VERSION ""

NS_ :

BS_:

BU_: WPC2 PSB SHVU_RR vHS_B2 FCS EMCU SLB GW_APSU GW_DLBCU RCM ARS CGW_CCU vDummy_HS_B GW_RLPSU ATS RLHV SGU PFSU GW_RRPSU ALBCU DSAU SWRC SHVU_FR RCS GW_DPSU BLTN_CAM SCM OHCL RWPC RRHV WPC HOD ASAU

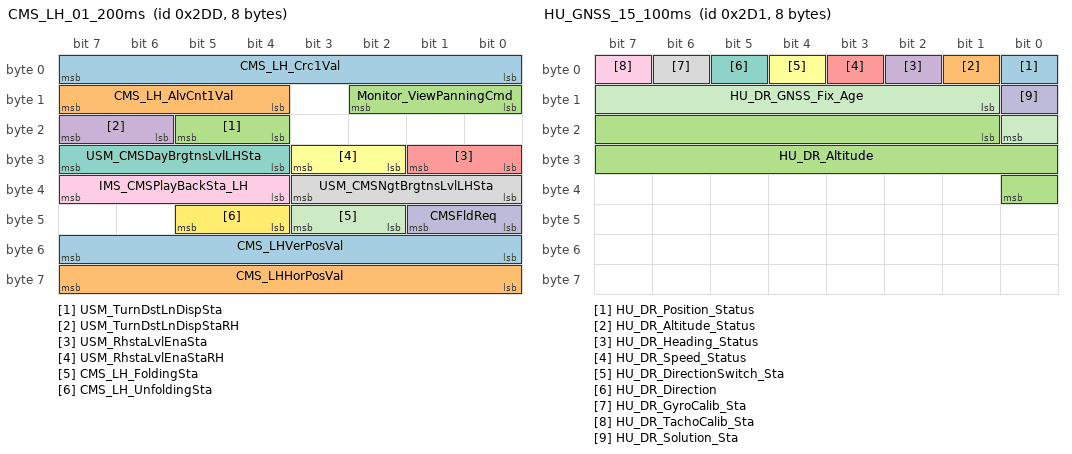
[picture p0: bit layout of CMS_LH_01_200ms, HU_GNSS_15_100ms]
BO_ 733 CMS_LH_01_200ms: 8 CGW_CCU
 SG_ CMS_LH_Crc1Val : 0|8@1+ (1,0) [0|0] ""  Vector__XXX
 SG_ CMS_LH_AlvCnt1Val : 12|4@1+ (1,0) [0|0] ""  Vector__XXX
 SG_ USM_TurnDstLnDispSta : 20|2@1+ (1,0) [0|0] ""  Vector__XXX
 SG_ USM_TurnDstLnDispStaRH : 22|2@1+ (1,0) [0|0] ""  Vector__XXX
 SG_ USM_RhstaLvlEnaSta : 24|2@1+ (1,0) [0|0] ""  Vector__XXX
 SG_ USM_RhstaLvlEnaStaRH : 26|2@1+ (1,0) [0|0] ""  Vector__XXX
 SG_ USM_CMSDayBrgtnsLvlLHSta : 28|4@1+ (1,0) [0|0] ""  Vector__XXX
 SG_ USM_CMSNgtBrgtnsLvlLHSta : 32|4@1+ (1,0) [0|0] ""  Vector__XXX
 SG_ IMS_CMSPlayBackSta_LH : 36|4@1+ (1,0) [0|0] ""  GW_DPSU
 SG_ CMSFldReq : 40|2@1+ (1,0) [0|0] ""  Vector__XXX
 SG_ CMS_LH_FoldingSta : 42|2@1+ (1,0) [0|0] ""  Vector__XXX
 SG_ CMS_LH_UnfoldingSta : 44|2@1+ (1,0) [0|0] ""  Vector__XXX
 SG_ CMS_LHVerPosVal : 48|8@1+ (0.02,0) [0|0] "V"  Vector__XXX
 SG_ CMS_LHHorPosVal : 56|8@1+ (0.02,0) [0|0] "V"  Vector__XXX
 SG_ Monitor_ViewPanningCmd : 8|3@1+ (1,0) [0|0] ""  Vector__XXX

BO_ 721 HU_GNSS_15_100ms: 8 CGW_CCU
 SG_ HU_DR_Position_Status : 0|1@1+ (1,0) [0|0] ""  Vector__XXX
 SG_ HU_DR_Altitude_Status : 1|1@1+ (1,0) [0|0] ""  Vector__XXX
 SG_ HU_DR_Altitude : 17|16@1- (1,0) [0|0] "m"  BLTN_CAM
 SG_ HU_DR_Heading_Status : 2|1@1+ (1,0) [0|0] ""  Vector__XXX
 SG_ HU_DR_Speed_Status : 3|1@1+ (1,0) [0|0] ""  Vector__XXX
 SG_ HU_DR_DirectionSwitch_Sta : 4|1@1+ (1,0) [0|0] ""  Vector__XXX
 SG_ HU_DR_Direction : 5|1@1+ (1,0) [0|0] ""  Vector__XXX
 SG_ HU_DR_GyroCalib_Sta : 6|1@1+ (1,0) [0|0] ""  Vector__XXX
 SG_ HU_DR_TachoCalib_Sta : 7|1@1+ (1,0) [0|0] ""  Vector__XXX
 SG_ HU_DR_Solution_Sta : 8|1@1+ (1,0) [0|0] ""  Vector__XXX
 SG_ HU_DR_GNSS_Fix_Age : 9|8@1+ (1,0) [0|0] "Sec"  Vector__XXX

BO_ 722 HU_GNSS_16_100ms: 8 CGW_CCU
 SG_ HU_DR_Latitude : 0|32@1- (1,0) [0|0] "¢ª"  BLTN_CAM
 SG_ HU_DR_Longitude : 32|32@1- (1,0) [0|0] "¢ª"  BLTN_CAM

BO_ 723 HU_GNSS_17_100ms: 8 CGW_CCU
 SG_ HU_DR_Heading : 0|16@1+ (1,0) [0|0] "¢ª"  BLTN_CAM
 SG_ HU_DR_Speed : 16|16@1- (0.01,0) [0|0] "m/s"  Vector__XXX

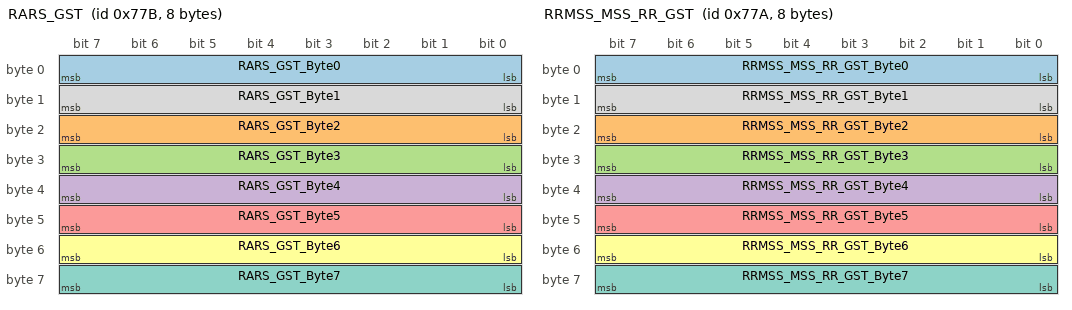
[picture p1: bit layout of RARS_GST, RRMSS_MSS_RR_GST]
BO_ 1915 RARS_GST: 8 ARS
 SG_ RARS_GST_Byte0 : 0|8@1+ (1,0) [0|0] ""  CGW_CCU
 SG_ RARS_GST_Byte2 : 16|8@1+ (1,0) [0|0] ""  CGW_CCU
 SG_ RARS_GST_Byte3 : 24|8@1+ (1,0) [0|0] ""  CGW_CCU
 SG_ RARS_GST_Byte4 : 32|8@1+ (1,0) [0|0] ""  CGW_CCU
 SG_ RARS_GST_Byte5 : 40|8@1+ (1,0) [0|0] ""  CGW_CCU
 SG_ RARS_GST_Byte6 : 48|8@1+ (1,0) [0|0] ""  CGW_CCU
 SG_ RARS_GST_Byte7 : 56|8@1+ (1,0) [0|0] ""  CGW_CCU
 SG_ RARS_GST_Byte1 : 8|8@1+ (1,0) [0|0] ""  CGW_CCU

BO_ 1914 RRMSS_MSS_RR_GST: 8 GW_RRPSU
 SG_ RRMSS_MSS_RR_GST_Byte0 : 0|8@1+ (1,0) [0|0] ""  CGW_CCU
 SG_ RRMSS_MSS_RR_GST_Byte2 : 16|8@1+ (1,0) [0|0] ""  CGW_CCU
 SG_ RRMSS_MSS_RR_GST_Byte3 : 24|8@1+ (1,0) [0|0] ""  CGW_CCU
 SG_ RRMSS_MSS_RR_GST_Byte4 : 32|8@1+ (1,0) [0|0] ""  CGW_CCU
 SG_ RRMSS_MSS_RR_GST_Byte5 : 40|8@1+ (1,0) [0|0] ""  CGW_CCU
 SG_ RRMSS_MSS_RR_GST_Byte6 : 48|8@1+ (1,0) [0|0] ""  CGW_CCU
 SG_ RRMSS_MSS_RR_GST_Byte7 : 56|8@1+ (1,0) [0|0] ""  CGW_CCU
 SG_ RRMSS_MSS_RR_GST_Byte1 : 8|8@1+ (1,0) [0|0] ""  CGW_CCU

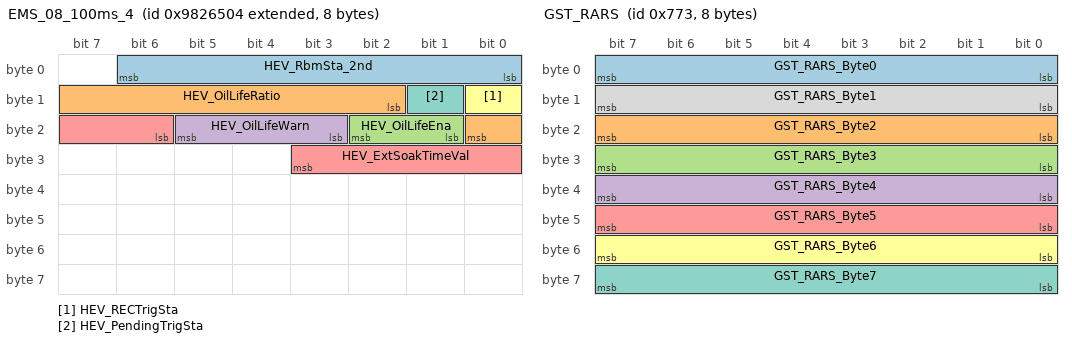
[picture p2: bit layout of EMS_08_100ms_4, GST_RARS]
BO_ 2307024132 EMS_08_100ms_4: 8 CGW_CCU
 SG_ HEV_RbmSta_2nd : 0|7@1+ (1,0) [0|0] ""  Vector__XXX
 SG_ HEV_OilLifeRatio : 10|7@1+ (1,0) [0|0] "%"  Vector__XXX
 SG_ HEV_OilLifeEna : 17|2@1+ (1,0) [0|0] ""  Vector__XXX
 SG_ HEV_OilLifeWarn : 19|3@1+ (1,0) [0|0] ""  Vector__XXX
 SG_ HEV_ExtSoakTimeVal : 22|6@1+ (5,0) [0|0] ""  Vector__XXX
 SG_ HEV_RECTrigSta : 8|1@1+ (1,0) [0|0] ""  Vector__XXX
 SG_ HEV_PendingTrigSta : 9|1@1+ (1,0) [0|0] ""  Vector__XXX

BO_ 1907 GST_RARS: 8 CGW_CCU
 SG_ GST_RARS_Byte0 : 0|8@1+ (1,0) [0|0] ""  ARS
 SG_ GST_RARS_Byte2 : 16|8@1+ (1,0) [0|0] ""  ARS
 SG_ GST_RARS_Byte3 : 24|8@1+ (1,0) [0|0] ""  ARS
 SG_ GST_RARS_Byte4 : 32|8@1+ (1,0) [0|0] ""  ARS
 SG_ GST_RARS_Byte5 : 40|8@1+ (1,0) [0|0] ""  ARS
 SG_ GST_RARS_Byte6 : 48|8@1+ (1,0) [0|0] ""  ARS
 SG_ GST_RARS_Byte7 : 56|8@1+ (1,0) [0|0] ""  ARS
 SG_ GST_RARS_Byte1 : 8|8@1+ (1,0) [0|0] ""  ARS

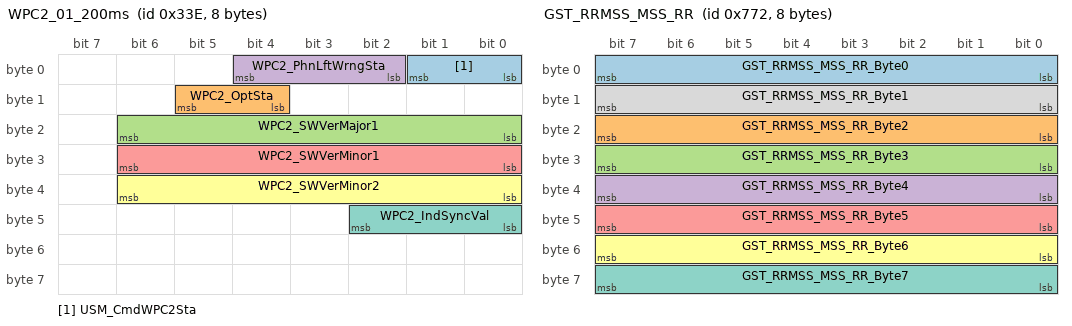
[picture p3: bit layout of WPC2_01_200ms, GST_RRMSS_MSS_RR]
BO_ 830 WPC2_01_200ms: 8 WPC2
 SG_ USM_CmdWPC2Sta : 0|2@1+ (1,0) [0|0] ""  CGW_CCU
 SG_ WPC2_OptSta : 12|2@1+ (1,0) [0|0] ""  CGW_CCU
 SG_ WPC2_SWVerMajor1 : 16|7@1+ (1,0) [0|0] ""  CGW_CCU
 SG_ WPC2_PhnLftWrngSta : 2|3@1+ (1,0) [0|0] ""  CGW_CCU
 SG_ WPC2_SWVerMinor1 : 24|7@1+ (1,0) [0|0] ""  CGW_CCU
 SG_ WPC2_SWVerMinor2 : 32|7@1+ (1,0) [0|0] ""  CGW_CCU
 SG_ WPC2_IndSyncVal : 40|3@1+ (1,0) [0|0] ""  RWPC,WPC

BO_ 1906 GST_RRMSS_MSS_RR: 8 CGW_CCU
 SG_ GST_RRMSS_MSS_RR_Byte0 : 0|8@1+ (1,0) [0|0] ""  GW_RRPSU
 SG_ GST_RRMSS_MSS_RR_Byte2 : 16|8@1+ (1,0) [0|0] ""  GW_RRPSU
 SG_ GST_RRMSS_MSS_RR_Byte3 : 24|8@1+ (1,0) [0|0] ""  GW_RRPSU
 SG_ GST_RRMSS_MSS_RR_Byte4 : 32|8@1+ (1,0) [0|0] ""  GW_RRPSU
 SG_ GST_RRMSS_MSS_RR_Byte5 : 40|8@1+ (1,0) [0|0] ""  GW_RRPSU
 SG_ GST_RRMSS_MSS_RR_Byte6 : 48|8@1+ (1,0) [0|0] ""  GW_RRPSU
 SG_ GST_RRMSS_MSS_RR_Byte7 : 56|8@1+ (1,0) [0|0] ""  GW_RRPSU
 SG_ GST_RRMSS_MSS_RR_Byte1 : 8|8@1+ (1,0) [0|0] ""  GW_RRPSU

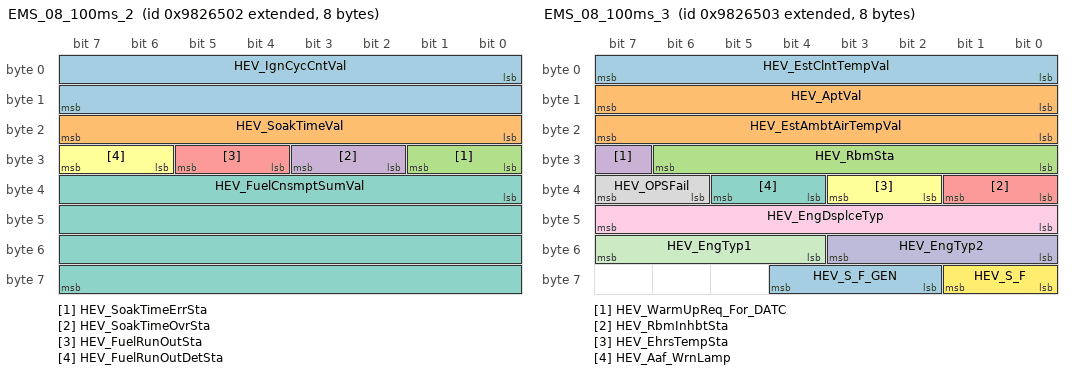
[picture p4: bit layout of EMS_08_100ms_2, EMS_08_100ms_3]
BO_ 2307024130 EMS_08_100ms_2: 8 CGW_CCU
 SG_ HEV_IgnCycCntVal : 0|16@1+ (1,0) [0|0] ""  Vector__XXX
 SG_ HEV_SoakTimeVal : 16|8@1+ (1,0) [0|0] "Min"  Vector__XXX
 SG_ HEV_SoakTimeErrSta : 24|2@1+ (1,0) [0|0] ""  Vector__XXX
 SG_ HEV_SoakTimeOvrSta : 26|2@1+ (1,0) [0|0] ""  Vector__XXX
 SG_ HEV_FuelRunOutSta : 28|2@1+ (1,0) [0|0] ""  Vector__XXX
 SG_ HEV_FuelRunOutDetSta : 30|2@1+ (1,0) [0|0] ""  Vector__XXX
 SG_ HEV_FuelCnsmptSumVal : 32|32@1+ (1.280018E-4,0) [0|0] "ml"  Vector__XXX

BO_ 2307024131 EMS_08_100ms_3: 8 CGW_CCU
 SG_ HEV_EstClntTempVal : 0|8@1+ (0.75,-48) [0|0] "¡É"  Vector__XXX
 SG_ HEV_EstAmbtAirTempVal : 16|8@1+ (0.75,-48) [0|0] "¡É"  Vector__XXX
 SG_ HEV_RbmSta : 24|7@1+ (1,0) [0|0] ""  Vector__XXX
 SG_ HEV_WarmUpReq_For_DATC : 31|1@1+ (1,0) [0|0] ""  Vector__XXX
 SG_ HEV_RbmInhbtSta : 32|2@1+ (1,0) [0|0] ""  Vector__XXX
 SG_ HEV_EhrsTempSta : 34|2@1+ (1,0) [0|0] ""  Vector__XXX
 SG_ HEV_Aaf_WrnLamp : 36|2@1+ (1,0) [0|0] ""  Vector__XXX
 SG_ HEV_OPSFail : 38|2@1+ (1,0) [0|0] ""  Vector__XXX
 SG_ HEV_EngDsplceTyp : 40|8@1+ (0.1,0) [0|0] "liter"  Vector__XXX
 SG_ HEV_EngTyp2 : 48|4@1+ (1,0) [0|0] ""  Vector__XXX
 SG_ HEV_EngTyp1 : 52|4@1+ (1,0) [0|0] ""  Vector__XXX
 SG_ HEV_S_F : 56|2@1+ (1,0) [0|0] ""  Vector__XXX
 SG_ HEV_S_F_GEN : 58|3@1+ (1,0) [0|0] ""  Vector__XXX
 SG_ HEV_AptVal : 8|8@1+ (2,0) [0|0] "PSI"  Vector__XXX

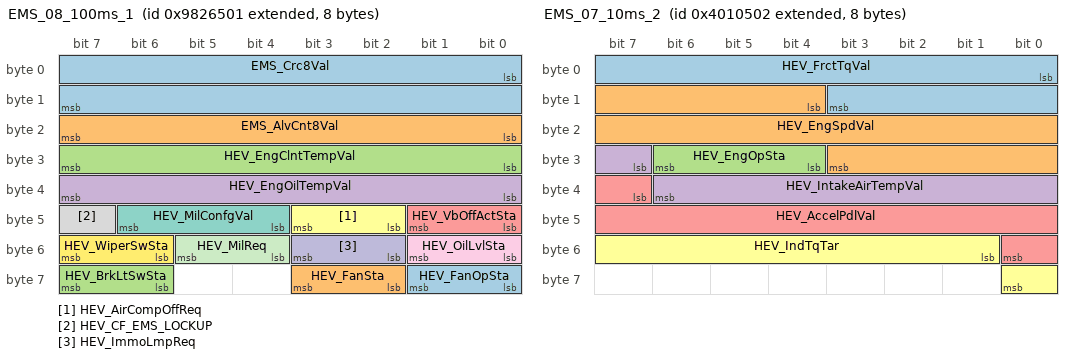
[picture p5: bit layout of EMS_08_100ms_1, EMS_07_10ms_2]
BO_ 2307024129 EMS_08_100ms_1: 8 CGW_CCU
 SG_ EMS_Crc8Val : 0|16@1+ (1,0) [0|0] ""  Vector__XXX
 SG_ EMS_AlvCnt8Val : 16|8@1+ (1,0) [0|0] ""  Vector__XXX
 SG_ HEV_EngClntTempVal : 24|8@1+ (0.75,-48) [0|0] "¡É"  Vector__XXX
 SG_ HEV_EngOilTempVal : 32|8@1+ (1,-40) [0|0] "¡É"  Vector__XXX
 SG_ HEV_VbOffActSta : 40|2@1+ (1,0) [0|0] ""  Vector__XXX
 SG_ HEV_AirCompOffReq : 42|2@1+ (1,0) [0|0] ""  Vector__XXX
 SG_ HEV_MilConfgVal : 44|3@1+ (1,0) [0|0] ""  Vector__XXX
 SG_ HEV_CF_EMS_LOCKUP : 47|1@1+ (1,0) [0|0] ""  Vector__XXX
 SG_ HEV_OilLvlSta : 48|2@1+ (1,0) [0|0] ""  Vector__XXX
 SG_ HEV_ImmoLmpReq : 50|2@1+ (1,0) [0|0] ""  Vector__XXX
 SG_ HEV_MilReq : 52|2@1+ (1,0) [0|0] ""  Vector__XXX
 SG_ HEV_WiperSwSta : 54|2@1+ (1,0) [0|0] ""  Vector__XXX
 SG_ HEV_FanOpSta : 56|2@1+ (1,0) [0|0] ""  Vector__XXX
 SG_ HEV_FanSta : 58|2@1+ (1,0) [0|0] ""  Vector__XXX
 SG_ HEV_BrkLtSwSta : 62|2@1+ (1,0) [0|0] ""  BLTN_CAM

BO_ 2214659332 EMS_07_10ms_4: 8 CGW_CCU

BO_ 2214659331 EMS_07_10ms_3: 8 CGW_CCU

BO_ 2214659330 EMS_07_10ms_2: 8 CGW_CCU
 SG_ HEV_FrctTqVal : 0|12@1+ (0.1,0) [0|0] "Nm"  Vector__XXX
 SG_ HEV_EngSpdVal : 12|16@1+ (0.25,0) [0|0] "rpm"  Vector__XXX
 SG_ HEV_EngOpSta : 28|3@1+ (1,0) [0|0] ""  PFSU,RWPC,WPC,WPC2
 SG_ HEV_IntakeAirTempVal : 31|8@1+ (0.75,-48) [0|0] "¡É"  Vector__XXX
 SG_ HEV_AccelPdlVal : 39|10@1+ (0.09784,0) [0|0] "%"  BLTN_CAM
 SG_ HEV_IndTqTar : 49|8@1+ (0.3906,0) [0|0] "%"  Vector__XXX

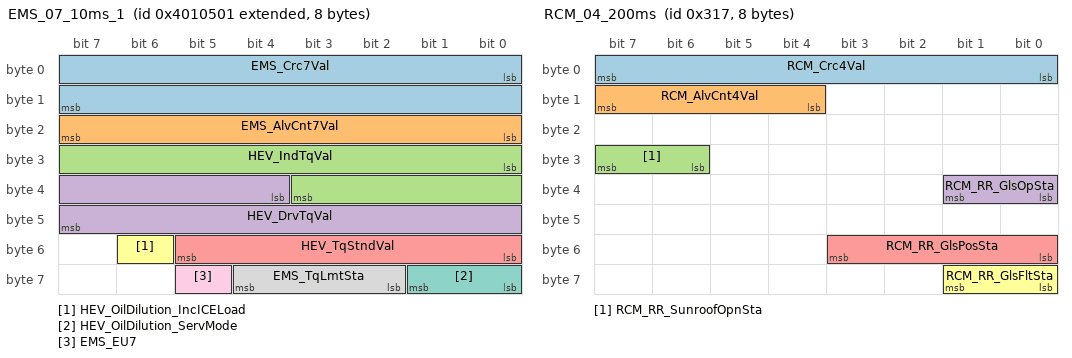
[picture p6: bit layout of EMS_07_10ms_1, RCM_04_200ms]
BO_ 2214659329 EMS_07_10ms_1: 8 CGW_CCU
 SG_ EMS_Crc7Val : 0|16@1+ (1,0) [0|0] ""  Vector__XXX
 SG_ EMS_AlvCnt7Val : 16|8@1+ (1,0) [0|0] ""  Vector__XXX
 SG_ HEV_IndTqVal : 24|12@1+ (0.1,0) [0|0] "Nm"  Vector__XXX
 SG_ HEV_DrvTqVal : 36|12@1+ (0.390625,0) [0|0] "%"  Vector__XXX
 SG_ HEV_TqStndVal : 48|6@1+ (10,0) [0|0] "Nm"  Vector__XXX
 SG_ HEV_OilDilution_IncICELoad : 54|1@1+ (1,0) [0|0] ""  Vector__XXX
 SG_ HEV_OilDilution_ServMode : 56|2@1+ (1,0) [0|0] ""  Vector__XXX
 SG_ EMS_TqLmtSta : 58|3@1+ (1,0) [0|0] ""  Vector__XXX
 SG_ EMS_EU7 : 61|1@1+ (1,0) [0|0] ""  Vector__XXX

BO_ 791 RCM_04_200ms: 8 RCM
 SG_ RCM_Crc4Val : 0|8@1+ (1,0) [0|0] ""  Vector__XXX
 SG_ RCM_AlvCnt4Val : 12|4@1+ (1,0) [0|0] ""  Vector__XXX
 SG_ RCM_RR_SunroofOpnSta : 30|2@1+ (1,0) [0|0] ""  CGW_CCU
 SG_ RCM_RR_GlsOpSta : 32|2@1+ (1,0) [0|0] ""  CGW_CCU
 SG_ RCM_RR_GlsPosSta : 48|4@1+ (1,0) [0|0] ""  CGW_CCU
 SG_ RCM_RR_GlsFltSta : 56|2@1+ (1,0) [0|0] ""  CGW_CCU

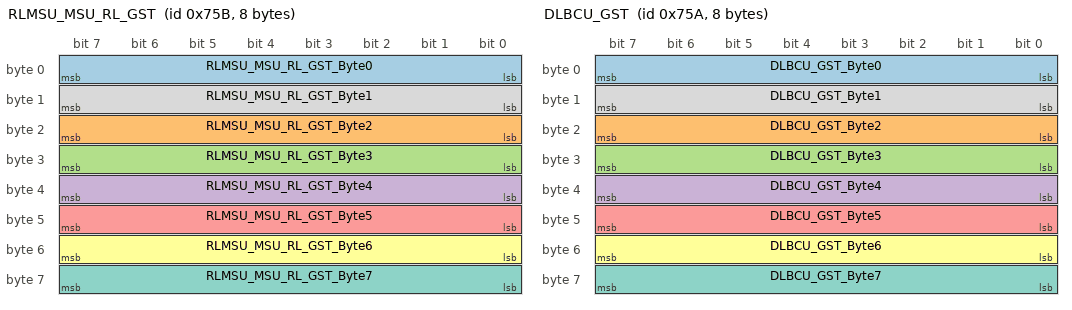
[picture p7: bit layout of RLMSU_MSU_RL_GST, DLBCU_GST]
BO_ 1883 RLMSU_MSU_RL_GST: 8 GW_RLPSU
 SG_ RLMSU_MSU_RL_GST_Byte0 : 0|8@1+ (1,0) [0|0] ""  CGW_CCU
 SG_ RLMSU_MSU_RL_GST_Byte2 : 16|8@1+ (1,0) [0|0] ""  CGW_CCU
 SG_ RLMSU_MSU_RL_GST_Byte3 : 24|8@1+ (1,0) [0|0] ""  CGW_CCU
 SG_ RLMSU_MSU_RL_GST_Byte4 : 32|8@1+ (1,0) [0|0] ""  CGW_CCU
 SG_ RLMSU_MSU_RL_GST_Byte5 : 40|8@1+ (1,0) [0|0] ""  CGW_CCU
 SG_ RLMSU_MSU_RL_GST_Byte6 : 48|8@1+ (1,0) [0|0] ""  CGW_CCU
 SG_ RLMSU_MSU_RL_GST_Byte7 : 56|8@1+ (1,0) [0|0] ""  CGW_CCU
 SG_ RLMSU_MSU_RL_GST_Byte1 : 8|8@1+ (1,0) [0|0] ""  CGW_CCU

BO_ 1882 DLBCU_GST: 8 GW_DLBCU
 SG_ DLBCU_GST_Byte0 : 0|8@1+ (1,0) [0|0] ""  CGW_CCU
 SG_ DLBCU_GST_Byte2 : 16|8@1+ (1,0) [0|0] ""  CGW_CCU
 SG_ DLBCU_GST_Byte3 : 24|8@1+ (1,0) [0|0] ""  CGW_CCU
 SG_ DLBCU_GST_Byte4 : 32|8@1+ (1,0) [0|0] ""  CGW_CCU
 SG_ DLBCU_GST_Byte5 : 40|8@1+ (1,0) [0|0] ""  CGW_CCU
 SG_ DLBCU_GST_Byte6 : 48|8@1+ (1,0) [0|0] ""  CGW_CCU
 SG_ DLBCU_GST_Byte7 : 56|8@1+ (1,0) [0|0] ""  CGW_CCU
 SG_ DLBCU_GST_Byte1 : 8|8@1+ (1,0) [0|0] ""  CGW_CCU

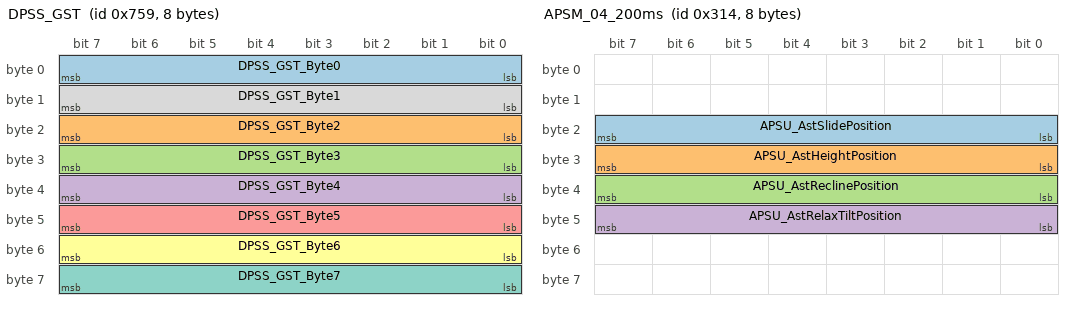
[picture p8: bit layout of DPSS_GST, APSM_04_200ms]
BO_ 1881 DPSS_GST: 8 GW_DPSU
 SG_ DPSS_GST_Byte0 : 0|8@1+ (1,0) [0|0] ""  CGW_CCU
 SG_ DPSS_GST_Byte2 : 16|8@1+ (1,0) [0|0] ""  CGW_CCU
 SG_ DPSS_GST_Byte3 : 24|8@1+ (1,0) [0|0] ""  CGW_CCU
 SG_ DPSS_GST_Byte4 : 32|8@1+ (1,0) [0|0] ""  CGW_CCU
 SG_ DPSS_GST_Byte5 : 40|8@1+ (1,0) [0|0] ""  CGW_CCU
 SG_ DPSS_GST_Byte6 : 48|8@1+ (1,0) [0|0] ""  CGW_CCU
 SG_ DPSS_GST_Byte7 : 56|8@1+ (1,0) [0|0] ""  CGW_CCU
 SG_ DPSS_GST_Byte1 : 8|8@1+ (1,0) [0|0] ""  CGW_CCU

BO_ 788 APSM_04_200ms: 8 GW_APSU
 SG_ APSU_AstSlidePosition : 16|8@1+ (2,0) [0|0] ""  CGW_CCU,GW_RLPSU,GW_RRPSU
 SG_ APSU_AstHeightPosition : 24|8@1+ (1,0) [0|0] ""  CGW_CCU,GW_RLPSU,GW_RRPSU
 SG_ APSU_AstReclinePosition : 32|8@1+ (1,0) [0|0] ""  CGW_CCU,GW_RLPSU,GW_RRPSU
 SG_ APSU_AstRelaxTiltPosition : 40|8@1+ (1,0) [0|0] ""  CGW_CCU,GW_RLPSU,GW_RRPSU

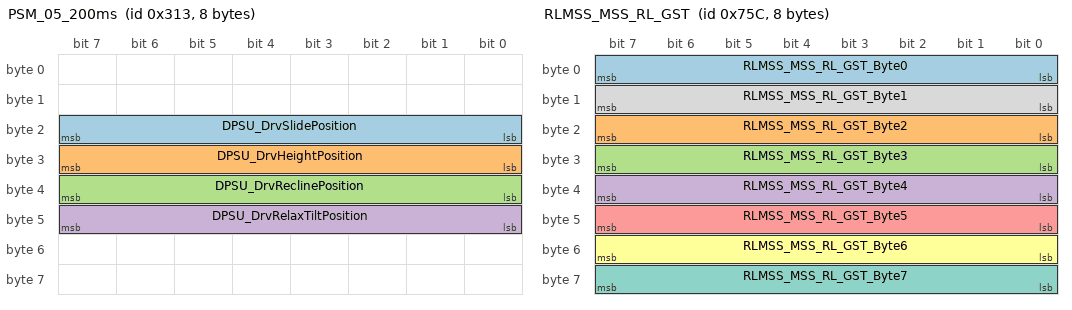
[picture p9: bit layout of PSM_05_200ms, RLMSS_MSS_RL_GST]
BO_ 787 PSM_05_200ms: 8 GW_DPSU
 SG_ DPSU_DrvSlidePosition : 16|8@1+ (2,0) [0|0] ""  CGW_CCU,GW_RLPSU,GW_RRPSU
 SG_ DPSU_DrvHeightPosition : 24|8@1+ (1,0) [0|0] ""  CGW_CCU,GW_RLPSU,GW_RRPSU
 SG_ DPSU_DrvReclinePosition : 32|8@1+ (1,0) [0|0] ""  CGW_CCU,GW_RLPSU,GW_RRPSU
 SG_ DPSU_DrvRelaxTiltPosition : 40|8@1+ (1,0) [0|0] ""  CGW_CCU,GW_RLPSU,GW_RRPSU

BO_ 1884 RLMSS_MSS_RL_GST: 8 GW_RLPSU
 SG_ RLMSS_MSS_RL_GST_Byte0 : 0|8@1+ (1,0) [0|0] ""  CGW_CCU
 SG_ RLMSS_MSS_RL_GST_Byte2 : 16|8@1+ (1,0) [0|0] ""  CGW_CCU
 SG_ RLMSS_MSS_RL_GST_Byte3 : 24|8@1+ (1,0) [0|0] ""  CGW_CCU
 SG_ RLMSS_MSS_RL_GST_Byte4 : 32|8@1+ (1,0) [0|0] ""  CGW_CCU
 SG_ RLMSS_MSS_RL_GST_Byte5 : 40|8@1+ (1,0) [0|0] ""  CGW_CCU
 SG_ RLMSS_MSS_RL_GST_Byte6 : 48|8@1+ (1,0) [0|0] ""  CGW_CCU
 SG_ RLMSS_MSS_RL_GST_Byte7 : 56|8@1+ (1,0) [0|0] ""  CGW_CCU
 SG_ RLMSS_MSS_RL_GST_Byte1 : 8|8@1+ (1,0) [0|0] ""  CGW_CCU

BO_ 799 SBCM_DRV_01_200ms: 8 CGW_CCU
 SG_ SBCM_DRV_Crc1Val : 0|8@1+ (1,0) [0|0] ""  Vector__XXX
 SG_ DRV_CrashUnlockCmd : 10|1@1+ (1,0) [0|0] ""  BLTN_CAM
 SG_ C_ApprOpenStatus : 11|1@1+ (1,0) [0|0] ""  Vector__XXX
 SG_ SBCM_DRV_AlvCnt1Val : 12|4@1+ (1,0) [0|0] ""  Vector__XXX
 SG_ DoorLock_DrvKeyLkSwSta_SBCM : 16|2@1+ (1,0) [0|0] ""  Vector__XXX
 SG_ DoorLock_DrvKeyUnLkSwSta_SBCM : 18|2@1+ (1,0) [0|0] ""  Vector__XXX
 SG_ Warn_DrvDrSwSta_SBCM : 20|2@1+ (1,0) [0|0] ""  ATS,BLTN_CAM,GW_DPSU,PSB,RWPC,WPC,WPC2
 SG_ DoorLock_DrvDrUnLkSta_SBCM : 22|2@1+ (1,0) [0|0] ""  ATS,GW_DPSU
 SG_ DRV_SEAWarn_LH : 24|2@1+ (1,0) [0|0] ""  Vector__XXX
 SG_ DRV_SEAWarn_RH : 26|2@1+ (1,0) [0|0] ""  Vector__XXX
 SG_ DRV_SEWWarn_LH : 28|2@1+ (1,0) [0|0] ""  Vector__XXX
 SG_ DRV_SEWWarn_RH : 30|2@1+ (1,0) [0|0] ""  Vector__XXX
 SG_ DRV_MRActivationAlarm : 32|2@1+ (1,0) [0|0] ""  Vector__XXX
 SG_ DRV_ReleaseWarn : 34|2@1+ (1,0) [0|0] ""  Vector__XXX
 SG_ Latch_TypeOption_DRV : 36|2@1+ (1,0) [0|0] ""  GW_APSU,GW_DPSU,GW_RLPSU,GW_RRPSU,RWPC,WPC,WPC2
 SG_ DRV_SWFailAlarm : 38|2@1+ (1,0) [0|0] ""  Vector__XXX
 SG_ USM_PwrDRApprOpnSetSta : 40|2@1+ (1,0) [0|0] ""  Vector__XXX
 SG_ USM_PwrDRApprOpnSetOpt : 42|2@1+ (1,0) [0|0] ""  Vector__XXX
 SG_ USM_PwrDRCloseByRKELockSta : 44|2@1+ (1,0) [0|0] ""  Vector__XXX
 SG_ USM_PwrDRCloseByRKELockOpt : 46|2@1+ (1,0) [0|0] ""  Vector__XXX
 SG_ USM_PwrDRCloseByBrakeSta : 48|2@1+ (1,0) [0|0] ""  Vector__XXX
 SG_ USM_PwrDRCloseByBrakeOpt : 50|2@1+ (1,0) [0|0] ""  Vector__XXX
 SG_ USM_PwrDRBuzzerSta : 52|2@1+ (1,0) [0|0] ""  Vector__XXX
 SG_ USM_PwrDRBuzzerOpt : 54|2@1+ (1,0) [0|0] ""  Vector__XXX
 SG_ PDS_TypeOption_DRV : 56|2@1+ (1,0) [0|0] ""  Vector__XXX
 SG_ C_DrvDoorApproachOpen : 58|2@1+ (1,0) [0|0] ""  Vector__XXX
 SG_ C_DrvDoorApproachClose : 60|2@1+ (1,0) [0|0] ""  Vector__XXX
 SG_ DoorLock_PDSLkSwSta_DRV : 62|2@1+ (1,0) [0|0] ""  Vector__XXX
 SG_ DRVDoorPushAlarm : 8|2@1+ (1,0) [0|0] ""  Vector__XXX

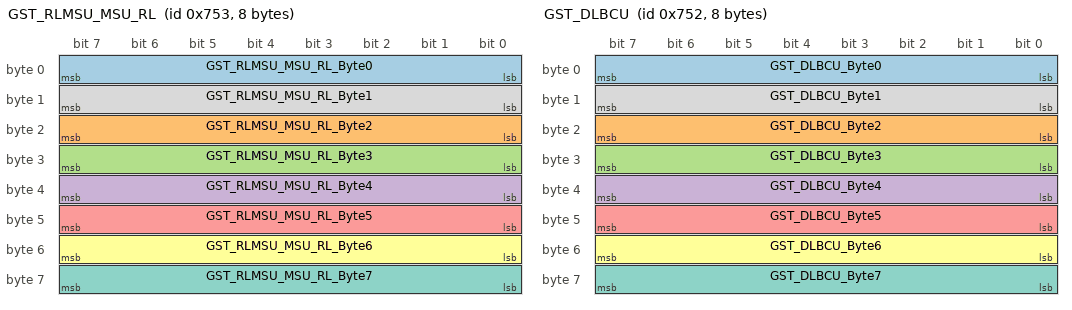
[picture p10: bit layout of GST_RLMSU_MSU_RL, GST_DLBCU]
BO_ 1875 GST_RLMSU_MSU_RL: 8 CGW_CCU
 SG_ GST_RLMSU_MSU_RL_Byte0 : 0|8@1+ (1,0) [0|0] ""  GW_RLPSU
 SG_ GST_RLMSU_MSU_RL_Byte2 : 16|8@1+ (1,0) [0|0] ""  GW_RLPSU
 SG_ GST_RLMSU_MSU_RL_Byte3 : 24|8@1+ (1,0) [0|0] ""  GW_RLPSU
 SG_ GST_RLMSU_MSU_RL_Byte4 : 32|8@1+ (1,0) [0|0] ""  GW_RLPSU
 SG_ GST_RLMSU_MSU_RL_Byte5 : 40|8@1+ (1,0) [0|0] ""  GW_RLPSU
 SG_ GST_RLMSU_MSU_RL_Byte6 : 48|8@1+ (1,0) [0|0] ""  GW_RLPSU
 SG_ GST_RLMSU_MSU_RL_Byte7 : 56|8@1+ (1,0) [0|0] ""  GW_RLPSU
 SG_ GST_RLMSU_MSU_RL_Byte1 : 8|8@1+ (1,0) [0|0] ""  GW_RLPSU

BO_ 1874 GST_DLBCU: 8 CGW_CCU
 SG_ GST_DLBCU_Byte0 : 0|8@1+ (1,0) [0|0] ""  GW_DLBCU
 SG_ GST_DLBCU_Byte2 : 16|8@1+ (1,0) [0|0] ""  GW_DLBCU
 SG_ GST_DLBCU_Byte3 : 24|8@1+ (1,0) [0|0] ""  GW_DLBCU
 SG_ GST_DLBCU_Byte4 : 32|8@1+ (1,0) [0|0] ""  GW_DLBCU
 SG_ GST_DLBCU_Byte5 : 40|8@1+ (1,0) [0|0] ""  GW_DLBCU
 SG_ GST_DLBCU_Byte6 : 48|8@1+ (1,0) [0|0] ""  GW_DLBCU
 SG_ GST_DLBCU_Byte7 : 56|8@1+ (1,0) [0|0] ""  GW_DLBCU
 SG_ GST_DLBCU_Byte1 : 8|8@1+ (1,0) [0|0] ""  GW_DLBCU

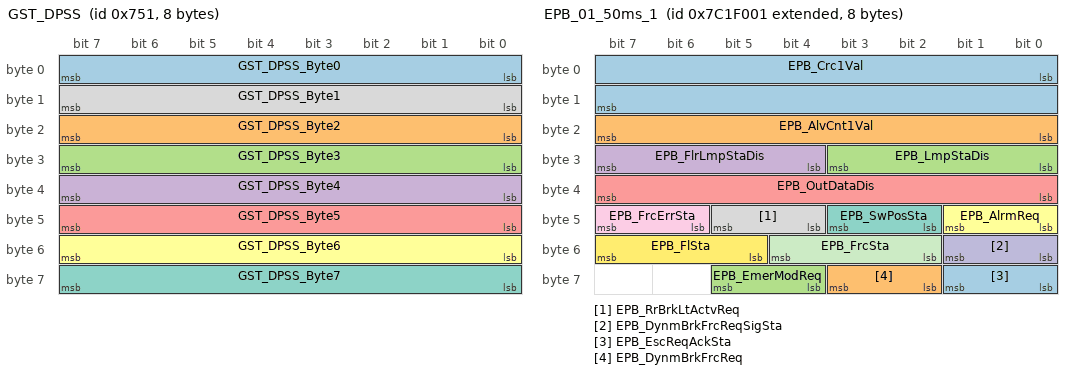
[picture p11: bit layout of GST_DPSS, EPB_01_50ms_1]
BO_ 1873 GST_DPSS: 8 CGW_CCU
 SG_ GST_DPSS_Byte0 : 0|8@1+ (1,0) [0|0] ""  GW_DPSU
 SG_ GST_DPSS_Byte2 : 16|8@1+ (1,0) [0|0] ""  GW_DPSU
 SG_ GST_DPSS_Byte3 : 24|8@1+ (1,0) [0|0] ""  GW_DPSU
 SG_ GST_DPSS_Byte4 : 32|8@1+ (1,0) [0|0] ""  GW_DPSU
 SG_ GST_DPSS_Byte5 : 40|8@1+ (1,0) [0|0] ""  GW_DPSU
 SG_ GST_DPSS_Byte6 : 48|8@1+ (1,0) [0|0] ""  GW_DPSU
 SG_ GST_DPSS_Byte7 : 56|8@1+ (1,0) [0|0] ""  GW_DPSU
 SG_ GST_DPSS_Byte1 : 8|8@1+ (1,0) [0|0] ""  GW_DPSU

BO_ 2277634049 EPB_01_50ms_1: 8 CGW_CCU
 SG_ EPB_Crc1Val : 0|16@1+ (1,0) [0|0] ""  Vector__XXX
 SG_ EPB_AlvCnt1Val : 16|8@1+ (1,0) [0|0] ""  Vector__XXX
 SG_ EPB_LmpStaDis : 24|4@1+ (1,0) [0|0] ""  GW_APSU,GW_DPSU,GW_RLPSU,GW_RRPSU,PFSU,RLHV,RRHV
 SG_ EPB_FlrLmpStaDis : 28|4@1+ (1,0) [0|0] ""  Vector__XXX
 SG_ EPB_OutDataDis : 32|8@1+ (1,0) [0|0] ""  Vector__XXX
 SG_ EPB_AlrmReq : 40|2@1+ (1,0) [0|0] ""  Vector__XXX
 SG_ EPB_SwPosSta : 42|2@1+ (1,0) [0|0] ""  Vector__XXX
 SG_ EPB_RrBrkLtActvReq : 44|2@1+ (1,0) [0|0] ""  Vector__XXX
 SG_ EPB_FrcErrSta : 46|2@1+ (1,0) [0|0] ""  Vector__XXX
 SG_ EPB_DynmBrkFrcReqSigSta : 48|2@1+ (1,0) [0|0] ""  Vector__XXX
 SG_ EPB_FrcSta : 50|3@1+ (1,0) [0|0] ""  Vector__XXX
 SG_ EPB_FlSta : 53|3@1+ (1,0) [0|0] ""  Vector__XXX
 SG_ EPB_EscReqAckSta : 56|2@1+ (1,0) [0|0] ""  Vector__XXX
 SG_ EPB_DynmBrkFrcReq : 58|2@1+ (1,0) [0|0] ""  Vector__XXX
 SG_ EPB_EmerModReq : 60|2@1+ (1,0) [0|0] ""  Vector__XXX

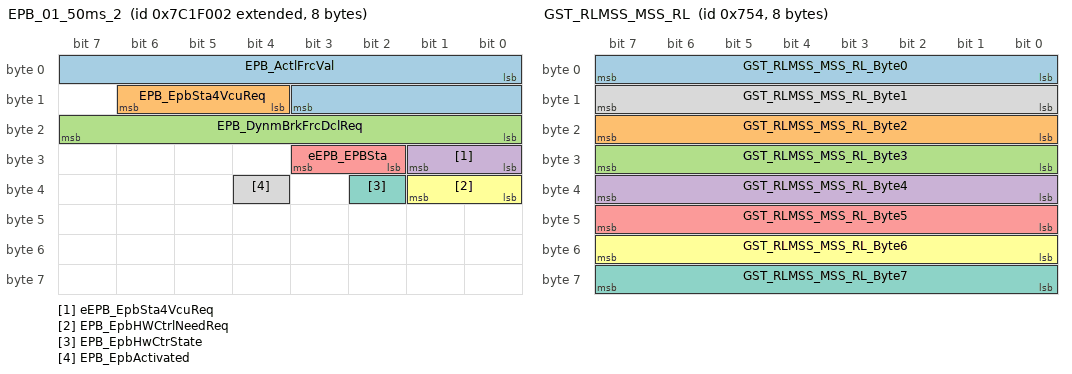
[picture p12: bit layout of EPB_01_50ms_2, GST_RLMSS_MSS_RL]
BO_ 2277634050 EPB_01_50ms_2: 8 CGW_CCU
 SG_ EPB_ActlFrcVal : 0|12@1+ (1,-1000) [0|0] ""  Vector__XXX
 SG_ EPB_EpbSta4VcuReq : 12|3@1+ (1,0) [0|0] ""  Vector__XXX
 SG_ EPB_DynmBrkFrcDclReq : 16|8@1+ (0.01,0) [0|0] "g"  Vector__XXX
 SG_ eEPB_EpbSta4VcuReq : 24|2@1+ (1,0) [0|0] ""  Vector__XXX
 SG_ eEPB_EPBSta : 26|2@1+ (1,0) [0|0] ""  Vector__XXX
 SG_ EPB_EpbHWCtrlNeedReq : 32|2@1+ (1,0) [0|0] ""  Vector__XXX
 SG_ EPB_EpbHwCtrState : 34|1@1+ (1,0) [0|0] ""  Vector__XXX
 SG_ EPB_EpbActivated : 36|1@1+ (1,0) [0|0] ""  Vector__XXX

BO_ 1876 GST_RLMSS_MSS_RL: 8 CGW_CCU
 SG_ GST_RLMSS_MSS_RL_Byte0 : 0|8@1+ (1,0) [0|0] ""  GW_RLPSU
 SG_ GST_RLMSS_MSS_RL_Byte2 : 16|8@1+ (1,0) [0|0] ""  GW_RLPSU
 SG_ GST_RLMSS_MSS_RL_Byte3 : 24|8@1+ (1,0) [0|0] ""  GW_RLPSU
 SG_ GST_RLMSS_MSS_RL_Byte4 : 32|8@1+ (1,0) [0|0] ""  GW_RLPSU
 SG_ GST_RLMSS_MSS_RL_Byte5 : 40|8@1+ (1,0) [0|0] ""  GW_RLPSU
 SG_ GST_RLMSS_MSS_RL_Byte6 : 48|8@1+ (1,0) [0|0] ""  GW_RLPSU
 SG_ GST_RLMSS_MSS_RL_Byte7 : 56|8@1+ (1,0) [0|0] ""  GW_RLPSU
 SG_ GST_RLMSS_MSS_RL_Byte1 : 8|8@1+ (1,0) [0|0] ""  GW_RLPSU

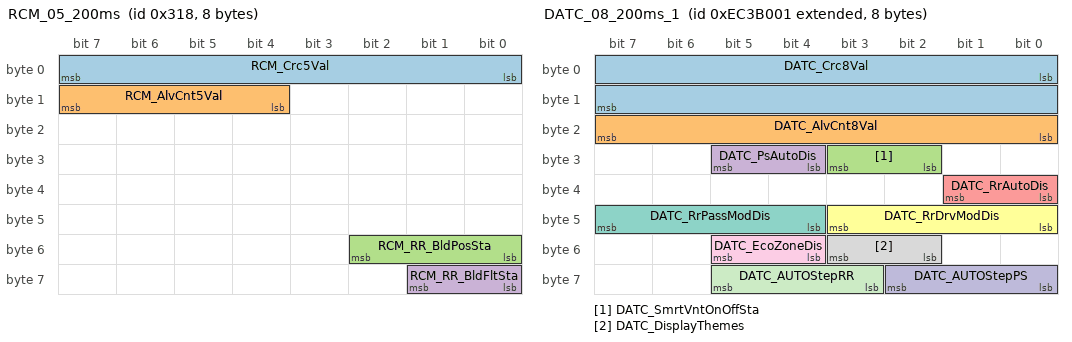
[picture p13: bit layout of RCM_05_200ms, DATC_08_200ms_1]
BO_ 792 RCM_05_200ms: 8 RCM
 SG_ RCM_Crc5Val : 0|8@1+ (1,0) [0|0] ""  Vector__XXX
 SG_ RCM_AlvCnt5Val : 12|4@1+ (1,0) [0|0] ""  Vector__XXX
 SG_ RCM_RR_BldPosSta : 48|3@1+ (1,0) [0|0] ""  CGW_CCU,SGU
 SG_ RCM_RR_BldFltSta : 56|2@1+ (1,0) [0|0] ""  CGW_CCU

BO_ 2395189249 DATC_08_200ms_1: 8 CGW_CCU
 SG_ DATC_Crc8Val : 0|16@1+ (1,0) [0|0] ""  Vector__XXX
 SG_ DATC_AlvCnt8Val : 16|8@1+ (1,0) [0|0] ""  Vector__XXX
 SG_ DATC_SmrtVntOnOffSta : 26|2@1+ (1,0) [0|0] ""  Vector__XXX
 SG_ DATC_PsAutoDis : 28|2@1+ (1,0) [0|0] ""  ATS
 SG_ DATC_RrAutoDis : 32|2@1+ (1,0) [0|0] ""  ATS
 SG_ DATC_RrDrvModDis : 40|4@1+ (1,0) [0|0] ""  ATS
 SG_ DATC_RrPassModDis : 44|4@1+ (1,0) [0|0] ""  ATS
 SG_ DATC_DisplayThemes : 50|2@1+ (1,0) [0|0] ""  Vector__XXX
 SG_ DATC_EcoZoneDis : 52|2@1+ (1,0) [0|0] ""  Vector__XXX
 SG_ DATC_AUTOStepPS : 56|3@1+ (1,0) [0|0] ""  ATS
 SG_ DATC_AUTOStepRR : 59|3@1+ (1,0) [0|0] ""  ATS

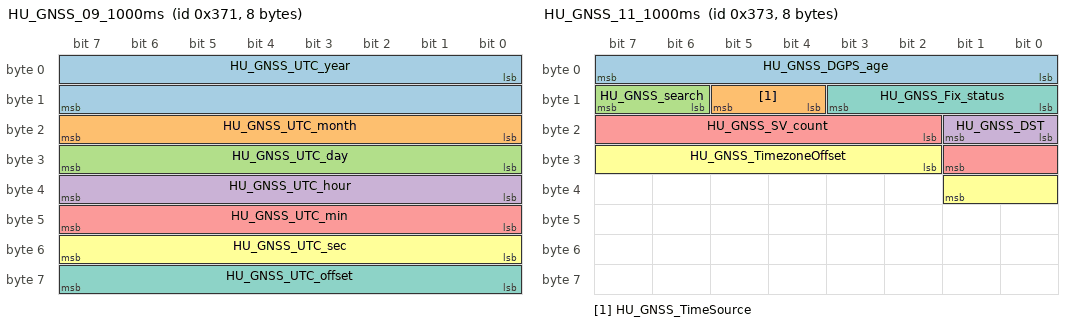
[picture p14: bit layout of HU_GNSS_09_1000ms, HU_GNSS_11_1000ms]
BO_ 881 HU_GNSS_09_1000ms: 8 CGW_CCU
 SG_ HU_GNSS_UTC_year : 0|16@1+ (1,0) [0|0] ""  BLTN_CAM
 SG_ HU_GNSS_UTC_month : 16|8@1+ (1,0) [0|0] ""  BLTN_CAM
 SG_ HU_GNSS_UTC_day : 24|8@1+ (1,0) [0|0] ""  BLTN_CAM
 SG_ HU_GNSS_UTC_hour : 32|8@1+ (1,0) [0|0] ""  BLTN_CAM
 SG_ HU_GNSS_UTC_min : 40|8@1+ (1,0) [0|0] ""  BLTN_CAM
 SG_ HU_GNSS_UTC_sec : 48|8@1+ (1,0) [0|0] ""  BLTN_CAM
 SG_ HU_GNSS_UTC_offset : 56|8@1+ (1,0) [0|0] "Sec"  BLTN_CAM

BO_ 883 HU_GNSS_11_1000ms: 8 CGW_CCU
 SG_ HU_GNSS_DGPS_age : 0|8@1+ (1,0) [0|0] "Sec"  Vector__XXX
 SG_ HU_GNSS_TimeSource : 12|2@1+ (1,0) [0|0] ""  Vector__XXX
 SG_ HU_GNSS_search : 14|2@1+ (1,0) [0|0] ""  Vector__XXX
 SG_ HU_GNSS_DST : 16|2@1+ (1,0) [0|0] ""  BLTN_CAM
 SG_ HU_GNSS_SV_count : 18|8@1+ (1,0) [0|0] ""  Vector__XXX
 SG_ HU_GNSS_TimezoneOffset : 26|8@1- (15,0) [0|0] "minute"  BLTN_CAM
 SG_ HU_GNSS_Fix_status : 8|4@1+ (1,0) [0|0] ""  Vector__XXX

BO_ 2470761217 CLU_07_00ms_1: 8 CGW_CCU
 SG_ CLU_Crc7Val : 0|16@1+ (1,0) [0|0] ""  Vector__XXX
 SG_ CLU_AlvCnt7Val : 16|8@1+ (1,0) [0|0] ""  Vector__XXX
 SG_ USM_AutoDrLkSetReq : 24|3@1+ (1,0) [0|0] ""  Vector__XXX
 SG_ USM_AutoDrUnlckSetReq : 27|3@1+ (1,0) [0|0] ""  Vector__XXX
 SG_ USM_HLmpEscrtSetReq : 30|2@1+ (1,0) [0|0] ""  Vector__XXX
 SG_ USM_SmrtTrnkSetReq : 32|3@1+ (1,0) [0|0] ""  Vector__XXX
 SG_ USM_MdLmpSetReq : 35|3@1+ (1,0) [0|0] ""  Vector__XXX
 SG_ USM_HrnAnswerBckSetReq : 38|2@1+ (1,0) [0|0] ""  Vector__XXX
 SG_ USM_OneTouchTrplTrnSetReq : 40|3@1+ (1,0) [0|0] ""  Vector__XXX
 SG_ USM_PsmSetReq : 43|3@1+ (1,0) [0|0] ""  GW_DPSU
 SG_ USM_PtgmSetReq : 46|2@1+ (1,0) [0|0] ""  Vector__XXX
 SG_ USM_ScmSetReq : 48|2@1+ (1,0) [0|0] ""  Vector__XXX
 SG_ USM_OSTempUnitSetReq : 50|2@1+ (1,0) [0|0] ""  Vector__XXX
 SG_ USM_TfrChgSetReq : 52|2@1+ (1,0) [0|0] ""  Vector__XXX
 SG_ USM_WALModSetreq : 54|2@1+ (1,0) [0|0] ""  Vector__XXX
 SG_ USM_EscOffSetReq : 56|3@1+ (1,0) [0|0] ""  Vector__XXX
 SG_ USM_PsmHgtSetReq : 59|3@1+ (1,0) [0|0] ""  Vector__XXX
 SG_ USM_Clu_BtnIllumiAlwaysOnReq : 62|2@1+ (1,0) [0|0] ""  Vector__XXX

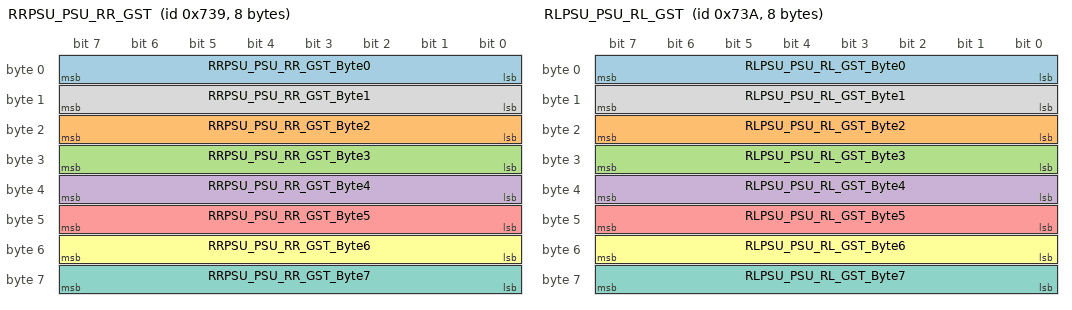
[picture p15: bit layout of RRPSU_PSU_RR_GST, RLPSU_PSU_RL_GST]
BO_ 1849 RRPSU_PSU_RR_GST: 8 GW_RRPSU
 SG_ RRPSU_PSU_RR_GST_Byte0 : 0|8@1+ (1,0) [0|0] ""  CGW_CCU
 SG_ RRPSU_PSU_RR_GST_Byte2 : 16|8@1+ (1,0) [0|0] ""  CGW_CCU
 SG_ RRPSU_PSU_RR_GST_Byte3 : 24|8@1+ (1,0) [0|0] ""  CGW_CCU
 SG_ RRPSU_PSU_RR_GST_Byte4 : 32|8@1+ (1,0) [0|0] ""  CGW_CCU
 SG_ RRPSU_PSU_RR_GST_Byte5 : 40|8@1+ (1,0) [0|0] ""  CGW_CCU
 SG_ RRPSU_PSU_RR_GST_Byte6 : 48|8@1+ (1,0) [0|0] ""  CGW_CCU
 SG_ RRPSU_PSU_RR_GST_Byte7 : 56|8@1+ (1,0) [0|0] ""  CGW_CCU
 SG_ RRPSU_PSU_RR_GST_Byte1 : 8|8@1+ (1,0) [0|0] ""  CGW_CCU

BO_ 884 HU_GNSS_12_1000ms: 8 CGW_CCU
 SG_ HU_MM_Latitude : 0|32@1- (1.0E-6,0) [0|0] "¢ª"  BLTN_CAM
 SG_ HU_MM_Longitude : 32|32@1- (1.0E-6,0) [0|0] "¢ª"  BLTN_CAM

BO_ 1850 RLPSU_PSU_RL_GST: 8 GW_RLPSU
 SG_ RLPSU_PSU_RL_GST_Byte0 : 0|8@1+ (1,0) [0|0] ""  CGW_CCU
 SG_ RLPSU_PSU_RL_GST_Byte2 : 16|8@1+ (1,0) [0|0] ""  CGW_CCU
 SG_ RLPSU_PSU_RL_GST_Byte3 : 24|8@1+ (1,0) [0|0] ""  CGW_CCU
 SG_ RLPSU_PSU_RL_GST_Byte4 : 32|8@1+ (1,0) [0|0] ""  CGW_CCU
 SG_ RLPSU_PSU_RL_GST_Byte5 : 40|8@1+ (1,0) [0|0] ""  CGW_CCU
 SG_ RLPSU_PSU_RL_GST_Byte6 : 48|8@1+ (1,0) [0|0] ""  CGW_CCU
 SG_ RLPSU_PSU_RL_GST_Byte7 : 56|8@1+ (1,0) [0|0] ""  CGW_CCU
 SG_ RLPSU_PSU_RL_GST_Byte1 : 8|8@1+ (1,0) [0|0] ""  CGW_CCU

BO_ 2210462212 HCU_03_10ms_4: 8 CGW_CCU
 SG_ HCU_11sMaxSpdLimOperSta : 44|2@1+ (1,0) [0|0] ""  Vector__XXX

CM_ BO_ 788 "[PE] Periodic and On Event";
CM_ BO_ 2470761217 "[EC] On Event and On Change";
CM_ SG_ 2470761217 CLU_Crc7Val "CLU_CyclicRedundancyCheck7Value";
CM_ SG_ 2470761217 CLU_AlvCnt7Val "CLU_AliveCounter7Value";
CM_ SG_ 2470761217 USM_AutoDrLkSetReq "USM_AutoDoorLockSetRequest";
CM_ SG_ 2470761217 USM_AutoDrUnlckSetReq "USM_AutoDoorUnlockSetRequest";
CM_ SG_ 2470761217 USM_HLmpEscrtSetReq "USM_HeadLampEscortSetRequest";
CM_ SG_ 2470761217 USM_SmrtTrnkSetReq "USM_SmartTrunkSetRequest";
CM_ SG_ 2470761217 USM_MdLmpSetReq "USM_MoodLampSetRequest";
CM_ SG_ 2470761217 USM_HrnAnswerBckSetReq "USM_HornAnswerBackSetRequest";
CM_ SG_ 2470761217 USM_OneTouchTrplTrnSetReq "USM_OneTouchTripleTurnSetRequest";
CM_ SG_ 2470761217 USM_PsmSetReq "USM_PsmSetRequest";
CM_ SG_ 2470761217 USM_PtgmSetReq "USM_PtgmSetRequest";
CM_ SG_ 2470761217 USM_ScmSetReq "USM_ScmSetRequest";
CM_ SG_ 2470761217 USM_OSTempUnitSetReq "USM_OutsideTemperatureUnitSetValue";
CM_ SG_ 2470761217 USM_TfrChgSetReq "USM_TrafficChangeSetRequest";
CM_ SG_ 2470761217 USM_WALModSetreq "USM_WalkAwayLockModeSetRequest(2nd General : CF_Clu_WALNValueset))";
CM_ SG_ 2470761217 USM_EscOffSetReq "USM_EscOffSetRequest (2nd general : CLU14/CF_Clu_EscOffNValueSet";
CM_ SG_ 2470761217 USM_PsmHgtSetReq "USM_PsmHeightSetRequest(2nd general : CLU20/CF_Clu_PSMHeightNValueSet )";
CM_ BO_ 733 "[PE] Periodic and On Event";
CM_ SG_ 733 CMS_LH_Crc1Val "CMS_LH_CyclicRedundancyCheck1Value";
CM_ SG_ 733 CMS_LH_AlvCnt1Val "CMS_LH_AliveCounter1Value";
CM_ SG_ 733 CMS_LHVerPosVal "LH Outside Mirror Vertical Position sensor value";
CM_ SG_ 733 CMS_LHHorPosVal "LH Outside Mirror Horizontal Position Sensor Voltage";
CM_ SG_ 733 Monitor_ViewPanningCmd "Monitor_ViewPanningCommand";
CM_ BO_ 2395189249 "[PE] Periodic and On Event";
CM_ SG_ 2395189249 DATC_Crc8Val "DATC_CyclicRedundancyCheck8Value";
CM_ SG_ 2395189249 DATC_AlvCnt8Val "DATC_AliveCounter8Value";
CM_ SG_ 2395189249 DATC_SmrtVntOnOffSta "DATC_SmartVentilationOnOffStatus";
CM_ SG_ 2395189249 DATC_PsAutoDis "DATC_PassengerAutoDisplay";
CM_ SG_ 2395189249 DATC_RrAutoDis "DATC_RearAutoDisplay";
CM_ SG_ 2395189249 DATC_RrDrvModDis "DATC_RearDriverModeDisplay";
CM_ SG_ 2395189249 DATC_RrPassModDis "DATC_RearPassengerModeDisplay";
CM_ SG_ 2395189249 DATC_DisplayThemes "DATC_DisplayThemesInformation";
CM_ SG_ 2395189249 DATC_EcoZoneDis "DATC_EcoZoneDisplay";
CM_ SG_ 2395189249 DATC_AUTOStepPS "This signal indicates Passenger AUTO step status in case Multi Auto Blower type.";
CM_ SG_ 2395189249 DATC_AUTOStepRR "This signal indicates Rear AUTO step status in case Multi Auto Blower type.";
CM_ BO_ 1882 "[TP] Transport Protocol";
CM_ BO_ 1881 "[TP] Transport Protocol";
CM_ BO_ 2214659329 "[P] Periodic";
CM_ SG_ 2214659329 EMS_Crc7Val "EMS_CyclicRedundancyCheck7Value";
CM_ SG_ 2214659329 EMS_AlvCnt7Val "EMS_AliveCounter7Value";
CM_ SG_ 2214659329 HEV_IndTqVal "HEV_IndicatedTorqueValue";
CM_ SG_ 2214659329 HEV_DrvTqVal "HEV_DriverTorqueValue";
CM_ SG_ 2214659329 HEV_TqStndVal "HEV_TorqueStandardValue";
CM_ SG_ 2214659329 HEV_OilDilution_IncICELoad "HEV Oil Dilution Increase ICE Load";
CM_ SG_ 2214659329 HEV_OilDilution_ServMode "HEV Oil Dilution Service Mode";
CM_ SG_ 2214659329 EMS_TqLmtSta "Status of Torque Limit. Reference for TMS Cooperative control and Cluster notification";
CM_ SG_ 2214659329 EMS_EU7 "Whether the vehicle is EU7 or not";
CM_ BO_ 2214659330 "[P] Periodic";
CM_ SG_ 2214659330 HEV_FrctTqVal "HEV_FrictionTorqueValue";
CM_ SG_ 2214659330 HEV_EngSpdVal "HEV_EngineSpeedValue";
CM_ SG_ 2214659330 HEV_EngOpSta "HEV_EngineOperatingStatus";
CM_ SG_ 2214659330 HEV_IntakeAirTempVal "HEV_IntakeAirTemperatureValue";
CM_ SG_ 2214659330 HEV_AccelPdlVal "HEV_AcceleratorPedalValue";
CM_ SG_ 2214659330 HEV_IndTqTar "HEV_IndicatedTorqueTarget";
CM_ BO_ 2214659331 "[P] Periodic";
CM_ BO_ 2214659332 "[P] Periodic";
CM_ BO_ 2307024129 "[P] Periodic";
CM_ SG_ 2307024129 EMS_Crc8Val "EMS_CyclicRedundancyCheck8Value";
CM_ SG_ 2307024129 EMS_AlvCnt8Val "EMS_AliveCounter8Value";
CM_ SG_ 2307024129 HEV_EngClntTempVal "HEV_EngineCoolantTemperatureValue";
CM_ SG_ 2307024129 HEV_EngOilTempVal "HEV_EngineOilTemperatureValue";
CM_ SG_ 2307024129 HEV_VbOffActSta "HEV_VbOffActStatus";
CM_ SG_ 2307024129 HEV_AirCompOffReq "HEV_AirCompressorOffRequest";
CM_ SG_ 2307024129 HEV_MilConfgVal "HEV_MilConfigurationValue";
CM_ SG_ 2307024129 HEV_CF_EMS_LOCKUP "Engine lock up mainentance request state";
CM_ SG_ 2307024129 HEV_OilLvlSta "HEV_OilLevelStatus";
CM_ SG_ 2307024129 HEV_ImmoLmpReq "HEV_ImmobilizerLampRequest";
CM_ SG_ 2307024129 HEV_MilReq "HEV_MalfunctionIndicationLampRequest";
CM_ SG_ 2307024129 HEV_WiperSwSta "HEV_WiperSwitchStatus";
CM_ SG_ 2307024129 HEV_FanOpSta "HEV_CoolingFanOperatingStatus";
CM_ SG_ 2307024129 HEV_FanSta "HEV_CoolingFanStatus";
CM_ SG_ 2307024129 HEV_BrkLtSwSta "HEV_BrakeLightSwitchStatus";
CM_ BO_ 2307024130 "[P] Periodic";
CM_ SG_ 2307024130 HEV_IgnCycCntVal "HEV_IgnitionCycleCounterValue";
CM_ SG_ 2307024130 HEV_SoakTimeVal "HEV_SoakTimeValue";
CM_ SG_ 2307024130 HEV_SoakTimeErrSta "HEV_SoakTimeErrorStatus";
CM_ SG_ 2307024130 HEV_SoakTimeOvrSta "HEV_SoakTimeOverStatus";
CM_ SG_ 2307024130 HEV_FuelRunOutSta "HEV_FuelRunOutStatus";
CM_ SG_ 2307024130 HEV_FuelRunOutDetSta "HEV_FuelRunOutDetectStatus";
CM_ SG_ 2307024130 HEV_FuelCnsmptSumVal "HEV_FuelConsumptionSumValue";
CM_ BO_ 2307024131 "[P] Periodic";
CM_ SG_ 2307024131 HEV_EstClntTempVal "HEV_EstimatedCoolantTemperatureValue";
CM_ SG_ 2307024131 HEV_EstAmbtAirTempVal "HEV_EstimatedAmbientAirTemperatureValue";
CM_ SG_ 2307024131 HEV_RbmSta "HEV_RateBasedMonitoringStatus";
CM_ SG_ 2307024131 HEV_WarmUpReq_For_DATC "HEV_WarmUpRequest";
CM_ SG_ 2307024131 HEV_RbmInhbtSta "HEV_RbmInhibitionStatus";
CM_ SG_ 2307024131 HEV_EhrsTempSta "HEV_EhrsTemperatureStatus";
CM_ SG_ 2307024131 HEV_Aaf_WrnLamp "Air Flap Warning Lamp/Message Request Signal indicates whether Warning Lamp/Message should be displayed in the display screen in order to warn AAF System failure to customer.";
CM_ SG_ 2307024131 HEV_OPSFail "Oil Pressure Warning Lamp Status";
CM_ SG_ 2307024131 HEV_EngDsplceTyp "HEV_EngineDisplacementType ##2G##EMS - EMS12 - ENG_VOL";
CM_ SG_ 2307024131 HEV_EngTyp2 "HEV_EngineType2 ##2G##EMS - EMS23 - ENG_TYPE";
CM_ SG_ 2307024131 HEV_EngTyp1 "HEV_EngineType1 ##2G##EMS - EMS12 - ENG_CHR";
CM_ SG_ 2307024131 HEV_S_F "AMS/ISG system type indicator";
CM_ SG_ 2307024131 HEV_S_F_GEN "system generation type indicator";
CM_ SG_ 2307024131 HEV_AptVal "HEV_AptValue";
CM_ BO_ 2307024132 "[P] Periodic";
CM_ SG_ 2307024132 HEV_RbmSta_2nd "HEV_RateBasedMonitoringStatus";
CM_ SG_ 2307024132 HEV_OilLifeRatio "Remaining engine oil life with % unit";
CM_ SG_ 2307024132 HEV_OilLifeEna "Enabling information if engine oil life monitoring from EMS is applied or not";
CM_ SG_ 2307024132 HEV_OilLifeWarn "Request to activate engine oil life warning";
CM_ SG_ 2307024132 HEV_ExtSoakTimeVal "The additional Soak Time information extended from HEV_SoakTimeVal of EMS_08_100ms";
CM_ SG_ 2307024132 HEV_RECTrigSta "VCRM trigger bit by REC";
CM_ SG_ 2307024132 HEV_PendingTrigSta "VCRM trigger bit by pending DTC";
CM_ BO_ 2277634049 "[P] Periodic";
CM_ SG_ 2277634049 EPB_Crc1Val "EPB_CyclicRedundancyCheck1Value";
CM_ SG_ 2277634049 EPB_AlvCnt1Val "EPB_AliveCounter1Value";
CM_ SG_ 2277634049 EPB_LmpStaDis "EPB_LampStateDisplay ##2G##EPB - EPB11 - EPB_I_LAMP";
CM_ SG_ 2277634049 EPB_FlrLmpStaDis "EPB_FailureLampStateDisplay ##2G##EPB - EPB11 - EPB_F_LAMP";
CM_ SG_ 2277634049 EPB_OutDataDis "EPB_OutputDataDisplay ##2G##EPB - EPB11 - EPB_CLU";
CM_ SG_ 2277634049 EPB_AlrmReq "EPB_AlarmRequest ##2G##EPB - EPB11 - EPB_ALARM";
CM_ SG_ 2277634049 EPB_SwPosSta "EPB_SwitchPositionStatus ##2G##EPB - EPB11 - EPB_SWITCH";
CM_ SG_ 2277634049 EPB_RrBrkLtActvReq "EPB_RearBrakeLightActivationRequest ##2G##EPB - EPB11 - EPB_RBL";
CM_ SG_ 2277634049 EPB_FrcErrSta "EPB_ForceErrorStatus ##2G##EPB - EPB11 - EPB_FRC_ERR";
CM_ SG_ 2277634049 EPB_DynmBrkFrcReqSigSta "EPB_DynamicBrakingForceRequestSignalStatus ##2G##EPB - EPB11 - EPB_DBF_STAT";
CM_ SG_ 2277634049 EPB_FrcSta "EPB_ForceStatus ##2G##EPB - EPB11 - EPB_STATUS";
CM_ SG_ 2277634049 EPB_FlSta "EPB_FailStatus ##2G##EPB - EPB11 - EPB_FAIL";
CM_ SG_ 2277634049 EPB_EscReqAckSta "EPB_EscRequestAcknowledgeStatus ##2G##EPB - EPB11 - ESP_ACK";
CM_ SG_ 2277634049 EPB_DynmBrkFrcReq "EPB_DynamicBrakingForceRequest ##2G##EPB - EPB11 - EPB_DBF_REQ";
CM_ SG_ 2277634049 EPB_EmerModReq "EPB Emergency Mode Request";
CM_ BO_ 2277634050 "[P] Periodic";
CM_ SG_ 2277634050 EPB_ActlFrcVal "EPB_ActualForceValue ##2G##EPB - EPB11 - EPB_FORCE";
CM_ SG_ 2277634050 EPB_EpbSta4VcuReq "EPB Status when VCU request of parking command or not parking command";
CM_ SG_ 2277634050 EPB_DynmBrkFrcDclReq "EPB_DynamicBrakingForceDecelerationRequest ##2G##EPB - EPB11 - EPB_DBF_DECEL";
CM_ BO_ 1874 "[TP] Transport Protocol";
CM_ BO_ 1873 "[TP] Transport Protocol";
CM_ BO_ 1907 "[TP] Transport Protocol";
CM_ BO_ 1876 "[TP] Transport Protocol";
CM_ BO_ 1875 "[TP] Transport Protocol";
CM_ BO_ 1906 "[TP] Transport Protocol";
CM_ BO_ 2210462212 "[P] Periodic";
CM_ SG_ 2210462212 HCU_11sMaxSpdLimOperSta "HCU_11sMaxSpdLimOperSta";
CM_ BO_ 881 "[P] Periodic";
CM_ SG_ 881 HU_GNSS_UTC_year "UTC year";
CM_ SG_ 881 HU_GNSS_UTC_hour "UTC_HOUR";
CM_ BO_ 883 "[P] Periodic";
CM_ SG_ 883 HU_GNSS_TimeSource "Time Source¶õ ÀÏÁ¾ÀÇ ModuleÀÌ Ãâ·ÂÇÒ ¼ö ÀÖ´Â ½Ã°£Á¤º¸ÀÇ À¯È¿¼º·¹º§À» Å¸³ª³»¸ç, User´Â RTC  or GPS(<1ms)  ÀÏ¶§¸¸ ½Ã°£ Á¤º¸ »ç¿ë °¡´É";
CM_ SG_ 883 HU_GNSS_DST "DST setting";
CM_ SG_ 883 HU_GNSS_TimezoneOffset "Timezone Offset";
CM_ SG_ 883 HU_GNSS_Fix_status "GNSS fix status";
CM_ BO_ 884 "[P] Periodic";
CM_ SG_ 884 HU_MM_Latitude "Map matching Latitude";
CM_ SG_ 884 HU_MM_Longitude "Mapmatching Longitude";
CM_ BO_ 721 "[P] Periodic";
CM_ SG_ 721 HU_DR_Position_Status "DR Position status";
CM_ SG_ 721 HU_DR_Altitude_Status "DR Altitude Status";
CM_ SG_ 721 HU_DR_Altitude "range [-400,10000]";
CM_ SG_ 721 HU_DR_Heading_Status "DR Heading Status";
CM_ SG_ 721 HU_DR_Speed_Status "DR Speed status";
CM_ SG_ 721 HU_DR_DirectionSwitch_Sta "DR DirectionSwitch Status";
CM_ SG_ 721 HU_DR_Direction "DR Direction, Backward";
CM_ SG_ 721 HU_DR_GyroCalib_Sta "DR Gyro Calibration Status";
CM_ SG_ 721 HU_DR_TachoCalib_Sta "DR Tacho Calibration Status";
CM_ SG_ 721 HU_DR_GNSS_Fix_Age "Time since last GNSS fix";
CM_ BO_ 722 "[P] Periodic";
CM_ SG_ 722 HU_DR_Latitude "1sc(semi-cicle)= pi rad=180  /   unit : 2^-31sc  /  range [-1/2~1/2] sc";
CM_ SG_ 722 HU_DR_Longitude "1sc(semi-circle)=pi rad=180 / unit:2^-31sc / range:[-1, 1]sc";
CM_ BO_ 723 "[P] Periodic";
CM_ SG_ 723 HU_DR_Heading "1sc(semi-circle)=pi rad=180 / unit=2^-15sc / range:[0,2]SC";
CM_ SG_ 723 HU_DR_Speed "unit : 1cm/s";
CM_ BO_ 787 "[PE] Periodic and On Event";
CM_ BO_ 1915 "[TP] Transport Protocol";
CM_ BO_ 791 "[PE] Periodic and On Event";
CM_ SG_ 791 RCM_Crc4Val "RCM_CyclicRedundancyCheck4Value";
CM_ SG_ 791 RCM_AlvCnt4Val "RCM_AliveCounter4Value";
CM_ SG_ 791 RCM_RR_SunroofOpnSta "Rear Sunroof Glass Open Status";
CM_ SG_ 791 RCM_RR_GlsOpSta "Rear Sunroof Glass Operation Status";
CM_ SG_ 791 RCM_RR_GlsPosSta "Rear Sunroof Glass Position Status";
CM_ SG_ 791 RCM_RR_GlsFltSta "Rear Sunroof Glass Fault Status";
CM_ BO_ 792 "[PE] Periodic and On Event";
CM_ SG_ 792 RCM_Crc5Val "RCM_CyclicRedundancyCheck5Value";
CM_ SG_ 792 RCM_AlvCnt5Val "RCM_AliveCounter5Value";
CM_ SG_ 792 RCM_RR_BldPosSta "Rear Sunroof Blind Position Status";
CM_ SG_ 792 RCM_RR_BldFltSta "Rear Sunroof Blind Fault Status";
CM_ BO_ 1884 "[TP] Transport Protocol";
CM_ BO_ 1883 "[TP] Transport Protocol";
CM_ BO_ 1850 "[TP] Transport Protocol";
CM_ BO_ 1914 "[TP] Transport Protocol";
CM_ BO_ 1849 "[TP] Transport Protocol";
CM_ BO_ 799 "[PE] Periodic and On Event";
CM_ SG_ 799 SBCM_DRV_Crc1Val "SBCM_DRV_CyclicRedundancyCheck1Value";
CM_ SG_ 799 C_ApprOpenStatus "Stop fob searching signal";
CM_ SG_ 799 SBCM_DRV_AlvCnt1Val "SBCM_DRV_AliveCounter1Value";
CM_ SG_ 799 DoorLock_DrvKeyLkSwSta_SBCM "DoorLock_DriverKeyLockSwitchStatus ##2G## -  - C_DrvKeyLockSw";
CM_ SG_ 799 DoorLock_DrvKeyUnLkSwSta_SBCM "DoorLock_DriverKeyUnLockSwitchStatus ##2G## -  - C_DrvKeyUnlockSw";
CM_ SG_ 799 Warn_DrvDrSwSta_SBCM "DoorLock_DriverDoorSwitchStatus ##2G## -  - C_DrvDrSw,CF_Gway_DrvDrSw,Warn_DrvDrSwSta";
CM_ SG_ 799 DoorLock_DrvDrUnLkSta_SBCM "DoorLock_DriverDoorUnLockStatus ##2G## -  - C_DrvUnlockState,CF_Gway_DrvUnlockState";
CM_ SG_ 799 C_DrvDoorApproachOpen "Approach open";
CM_ BO_ 830 "[PE] Periodic and On Event";
CM_ SG_ 830 USM_CmdWPC2Sta "USM_CommandWPC2Status";
CM_ SG_ 830 WPC2_SWVerMajor1 "First Word(ASCII) in WPC2 S/W Ver";
CM_ SG_ 830 WPC2_PhnLftWrngSta "WPC2_PhoneLeftWarningStatus";
CM_ SG_ 830 WPC2_SWVerMinor1 "Second Word(ASCII) in WPC2 S/W Ver";
CM_ SG_ 830 WPC2_SWVerMinor2 "Third Word(ASCII) in WPC2 S/W Ver";
BA_DEF_ BO_ "DiagState" ENUM "No","Yes" ;
BA_DEF_ BO_ "DiagResponse" ENUM "No","Yes" ;
BA_DEF_ BO_ "DiagRequest" ENUM "No","Yes" ;
BA_DEF_ BO_ "TpMessage" ENUM "No","Yes" ;
BA_DEF_ BO_ "UsrMsgIDSforwardDeviation" INT 0 100 ;
BA_DEF_ BO_ "UsrMsgIDSbackwardDeviation" INT 50 1000 ;
BA_DEF_ BO_ "GenMsgCycleTime" INT 0 2000 ;
BA_DEF_ BO_ "GenMsgStartDelayTime" INT 0 2000 ;
BA_DEF_ BO_ "GenMsgSendType" ENUM "Cyclic","NoMsgSendType" ;
BA_DEF_ BO_ "GenMsgCycleTimeFast" INT 0 500 ;
BA_DEF_ BO_ "GenMsgDelayTime" INT 0 20 ;
BA_DEF_ BO_ "GenMsgILSupport" ENUM "No","Yes" ;
BA_DEF_ BO_ "GenMsgNrOfRepetition" INT 0 3 ;
BA_DEF_ BO_ "NmMessage" ENUM "No","Yes" ;
BA_DEF_ BO_ "NWM-Botschaft" ENUM "No","Yes" ;
BA_DEF_ BO_ "TpTxIndex" INT 0 65535 ;
BA_DEF_ BO_ "VFrameFormat" ENUM "StandardCAN","ExtendedCAN","reserved","reserved","reserved","reserved","reserved","reserved","reserved","reserved","reserved","reserved","reserved","reserved","StandardCAN_FD","ExtendedCAN_FD" ;
BA_DEF_ SG_ "UserSigValidity" ENUM "B+","ACC","IG","IG1","IG2","IG3","IG1 or IG2","IG1 or IG3","Undef" ;
BA_DEF_ SG_ "TimeoutValue" STRING ;
BA_DEF_ SG_ "UsrSigPurpose" ENUM "Undef","FN","DIAG","DIAG(Req)","DIAG(Res)","DIAG(Phy)","DEV","CCP(Req)","CCP(Res)","NM","TP" ;
BA_DEF_ SG_ "GenSigStartValue" INT 0 1215752192 ;
BA_DEF_ SG_ "NetworkRequest" ENUM "Yes","No" ;
BA_DEF_ SG_ "NetworkRequestHoldingTime" INT 0 65535 ;
BA_DEF_ SG_ "Description" STRING ;
BA_DEF_ SG_ "Version" STRING ;
BA_DEF_ SG_ "GenSigEnvVarType" ENUM "Int","Float","Undef" ;
BA_DEF_ SG_ "GenSigSendType" ENUM "Cyclic","OnWrite","OnWriteWithRepetition","OnChange","OnChangeWithRepetition","IfActive","IfActiveWithRepetition","NoSigSendType","OnChangeAndIfActive","OnChangeAndIfActiveWithRepetition" ;
BA_DEF_ SG_ "GwSigLatencyTime" INT 0 65536 ;
BA_DEF_ SG_ "GwSigMissingSourceType" ENUM "Undef","OldValue","DefaultValue","InitialValue" ;
BA_DEF_ SG_ "NWM-WakeupAllowed" ENUM "<n.a.>" ;
BA_DEF_ SG_ "RoutingFactor" INT 1 1215752192 ;
BA_DEF_REL_ BU_SG_REL_ "GenSigTimeoutTime" INT 0 7000 ;
BA_DEF_DEF_ "DiagState" "No" ;
BA_DEF_DEF_ "DiagResponse" "No" ;
BA_DEF_DEF_ "DiagRequest" "No" ;
BA_DEF_DEF_ "TpMessage" "No" ;
BA_DEF_DEF_ "UsrMsgIDSforwardDeviation" 10 ;
BA_DEF_DEF_ "UsrMsgIDSbackwardDeviation" 100 ;
BA_DEF_DEF_ "GenMsgCycleTime" 200 ;
BA_DEF_DEF_ "GenMsgStartDelayTime" 0 ;
BA_DEF_DEF_ "GenMsgSendType" "NoMsgSendType" ;
BA_DEF_DEF_ "GenMsgCycleTimeFast" 40 ;
BA_DEF_DEF_ "GenMsgDelayTime" 20 ;
BA_DEF_DEF_ "GenMsgILSupport" "Yes" ;
BA_DEF_DEF_ "GenMsgNrOfRepetition" 3 ;
BA_DEF_DEF_ "NmMessage" "No" ;
BA_DEF_DEF_ "NWM-Botschaft" "No" ;
BA_DEF_DEF_ "TpTxIndex" 0 ;
BA_DEF_DEF_ "VFrameFormat" "StandardCAN" ;
BA_DEF_DEF_ "UserSigValidity" "IG" ;
BA_DEF_DEF_ "TimeoutValue" "" ;
BA_DEF_DEF_ "UsrSigPurpose" "FN" ;
BA_DEF_DEF_ "GenSigStartValue" 0 ;
BA_DEF_DEF_ "NetworkRequest" "No" ;
BA_DEF_DEF_ "NetworkRequestHoldingTime" 0 ;
BA_DEF_DEF_ "Description" "" ;
BA_DEF_DEF_ "Version" "" ;
BA_DEF_DEF_ "GenSigEnvVarType" "Undef" ;
BA_DEF_DEF_ "GenSigSendType" "NoSigSendType" ;
BA_DEF_DEF_ "GwSigLatencyTime" 40 ;
BA_DEF_DEF_ "GwSigMissingSourceType" "Undef" ;
BA_DEF_DEF_ "NWM-WakeupAllowed" "<n.a.>" ;
BA_DEF_DEF_ "RoutingFactor" 1 ;
BA_DEF_DEF_REL_ "GenSigTimeoutTime" 500 ;
BA_ "GenMsgSendType" BO_ 788 0;
BA_ "Description" SG_ 788 APSU_AstSlidePosition "ASSIST SEAT SLIDE POSITION (UNIT: mm, 1 Value ´ç 2mm)";
BA_ "GenSigSendType" SG_ 788 APSU_AstSlidePosition 4;
BA_ "UserSigValidity" SG_ 788 APSU_AstSlidePosition 0;
BA_REL_ "GenSigTimeoutTime" BU_SG_REL_ CGW_CCU SG_ 788 APSU_AstSlidePosition 1500;
BA_REL_ "GenSigTimeoutTime" BU_SG_REL_ GW_RLPSU SG_ 788 APSU_AstSlidePosition 1500;
BA_REL_ "GenSigTimeoutTime" BU_SG_REL_ GW_RRPSU SG_ 788 APSU_AstSlidePosition 1500;
BA_ "NetworkRequest" SG_ 788 APSU_AstSlidePosition 0;
BA_ "NetworkRequestHoldingTime" SG_ 788 APSU_AstSlidePosition 5000;
BA_ "Version" SG_ 788 APSU_AstSlidePosition "22.06.05";
BA_ "Description" SG_ 788 APSU_AstHeightPosition "ASSIST SEAT HEIGHT POSITION (UNIT: mm)";
BA_ "GenSigSendType" SG_ 788 APSU_AstHeightPosition 4;
BA_ "UserSigValidity" SG_ 788 APSU_AstHeightPosition 0;
BA_REL_ "GenSigTimeoutTime" BU_SG_REL_ CGW_CCU SG_ 788 APSU_AstHeightPosition 1500;
BA_REL_ "GenSigTimeoutTime" BU_SG_REL_ GW_RLPSU SG_ 788 APSU_AstHeightPosition 1500;
BA_REL_ "GenSigTimeoutTime" BU_SG_REL_ GW_RRPSU SG_ 788 APSU_AstHeightPosition 1500;
BA_ "NetworkRequest" SG_ 788 APSU_AstHeightPosition 0;
BA_ "NetworkRequestHoldingTime" SG_ 788 APSU_AstHeightPosition 5000;
BA_ "Version" SG_ 788 APSU_AstHeightPosition "22.02.05";
BA_ "Description" SG_ 788 APSU_AstReclinePosition "ASSIST SEAT RECLINE POSITION (UNIT: ¢ª)";
BA_ "GenSigSendType" SG_ 788 APSU_AstReclinePosition 4;
BA_ "UserSigValidity" SG_ 788 APSU_AstReclinePosition 0;
BA_REL_ "GenSigTimeoutTime" BU_SG_REL_ CGW_CCU SG_ 788 APSU_AstReclinePosition 1500;
BA_REL_ "GenSigTimeoutTime" BU_SG_REL_ GW_RLPSU SG_ 788 APSU_AstReclinePosition 1500;
BA_REL_ "GenSigTimeoutTime" BU_SG_REL_ GW_RRPSU SG_ 788 APSU_AstReclinePosition 1500;
BA_ "NetworkRequest" SG_ 788 APSU_AstReclinePosition 0;
BA_ "NetworkRequestHoldingTime" SG_ 788 APSU_AstReclinePosition 5000;
BA_ "Version" SG_ 788 APSU_AstReclinePosition "22.02.05";
BA_ "Description" SG_ 788 APSU_AstRelaxTiltPosition "DRIVER SEAT RELAX TILT POSITION (UNIT: ¢ª)";
BA_ "GenSigSendType" SG_ 788 APSU_AstRelaxTiltPosition 4;
BA_ "UserSigValidity" SG_ 788 APSU_AstRelaxTiltPosition 0;
BA_REL_ "GenSigTimeoutTime" BU_SG_REL_ CGW_CCU SG_ 788 APSU_AstRelaxTiltPosition 1500;
BA_REL_ "GenSigTimeoutTime" BU_SG_REL_ GW_RLPSU SG_ 788 APSU_AstRelaxTiltPosition 1500;
BA_REL_ "GenSigTimeoutTime" BU_SG_REL_ GW_RRPSU SG_ 788 APSU_AstRelaxTiltPosition 1500;
BA_ "NetworkRequest" SG_ 788 APSU_AstRelaxTiltPosition 0;
BA_ "NetworkRequestHoldingTime" SG_ 788 APSU_AstRelaxTiltPosition 5000;
BA_ "Version" SG_ 788 APSU_AstRelaxTiltPosition "22.02.05";
BA_ "GenMsgCycleTime" BO_ 2470761217 0;
BA_ "VFrameFormat" BO_ 2470761217 1;
BA_ "Description" SG_ 2470761217 CLU_Crc7Val "The data area for CRC calculation is based on the data length (DLC) of the message DB.

The CRC shall be calculated over the entire data block (excluding the CRC bytes) including the user data, alive counter and Data ID



- CRC Polynomial (0x1021) , Initial Value : 0xFFFF, XOR value : 0x0000, Data ID : Message ID + 0xF800 

- The initial value is for CRC calculation and the message should be sent with the calculated result value. 

- The mathematical expression to 16 bit CRC polynomial is given here. G(x) = x16 + x12 + x5 + 1



<For CRC calculation of CAN-FD Msg for HS CAN domain ECUs>



- HS-CAN Messages that routed from CAN-FD domain are using 29 bit Extended CAN ID and splitted into 8 Byte Messages.

(from 1 to 4 Msgs, depending on source CAN-FD Msg¡¯s DLC)

- For splitted CAN-FD Msgs¡¯ CRC calculation, HS CAN ECUs should use source CAN-FD Msg¡¯s original STD ID. 

- The original STD ID can be read from Ext ID¡¯s 4~6th Byte.

Eg. STD 0x6AA : EXT SPLT 0x1A8[6AA]01 / 0x1A8[6AA]02 / 0x1A8[6AA]03 / 0x1A8[6AA]04 

(2~4th splitited Msgs can be omitted depending on source CAN-FD Msg¡¯s DLC)

- Aslo, HS-CAN ECUs should use merged data block (from whole splitted Msg) for CRC calculation.";
BA_ "GenSigSendType" SG_ 2470761217 CLU_Crc7Val 4;
BA_ "GenSigStartValue" SG_ 2470761217 CLU_Crc7Val 65535;
BA_ "UserSigValidity" SG_ 2470761217 CLU_Crc7Val 3;
BA_ "Version" SG_ 2470761217 CLU_Crc7Val "21.09.03";
BA_ "Description" SG_ 2470761217 CLU_AlvCnt7Val "For the first transmission request for a data element the counter shall be initialized with 0 and shall be incremented by 1 for every subsequent send request. 

When the counter reaches the maximum value(0xFF), then it shall restart with 0 for the next send request";
BA_ "GenSigSendType" SG_ 2470761217 CLU_AlvCnt7Val 4;
BA_ "UserSigValidity" SG_ 2470761217 CLU_AlvCnt7Val 3;
BA_ "Version" SG_ 2470761217 CLU_AlvCnt7Val "21.09.03";
BA_ "Description" SG_ 2470761217 USM_AutoDrLkSetReq "Request set the new Auto Door Lock Mode";
BA_ "GenSigSendType" SG_ 2470761217 USM_AutoDrLkSetReq 4;
BA_ "UserSigValidity" SG_ 2470761217 USM_AutoDrLkSetReq 3;
BA_ "Version" SG_ 2470761217 USM_AutoDrLkSetReq "17.11.00";
BA_ "Description" SG_ 2470761217 USM_AutoDrUnlckSetReq "Request to set Auto Door Unlock Mode";
BA_ "GenSigSendType" SG_ 2470761217 USM_AutoDrUnlckSetReq 4;
BA_ "UserSigValidity" SG_ 2470761217 USM_AutoDrUnlckSetReq 3;
BA_ "Version" SG_ 2470761217 USM_AutoDrUnlckSetReq "17.11.00";
BA_ "Description" SG_ 2470761217 USM_HLmpEscrtSetReq "Request to set Head Lamp Escort Option";
BA_ "GenSigSendType" SG_ 2470761217 USM_HLmpEscrtSetReq 4;
BA_ "UserSigValidity" SG_ 2470761217 USM_HLmpEscrtSetReq 3;
BA_ "Version" SG_ 2470761217 USM_HLmpEscrtSetReq "17.11.00";
BA_ "Description" SG_ 2470761217 USM_SmrtTrnkSetReq "Request to set Smart Trunk/Tailgate Mode";
BA_ "GenSigSendType" SG_ 2470761217 USM_SmrtTrnkSetReq 4;
BA_ "UserSigValidity" SG_ 2470761217 USM_SmrtTrnkSetReq 3;
BA_ "Version" SG_ 2470761217 USM_SmrtTrnkSetReq "17.11.00";
BA_ "Description" SG_ 2470761217 USM_MdLmpSetReq "Request to set interior mood lamp setting";
BA_ "GenSigSendType" SG_ 2470761217 USM_MdLmpSetReq 4;
BA_ "UserSigValidity" SG_ 2470761217 USM_MdLmpSetReq 3;
BA_ "Version" SG_ 2470761217 USM_MdLmpSetReq "17.11.00";
BA_ "Description" SG_ 2470761217 USM_HrnAnswerBckSetReq "Request to set Horn Answer Back Mode";
BA_ "GenSigSendType" SG_ 2470761217 USM_HrnAnswerBckSetReq 4;
BA_ "UserSigValidity" SG_ 2470761217 USM_HrnAnswerBckSetReq 3;
BA_ "Version" SG_ 2470761217 USM_HrnAnswerBckSetReq "17.11.00";
BA_ "Description" SG_ 2470761217 USM_OneTouchTrplTrnSetReq "This signal is used for a request current setting value of USM Menus. When this signal change, the message (CLU14) is sent 3 times.";
BA_ "GenSigSendType" SG_ 2470761217 USM_OneTouchTrplTrnSetReq 4;
BA_ "UserSigValidity" SG_ 2470761217 USM_OneTouchTrplTrnSetReq 3;
BA_ "Version" SG_ 2470761217 USM_OneTouchTrplTrnSetReq "17.11.00";
BA_ "Description" SG_ 2470761217 USM_PsmSetReq "This signal is used for a request to set the value of UMS Menus.

This signal requests to set Seat Easy Access Mode.

When this signal change, the message (CLU14) is sent 3 times.";
BA_ "GenSigSendType" SG_ 2470761217 USM_PsmSetReq 4;
BA_ "UserSigValidity" SG_ 2470761217 USM_PsmSetReq 3;
BA_REL_ "GenSigTimeoutTime" BU_SG_REL_ GW_DPSU SG_ 2470761217 USM_PsmSetReq 0;
BA_ "Version" SG_ 2470761217 USM_PsmSetReq "17.11.00";
BA_ "Description" SG_ 2470761217 USM_PtgmSetReq "Request to set PTGM Mode";
BA_ "GenSigSendType" SG_ 2470761217 USM_PtgmSetReq 4;
BA_ "UserSigValidity" SG_ 2470761217 USM_PtgmSetReq 3;
BA_ "Version" SG_ 2470761217 USM_PtgmSetReq "17.11.00";
BA_ "Description" SG_ 2470761217 USM_ScmSetReq "Request to set Steering Easy Access mode";
BA_ "GenSigSendType" SG_ 2470761217 USM_ScmSetReq 4;
BA_ "UserSigValidity" SG_ 2470761217 USM_ScmSetReq 3;
BA_ "Version" SG_ 2470761217 USM_ScmSetReq "17.11.00";
BA_ "Description" SG_ 2470761217 USM_OSTempUnitSetReq "This signal is used for a request to set the value of USM Menus. This signal requests to set Outside Temperature Unit.

When this signal change, the message (CLU14) is sent 3 times.";
BA_ "GenSigSendType" SG_ 2470761217 USM_OSTempUnitSetReq 4;
BA_ "UserSigValidity" SG_ 2470761217 USM_OSTempUnitSetReq 3;
BA_ "Version" SG_ 2470761217 USM_OSTempUnitSetReq "17.11.00";
BA_ "Description" SG_ 2470761217 USM_TfrChgSetReq "This signal is used for a request to set the value of UMS Menus.

This signal requests to set Traffic Change Mode.

When this signal change, the message (CLU4) is sent 3 times.";
BA_ "GenSigSendType" SG_ 2470761217 USM_TfrChgSetReq 4;
BA_ "UserSigValidity" SG_ 2470761217 USM_TfrChgSetReq 3;
BA_ "Version" SG_ 2470761217 USM_TfrChgSetReq "17.11.00";
BA_ "Description" SG_ 2470761217 USM_WALModSetreq "This signal is used for a request to set the value USM Menus.

This signal requests to set WAL(WalkAwayLock) function";
BA_ "GenSigSendType" SG_ 2470761217 USM_WALModSetreq 4;
BA_ "UserSigValidity" SG_ 2470761217 USM_WALModSetreq 3;
BA_ "Version" SG_ 2470761217 USM_WALModSetreq "18.10.02";
BA_ "Description" SG_ 2470761217 USM_EscOffSetReq "Request to set ESC OFF mode

If ESC off switch is not applied in vehicle, this signal is needed for USM menu";
BA_ "GenSigSendType" SG_ 2470761217 USM_EscOffSetReq 4;
BA_ "UserSigValidity" SG_ 2470761217 USM_EscOffSetReq 3;
BA_ "Version" SG_ 2470761217 USM_EscOffSetReq "18.07.03";
BA_ "Description" SG_ 2470761217 USM_PsmHgtSetReq "This signal is used for a request to set the value of UMS Menus.

This signal requests to set Seat Easy Access Mode.

When this signal change, the message (CLU_07_00ms) is sent 3 times.";
BA_ "GenSigSendType" SG_ 2470761217 USM_PsmHgtSetReq 4;
BA_ "UserSigValidity" SG_ 2470761217 USM_PsmHgtSetReq 3;
BA_ "Version" SG_ 2470761217 USM_PsmHgtSetReq "18.07.03";
BA_ "Description" SG_ 2470761217 USM_Clu_BtnIllumiAlwaysOnReq "USM Request for always turning on button illumination.";
BA_ "GenSigSendType" SG_ 2470761217 USM_Clu_BtnIllumiAlwaysOnReq 4;
BA_ "UserSigValidity" SG_ 2470761217 USM_Clu_BtnIllumiAlwaysOnReq 3;
BA_ "Version" SG_ 2470761217 USM_Clu_BtnIllumiAlwaysOnReq "22.06.05";
BA_ "GenMsgSendType" BO_ 733 0;
BA_ "Description" SG_ 733 CMS_LH_Crc1Val "The data area for CRC calculation is based on the data length (DLC) of the message DB.

The CRC shall be calculated over the entire data block (excluding the CRC bytes) including the user data, alive counter and Data ID 

 

- CRC Polynomial (0x1D) , Initial Value : 0x00, XOR value : 0xFF, Data ID Mode : Both, Data ID : Message ID + 0xF800 

- The initial value is for CRC calculation and the message should be sent with the calculated result value. 

The mathematical expression to 8 bit CRC polynomial is given here. G(x) = x8 + x4 + x3 + x2 + 1";
BA_ "GenSigSendType" SG_ 733 CMS_LH_Crc1Val 4;
BA_ "UserSigValidity" SG_ 733 CMS_LH_Crc1Val 0;
BA_ "RoutingFactor" SG_ 733 CMS_LH_Crc1Val 0;
BA_ "Version" SG_ 733 CMS_LH_Crc1Val "21.09.03";
BA_ "Description" SG_ 733 CMS_LH_AlvCnt1Val "For the first transmission request for a data element the counter shall be initialized with 0 and shall be incremented by 1

for every subsequent send request. When the counter reaches the maximum value(0xE), then it shall restart with 0 for the next send request";
BA_ "GenSigSendType" SG_ 733 CMS_LH_AlvCnt1Val 4;
BA_ "UserSigValidity" SG_ 733 CMS_LH_AlvCnt1Val 0;
BA_ "RoutingFactor" SG_ 733 CMS_LH_AlvCnt1Val 0;
BA_ "Version" SG_ 733 CMS_LH_AlvCnt1Val "21.09.03";
BA_ "GenSigSendType" SG_ 733 USM_TurnDstLnDispSta 4;
BA_ "UserSigValidity" SG_ 733 USM_TurnDstLnDispSta 0;
BA_ "NetworkRequest" SG_ 733 USM_TurnDstLnDispSta 0;
BA_ "NetworkRequestHoldingTime" SG_ 733 USM_TurnDstLnDispSta 5;
BA_ "RoutingFactor" SG_ 733 USM_TurnDstLnDispSta 0;
BA_ "Version" SG_ 733 USM_TurnDstLnDispSta "21.08.01";
BA_ "GenSigSendType" SG_ 733 USM_TurnDstLnDispStaRH 4;
BA_ "UserSigValidity" SG_ 733 USM_TurnDstLnDispStaRH 0;
BA_ "NetworkRequest" SG_ 733 USM_TurnDstLnDispStaRH 0;
BA_ "NetworkRequestHoldingTime" SG_ 733 USM_TurnDstLnDispStaRH 5;
BA_ "RoutingFactor" SG_ 733 USM_TurnDstLnDispStaRH 0;
BA_ "Version" SG_ 733 USM_TurnDstLnDispStaRH "21.08.01";
BA_ "GenSigSendType" SG_ 733 USM_RhstaLvlEnaSta 4;
BA_ "UserSigValidity" SG_ 733 USM_RhstaLvlEnaSta 0;
BA_ "NetworkRequest" SG_ 733 USM_RhstaLvlEnaSta 0;
BA_ "NetworkRequestHoldingTime" SG_ 733 USM_RhstaLvlEnaSta 5;
BA_ "RoutingFactor" SG_ 733 USM_RhstaLvlEnaSta 0;
BA_ "Version" SG_ 733 USM_RhstaLvlEnaSta "21.08.01";
BA_ "GenSigSendType" SG_ 733 USM_RhstaLvlEnaStaRH 4;
BA_ "UserSigValidity" SG_ 733 USM_RhstaLvlEnaStaRH 0;
BA_ "NetworkRequest" SG_ 733 USM_RhstaLvlEnaStaRH 0;
BA_ "NetworkRequestHoldingTime" SG_ 733 USM_RhstaLvlEnaStaRH 5;
BA_ "RoutingFactor" SG_ 733 USM_RhstaLvlEnaStaRH 0;
BA_ "Version" SG_ 733 USM_RhstaLvlEnaStaRH "21.08.01";
BA_ "GenSigSendType" SG_ 733 USM_CMSDayBrgtnsLvlLHSta 4;
BA_ "GenSigStartValue" SG_ 733 USM_CMSDayBrgtnsLvlLHSta 5;
BA_ "UserSigValidity" SG_ 733 USM_CMSDayBrgtnsLvlLHSta 0;
BA_ "NetworkRequest" SG_ 733 USM_CMSDayBrgtnsLvlLHSta 0;
BA_ "NetworkRequestHoldingTime" SG_ 733 USM_CMSDayBrgtnsLvlLHSta 5;
BA_ "RoutingFactor" SG_ 733 USM_CMSDayBrgtnsLvlLHSta 0;
BA_ "Version" SG_ 733 USM_CMSDayBrgtnsLvlLHSta "21.08.01";
BA_ "GenSigSendType" SG_ 733 USM_CMSNgtBrgtnsLvlLHSta 4;
BA_ "GenSigStartValue" SG_ 733 USM_CMSNgtBrgtnsLvlLHSta 5;
BA_ "UserSigValidity" SG_ 733 USM_CMSNgtBrgtnsLvlLHSta 0;
BA_ "NetworkRequest" SG_ 733 USM_CMSNgtBrgtnsLvlLHSta 0;
BA_ "NetworkRequestHoldingTime" SG_ 733 USM_CMSNgtBrgtnsLvlLHSta 5;
BA_ "RoutingFactor" SG_ 733 USM_CMSNgtBrgtnsLvlLHSta 0;
BA_ "Version" SG_ 733 USM_CMSNgtBrgtnsLvlLHSta "21.08.01";
BA_ "GenSigSendType" SG_ 733 IMS_CMSPlayBackSta_LH 4;
BA_ "UserSigValidity" SG_ 733 IMS_CMSPlayBackSta_LH 0;
BA_REL_ "GenSigTimeoutTime" BU_SG_REL_ GW_DPSU SG_ 733 IMS_CMSPlayBackSta_LH 1500;
BA_ "NetworkRequest" SG_ 733 IMS_CMSPlayBackSta_LH 0;
BA_ "NetworkRequestHoldingTime" SG_ 733 IMS_CMSPlayBackSta_LH 5;
BA_ "RoutingFactor" SG_ 733 IMS_CMSPlayBackSta_LH 0;
BA_ "Version" SG_ 733 IMS_CMSPlayBackSta_LH "21.08.01";
BA_ "GenSigSendType" SG_ 733 CMSFldReq 4;
BA_ "UserSigValidity" SG_ 733 CMSFldReq 0;
BA_ "NetworkRequest" SG_ 733 CMSFldReq 0;
BA_ "NetworkRequestHoldingTime" SG_ 733 CMSFldReq 5;
BA_ "RoutingFactor" SG_ 733 CMSFldReq 0;
BA_ "Version" SG_ 733 CMSFldReq "21.08.01";
BA_ "GenSigSendType" SG_ 733 CMS_LH_FoldingSta 4;
BA_ "UserSigValidity" SG_ 733 CMS_LH_FoldingSta 0;
BA_ "NetworkRequest" SG_ 733 CMS_LH_FoldingSta 0;
BA_ "NetworkRequestHoldingTime" SG_ 733 CMS_LH_FoldingSta 5000;
BA_ "RoutingFactor" SG_ 733 CMS_LH_FoldingSta 0;
BA_ "Version" SG_ 733 CMS_LH_FoldingSta "21.08.01";
BA_ "GenSigSendType" SG_ 733 CMS_LH_UnfoldingSta 4;
BA_ "UserSigValidity" SG_ 733 CMS_LH_UnfoldingSta 0;
BA_ "NetworkRequest" SG_ 733 CMS_LH_UnfoldingSta 0;
BA_ "NetworkRequestHoldingTime" SG_ 733 CMS_LH_UnfoldingSta 5000;
BA_ "RoutingFactor" SG_ 733 CMS_LH_UnfoldingSta 0;
BA_ "Version" SG_ 733 CMS_LH_UnfoldingSta "21.08.01";
BA_ "Description" SG_ 733 CMS_LHVerPosVal "This signal indicates LH Outside Mirror Vertical Position Sensor Voltage";
BA_ "GenSigSendType" SG_ 733 CMS_LHVerPosVal 4;
BA_ "UserSigValidity" SG_ 733 CMS_LHVerPosVal 0;
BA_ "NetworkRequest" SG_ 733 CMS_LHVerPosVal 0;
BA_ "NetworkRequestHoldingTime" SG_ 733 CMS_LHVerPosVal 5000;
BA_ "RoutingFactor" SG_ 733 CMS_LHVerPosVal 0;
BA_ "Version" SG_ 733 CMS_LHVerPosVal "21.08.01";
BA_ "Description" SG_ 733 CMS_LHHorPosVal "This signal indicates LH Outside Mirror Horizontal Position Sensor Voltage";
BA_ "GenSigSendType" SG_ 733 CMS_LHHorPosVal 4;
BA_ "UserSigValidity" SG_ 733 CMS_LHHorPosVal 0;
BA_ "NetworkRequest" SG_ 733 CMS_LHHorPosVal 0;
BA_ "NetworkRequestHoldingTime" SG_ 733 CMS_LHHorPosVal 5000;
BA_ "RoutingFactor" SG_ 733 CMS_LHHorPosVal 0;
BA_ "Version" SG_ 733 CMS_LHHorPosVal "21.08.01";
BA_ "GenSigSendType" SG_ 733 Monitor_ViewPanningCmd 4;
BA_ "UserSigValidity" SG_ 733 Monitor_ViewPanningCmd 0;
BA_ "NetworkRequest" SG_ 733 Monitor_ViewPanningCmd 0;
BA_ "NetworkRequestHoldingTime" SG_ 733 Monitor_ViewPanningCmd 5000;
BA_ "RoutingFactor" SG_ 733 Monitor_ViewPanningCmd 0;
BA_ "Version" SG_ 733 Monitor_ViewPanningCmd "21.08.01";
BA_ "GenMsgSendType" BO_ 2395189249 0;
BA_ "VFrameFormat" BO_ 2395189249 1;
BA_ "Description" SG_ 2395189249 DATC_Crc8Val "The data area for CRC calculation is based on the data length (DLC) of the message DB.

The CRC shall be calculated over the entire data block (excluding the CRC bytes) including the user data, alive counter and Data ID



- CRC Polynomial (0x1021) , Initial Value : 0xFFFF, XOR value : 0x0000, Data ID : Message ID + 0xF800 

- The initial value is for CRC calculation and the message should be sent with the calculated result value. 

- The mathematical expression to 16 bit CRC polynomial is given here. G(x) = x16 + x12 + x5 + 1



<For CRC calculation of CAN-FD Msg for HS CAN domain ECUs>



- HS-CAN Messages that routed from CAN-FD domain are using 29 bit Extended CAN ID and splitted into 8 Byte Messages.

(from 1 to 4 Msgs, depending on source CAN-FD Msg¡¯s DLC)

- For splitted CAN-FD Msgs¡¯ CRC calculation, HS CAN ECUs should use source CAN-FD Msg¡¯s original STD ID. 

- The original STD ID can be read from Ext ID¡¯s 4~6th Byte.

Eg. STD 0x6AA : EXT SPLT 0x1A8[6AA]01 / 0x1A8[6AA]02 / 0x1A8[6AA]03 / 0x1A8[6AA]04 

(2~4th splitited Msgs can be omitted depending on source CAN-FD Msg¡¯s DLC)

- Aslo, HS-CAN ECUs should use merged data block (from whole splitted Msg) for CRC calculation.";
BA_ "GenSigSendType" SG_ 2395189249 DATC_Crc8Val 4;
BA_ "GenSigStartValue" SG_ 2395189249 DATC_Crc8Val 65535;
BA_ "UserSigValidity" SG_ 2395189249 DATC_Crc8Val 3;
BA_ "Version" SG_ 2395189249 DATC_Crc8Val "21.09.03";
BA_ "Description" SG_ 2395189249 DATC_AlvCnt8Val "For the first transmission request for a data element the counter shall be initialized with 0 and shall be incremented by 1 for every subsequent send request. 

When the counter reaches the maximum value(0xFF), then it shall restart with 0 for the next send request";
BA_ "GenSigSendType" SG_ 2395189249 DATC_AlvCnt8Val 4;
BA_ "UserSigValidity" SG_ 2395189249 DATC_AlvCnt8Val 3;
BA_ "Version" SG_ 2395189249 DATC_AlvCnt8Val "21.09.03";
BA_ "GenSigSendType" SG_ 2395189249 DATC_SmrtVntOnOffSta 4;
BA_ "GenSigStartValue" SG_ 2395189249 DATC_SmrtVntOnOffSta 3;
BA_ "UserSigValidity" SG_ 2395189249 DATC_SmrtVntOnOffSta 3;
BA_ "Version" SG_ 2395189249 DATC_SmrtVntOnOffSta "17.11.00";
BA_ "GenSigSendType" SG_ 2395189249 DATC_PsAutoDis 4;
BA_ "UserSigValidity" SG_ 2395189249 DATC_PsAutoDis 3;
BA_REL_ "GenSigTimeoutTime" BU_SG_REL_ ATS SG_ 2395189249 DATC_PsAutoDis 1500;
BA_ "Version" SG_ 2395189249 DATC_PsAutoDis "17.11.00";
BA_ "GenSigSendType" SG_ 2395189249 DATC_RrAutoDis 4;
BA_ "UserSigValidity" SG_ 2395189249 DATC_RrAutoDis 3;
BA_REL_ "GenSigTimeoutTime" BU_SG_REL_ ATS SG_ 2395189249 DATC_RrAutoDis 1500;
BA_ "Version" SG_ 2395189249 DATC_RrAutoDis "21.07.06";
BA_ "GenSigSendType" SG_ 2395189249 DATC_RrDrvModDis 4;
BA_ "UserSigValidity" SG_ 2395189249 DATC_RrDrvModDis 7;
BA_REL_ "GenSigTimeoutTime" BU_SG_REL_ ATS SG_ 2395189249 DATC_RrDrvModDis 1500;
BA_ "Version" SG_ 2395189249 DATC_RrDrvModDis "21.07.06";
BA_ "GenSigSendType" SG_ 2395189249 DATC_RrPassModDis 4;
BA_ "UserSigValidity" SG_ 2395189249 DATC_RrPassModDis 7;
BA_REL_ "GenSigTimeoutTime" BU_SG_REL_ ATS SG_ 2395189249 DATC_RrPassModDis 1500;
BA_ "Version" SG_ 2395189249 DATC_RrPassModDis "18.11.05";
BA_ "Description" SG_ 2395189249 DATC_DisplayThemes "This signal indicates DATC lcd white or black themes. (only TFT LCD type)";
BA_ "GenSigSendType" SG_ 2395189249 DATC_DisplayThemes 4;
BA_ "UserSigValidity" SG_ 2395189249 DATC_DisplayThemes 7;
BA_ "Version" SG_ 2395189249 DATC_DisplayThemes "20.01.01";
BA_ "Description" SG_ 2395189249 DATC_EcoZoneDis "This signal indicates Eco Zone symbol Display or Indicator";
BA_ "GenSigSendType" SG_ 2395189249 DATC_EcoZoneDis 4;
BA_ "UserSigValidity" SG_ 2395189249 DATC_EcoZoneDis 7;
BA_ "Version" SG_ 2395189249 DATC_EcoZoneDis "24.01.04";
BA_ "Description" SG_ 2395189249 DATC_AUTOStepPS "This signal indicates Passenger AUTO step status in case Multi Auto Blower type.";
BA_ "GenSigSendType" SG_ 2395189249 DATC_AUTOStepPS 4;
BA_ "UserSigValidity" SG_ 2395189249 DATC_AUTOStepPS 7;
BA_REL_ "GenSigTimeoutTime" BU_SG_REL_ ATS SG_ 2395189249 DATC_AUTOStepPS 1500;
BA_ "Version" SG_ 2395189249 DATC_AUTOStepPS "19.12.00";
BA_ "Description" SG_ 2395189249 DATC_AUTOStepRR "This signal indicates Rear AUTO step status in case Multi Auto Blower type.";
BA_ "GenSigSendType" SG_ 2395189249 DATC_AUTOStepRR 4;
BA_ "UserSigValidity" SG_ 2395189249 DATC_AUTOStepRR 7;
BA_REL_ "GenSigTimeoutTime" BU_SG_REL_ ATS SG_ 2395189249 DATC_AUTOStepRR 1500;
BA_ "Version" SG_ 2395189249 DATC_AUTOStepRR "19.12.00";
BA_ "GenMsgCycleTime" BO_ 1882 0;
BA_ "GenMsgCycleTimeFast" BO_ 1882 0;
BA_ "GenMsgNrOfRepetition" BO_ 1882 0;
BA_ "DiagResponse" BO_ 1882 1;
BA_ "GenMsgILSupport" BO_ 1882 0;
BA_ "TpMessage" BO_ 1882 1;
BA_ "TpTxIndex" BO_ 1882 121;
BA_ "Description" SG_ 1882 DLBCU_GST_Byte0 "TP Index : 121";
BA_ "UsrSigPurpose" SG_ 1882 DLBCU_GST_Byte0 4;
BA_ "UserSigValidity" SG_ 1882 DLBCU_GST_Byte0 0;
BA_REL_ "GenSigTimeoutTime" BU_SG_REL_ CGW_CCU SG_ 1882 DLBCU_GST_Byte0 0;
BA_ "NetworkRequest" SG_ 1882 DLBCU_GST_Byte0 0;
BA_ "NetworkRequestHoldingTime" SG_ 1882 DLBCU_GST_Byte0 5000;
BA_ "Version" SG_ 1882 DLBCU_GST_Byte0 "22.07.01";
BA_ "Description" SG_ 1882 DLBCU_GST_Byte2 "TP Index : 121";
BA_ "UsrSigPurpose" SG_ 1882 DLBCU_GST_Byte2 4;
BA_ "UserSigValidity" SG_ 1882 DLBCU_GST_Byte2 0;
BA_REL_ "GenSigTimeoutTime" BU_SG_REL_ CGW_CCU SG_ 1882 DLBCU_GST_Byte2 0;
BA_ "NetworkRequest" SG_ 1882 DLBCU_GST_Byte2 0;
BA_ "NetworkRequestHoldingTime" SG_ 1882 DLBCU_GST_Byte2 5000;
BA_ "Version" SG_ 1882 DLBCU_GST_Byte2 "22.07.01";
BA_ "Description" SG_ 1882 DLBCU_GST_Byte3 "TP Index : 121";
BA_ "UsrSigPurpose" SG_ 1882 DLBCU_GST_Byte3 4;
BA_ "UserSigValidity" SG_ 1882 DLBCU_GST_Byte3 0;
BA_REL_ "GenSigTimeoutTime" BU_SG_REL_ CGW_CCU SG_ 1882 DLBCU_GST_Byte3 0;
BA_ "NetworkRequest" SG_ 1882 DLBCU_GST_Byte3 0;
BA_ "NetworkRequestHoldingTime" SG_ 1882 DLBCU_GST_Byte3 5000;
BA_ "Version" SG_ 1882 DLBCU_GST_Byte3 "22.07.01";
BA_ "Description" SG_ 1882 DLBCU_GST_Byte4 "TP Index : 121";
BA_ "UsrSigPurpose" SG_ 1882 DLBCU_GST_Byte4 4;
BA_ "UserSigValidity" SG_ 1882 DLBCU_GST_Byte4 0;
BA_REL_ "GenSigTimeoutTime" BU_SG_REL_ CGW_CCU SG_ 1882 DLBCU_GST_Byte4 0;
BA_ "NetworkRequest" SG_ 1882 DLBCU_GST_Byte4 0;
BA_ "NetworkRequestHoldingTime" SG_ 1882 DLBCU_GST_Byte4 5000;
BA_ "Version" SG_ 1882 DLBCU_GST_Byte4 "22.07.01";
BA_ "Description" SG_ 1882 DLBCU_GST_Byte5 "TP Index : 121";
BA_ "UsrSigPurpose" SG_ 1882 DLBCU_GST_Byte5 4;
BA_ "UserSigValidity" SG_ 1882 DLBCU_GST_Byte5 0;
BA_REL_ "GenSigTimeoutTime" BU_SG_REL_ CGW_CCU SG_ 1882 DLBCU_GST_Byte5 0;
BA_ "NetworkRequest" SG_ 1882 DLBCU_GST_Byte5 0;
BA_ "NetworkRequestHoldingTime" SG_ 1882 DLBCU_GST_Byte5 5000;
BA_ "Version" SG_ 1882 DLBCU_GST_Byte5 "22.07.01";
BA_ "Description" SG_ 1882 DLBCU_GST_Byte6 "TP Index : 121";
BA_ "UsrSigPurpose" SG_ 1882 DLBCU_GST_Byte6 4;
BA_ "UserSigValidity" SG_ 1882 DLBCU_GST_Byte6 0;
BA_REL_ "GenSigTimeoutTime" BU_SG_REL_ CGW_CCU SG_ 1882 DLBCU_GST_Byte6 0;
BA_ "NetworkRequest" SG_ 1882 DLBCU_GST_Byte6 0;
BA_ "NetworkRequestHoldingTime" SG_ 1882 DLBCU_GST_Byte6 5000;
BA_ "Version" SG_ 1882 DLBCU_GST_Byte6 "22.07.01";
BA_ "Description" SG_ 1882 DLBCU_GST_Byte7 "TP Index : 121";
BA_ "UsrSigPurpose" SG_ 1882 DLBCU_GST_Byte7 4;
BA_ "UserSigValidity" SG_ 1882 DLBCU_GST_Byte7 0;
BA_REL_ "GenSigTimeoutTime" BU_SG_REL_ CGW_CCU SG_ 1882 DLBCU_GST_Byte7 0;
BA_ "NetworkRequest" SG_ 1882 DLBCU_GST_Byte7 0;
BA_ "NetworkRequestHoldingTime" SG_ 1882 DLBCU_GST_Byte7 5000;
BA_ "Version" SG_ 1882 DLBCU_GST_Byte7 "22.07.01";
BA_ "Description" SG_ 1882 DLBCU_GST_Byte1 "TP Index : 121";
BA_ "UsrSigPurpose" SG_ 1882 DLBCU_GST_Byte1 4;
BA_ "UserSigValidity" SG_ 1882 DLBCU_GST_Byte1 0;
BA_REL_ "GenSigTimeoutTime" BU_SG_REL_ CGW_CCU SG_ 1882 DLBCU_GST_Byte1 0;
BA_ "NetworkRequest" SG_ 1882 DLBCU_GST_Byte1 0;
BA_ "NetworkRequestHoldingTime" SG_ 1882 DLBCU_GST_Byte1 5000;
BA_ "Version" SG_ 1882 DLBCU_GST_Byte1 "22.07.01";
BA_ "GenMsgCycleTime" BO_ 1881 0;
BA_ "GenMsgCycleTimeFast" BO_ 1881 0;
BA_ "GenMsgNrOfRepetition" BO_ 1881 0;
BA_ "DiagResponse" BO_ 1881 1;
BA_ "GenMsgILSupport" BO_ 1881 0;
BA_ "TpMessage" BO_ 1881 1;
BA_ "TpTxIndex" BO_ 1881 122;
BA_ "Description" SG_ 1881 DPSS_GST_Byte0 "TP Index : 122";
BA_ "UsrSigPurpose" SG_ 1881 DPSS_GST_Byte0 4;
BA_ "UserSigValidity" SG_ 1881 DPSS_GST_Byte0 0;
BA_REL_ "GenSigTimeoutTime" BU_SG_REL_ CGW_CCU SG_ 1881 DPSS_GST_Byte0 0;
BA_ "NetworkRequest" SG_ 1881 DPSS_GST_Byte0 0;
BA_ "NetworkRequestHoldingTime" SG_ 1881 DPSS_GST_Byte0 5000;
BA_ "Version" SG_ 1881 DPSS_GST_Byte0 "22.07.01";
BA_ "Description" SG_ 1881 DPSS_GST_Byte2 "TP Index : 122";
BA_ "UsrSigPurpose" SG_ 1881 DPSS_GST_Byte2 4;
BA_ "UserSigValidity" SG_ 1881 DPSS_GST_Byte2 0;
BA_REL_ "GenSigTimeoutTime" BU_SG_REL_ CGW_CCU SG_ 1881 DPSS_GST_Byte2 0;
BA_ "NetworkRequest" SG_ 1881 DPSS_GST_Byte2 0;
BA_ "NetworkRequestHoldingTime" SG_ 1881 DPSS_GST_Byte2 5000;
BA_ "Version" SG_ 1881 DPSS_GST_Byte2 "22.07.01";
BA_ "Description" SG_ 1881 DPSS_GST_Byte3 "TP Index : 122";
BA_ "UsrSigPurpose" SG_ 1881 DPSS_GST_Byte3 4;
BA_ "UserSigValidity" SG_ 1881 DPSS_GST_Byte3 0;
BA_REL_ "GenSigTimeoutTime" BU_SG_REL_ CGW_CCU SG_ 1881 DPSS_GST_Byte3 0;
BA_ "NetworkRequest" SG_ 1881 DPSS_GST_Byte3 0;
BA_ "NetworkRequestHoldingTime" SG_ 1881 DPSS_GST_Byte3 5000;
BA_ "Version" SG_ 1881 DPSS_GST_Byte3 "22.07.01";
BA_ "Description" SG_ 1881 DPSS_GST_Byte4 "TP Index : 122";
BA_ "UsrSigPurpose" SG_ 1881 DPSS_GST_Byte4 4;
BA_ "UserSigValidity" SG_ 1881 DPSS_GST_Byte4 0;
BA_REL_ "GenSigTimeoutTime" BU_SG_REL_ CGW_CCU SG_ 1881 DPSS_GST_Byte4 0;
BA_ "NetworkRequest" SG_ 1881 DPSS_GST_Byte4 0;
BA_ "NetworkRequestHoldingTime" SG_ 1881 DPSS_GST_Byte4 5000;
BA_ "Version" SG_ 1881 DPSS_GST_Byte4 "22.07.01";
BA_ "Description" SG_ 1881 DPSS_GST_Byte5 "TP Index : 122";
BA_ "UsrSigPurpose" SG_ 1881 DPSS_GST_Byte5 4;
BA_ "UserSigValidity" SG_ 1881 DPSS_GST_Byte5 0;
BA_REL_ "GenSigTimeoutTime" BU_SG_REL_ CGW_CCU SG_ 1881 DPSS_GST_Byte5 0;
BA_ "NetworkRequest" SG_ 1881 DPSS_GST_Byte5 0;
BA_ "NetworkRequestHoldingTime" SG_ 1881 DPSS_GST_Byte5 5000;
BA_ "Version" SG_ 1881 DPSS_GST_Byte5 "22.07.01";
BA_ "Description" SG_ 1881 DPSS_GST_Byte6 "TP Index : 122";
BA_ "UsrSigPurpose" SG_ 1881 DPSS_GST_Byte6 4;
BA_ "UserSigValidity" SG_ 1881 DPSS_GST_Byte6 0;
BA_REL_ "GenSigTimeoutTime" BU_SG_REL_ CGW_CCU SG_ 1881 DPSS_GST_Byte6 0;
BA_ "NetworkRequest" SG_ 1881 DPSS_GST_Byte6 0;
BA_ "NetworkRequestHoldingTime" SG_ 1881 DPSS_GST_Byte6 5000;
BA_ "Version" SG_ 1881 DPSS_GST_Byte6 "22.07.01";
BA_ "Description" SG_ 1881 DPSS_GST_Byte7 "TP Index : 122";
BA_ "UsrSigPurpose" SG_ 1881 DPSS_GST_Byte7 4;
BA_ "UserSigValidity" SG_ 1881 DPSS_GST_Byte7 0;
BA_REL_ "GenSigTimeoutTime" BU_SG_REL_ CGW_CCU SG_ 1881 DPSS_GST_Byte7 0;
BA_ "NetworkRequest" SG_ 1881 DPSS_GST_Byte7 0;
BA_ "NetworkRequestHoldingTime" SG_ 1881 DPSS_GST_Byte7 5000;
BA_ "Version" SG_ 1881 DPSS_GST_Byte7 "22.07.01";
BA_ "Description" SG_ 1881 DPSS_GST_Byte1 "TP Index : 122";
BA_ "UsrSigPurpose" SG_ 1881 DPSS_GST_Byte1 4;
BA_ "UserSigValidity" SG_ 1881 DPSS_GST_Byte1 0;
BA_REL_ "GenSigTimeoutTime" BU_SG_REL_ CGW_CCU SG_ 1881 DPSS_GST_Byte1 0;
BA_ "NetworkRequest" SG_ 1881 DPSS_GST_Byte1 0;
BA_ "NetworkRequestHoldingTime" SG_ 1881 DPSS_GST_Byte1 5000;
BA_ "Version" SG_ 1881 DPSS_GST_Byte1 "22.07.01";
BA_ "GenMsgSendType" BO_ 2214659329 0;
BA_ "GenMsgCycleTime" BO_ 2214659329 50;
BA_ "GenMsgCycleTimeFast" BO_ 2214659329 0;
BA_ "GenMsgNrOfRepetition" BO_ 2214659329 0;
BA_ "VFrameFormat" BO_ 2214659329 1;
BA_ "Description" SG_ 2214659329 EMS_Crc7Val "The data area for CRC calculation is based on the data length (DLC) of the message DB.

The CRC shall be calculated over the entire data block (excluding the CRC bytes) including the user data, alive counter and Data ID



- CRC Polynomial (0x1021) , Initial Value : 0xFFFF, XOR value : 0x0000, Data ID : Message ID + 0xF800 

- The initial value is for CRC calculation and the message should be sent with the calculated result value. 

- The mathematical expression to 16 bit CRC polynomial is given here. G(x) = x16 + x12 + x5 + 1



<For CRC calculation of CAN-FD Msg for HS CAN domain ECUs>



- HS-CAN Messages that routed from CAN-FD domain are using 29 bit Extended CAN ID and splitted into 8 Byte Messages.

(from 1 to 4 Msgs, depending on source CAN-FD Msg¡¯s DLC)

- For splitted CAN-FD Msgs¡¯ CRC calculation, HS CAN ECUs should use source CAN-FD Msg¡¯s original STD ID. 

- The original STD ID can be read from Ext ID¡¯s 4~6th Byte.

Eg. STD 0x6AA : EXT SPLT 0x1A8[6AA]01 / 0x1A8[6AA]02 / 0x1A8[6AA]03 / 0x1A8[6AA]04 

(2~4th splitited Msgs can be omitted depending on source CAN-FD Msg¡¯s DLC)

- Aslo, HS-CAN ECUs should use merged data block (from whole splitted Msg) for CRC calculation.";
BA_ "GenSigStartValue" SG_ 2214659329 EMS_Crc7Val 65535;
BA_ "UserSigValidity" SG_ 2214659329 EMS_Crc7Val 3;
BA_ "RoutingFactor" SG_ 2214659329 EMS_Crc7Val 5;
BA_ "Version" SG_ 2214659329 EMS_Crc7Val "21.09.03";
BA_ "Description" SG_ 2214659329 EMS_AlvCnt7Val "For the first transmission request for a data element the counter shall be initialized with 0 and shall be incremented by 1 for every subsequent send request. 

When the counter reaches the maximum value(0xFF), then it shall restart with 0 for the next send request";
BA_ "UserSigValidity" SG_ 2214659329 EMS_AlvCnt7Val 3;
BA_ "RoutingFactor" SG_ 2214659329 EMS_AlvCnt7Val 5;
BA_ "Version" SG_ 2214659329 EMS_AlvCnt7Val "21.09.03";
BA_ "Description" SG_ 2214659329 HEV_IndTqVal "Indicated engine torque after torque coordination(intervention)";
BA_ "UserSigValidity" SG_ 2214659329 HEV_IndTqVal 3;
BA_ "RoutingFactor" SG_ 2214659329 HEV_IndTqVal 5;
BA_ "Version" SG_ 2214659329 HEV_IndTqVal "18.10.07";
BA_ "Description" SG_ 2214659329 HEV_DrvTqVal "Driver's demand torque";
BA_ "UserSigValidity" SG_ 2214659329 HEV_DrvTqVal 3;
BA_ "RoutingFactor" SG_ 2214659329 HEV_DrvTqVal 5;
BA_ "Version" SG_ 2214659329 HEV_DrvTqVal "18.05.04";
BA_ "Description" SG_ 2214659329 HEV_TqStndVal "Standard value for torque scaling in torque interface";
BA_ "UserSigValidity" SG_ 2214659329 HEV_TqStndVal 3;
BA_ "RoutingFactor" SG_ 2214659329 HEV_TqStndVal 5;
BA_ "Version" SG_ 2214659329 HEV_TqStndVal "18.05.04";
BA_ "Description" SG_ 2214659329 HEV_OilDilution_IncICELoad "This signal indicates oil dilution ICE load increase mode.";
BA_ "UserSigValidity" SG_ 2214659329 HEV_OilDilution_IncICELoad 3;
BA_ "RoutingFactor" SG_ 2214659329 HEV_OilDilution_IncICELoad 5;
BA_ "Version" SG_ 2214659329 HEV_OilDilution_IncICELoad "22.05.04";
BA_ "Description" SG_ 2214659329 HEV_OilDilution_ServMode "This signal indicates oil dilution service mode.";
BA_ "UserSigValidity" SG_ 2214659329 HEV_OilDilution_ServMode 3;
BA_ "RoutingFactor" SG_ 2214659329 HEV_OilDilution_ServMode 5;
BA_ "Version" SG_ 2214659329 HEV_OilDilution_ServMode "22.05.04";
BA_ "Description" SG_ 2214659329 EMS_TqLmtSta "Status of Torque Limit.";
BA_ "UserSigValidity" SG_ 2214659329 EMS_TqLmtSta 3;
BA_ "RoutingFactor" SG_ 2214659329 EMS_TqLmtSta 5;
BA_ "Version" SG_ 2214659329 EMS_TqLmtSta "23.04.02";
BA_ "Description" SG_ 2214659329 EMS_EU7 "This signal defines if the vehicle is EU7 vehicle.";
BA_ "UserSigValidity" SG_ 2214659329 EMS_EU7 3;
BA_ "RoutingFactor" SG_ 2214659329 EMS_EU7 5;
BA_ "Version" SG_ 2214659329 EMS_EU7 "23.04.02";
BA_ "GenMsgSendType" BO_ 2214659330 0;
BA_ "GenMsgCycleTime" BO_ 2214659330 50;
BA_ "GenMsgCycleTimeFast" BO_ 2214659330 0;
BA_ "GenMsgNrOfRepetition" BO_ 2214659330 0;
BA_ "VFrameFormat" BO_ 2214659330 1;
BA_ "Description" SG_ 2214659330 HEV_FrctTqVal "Friction Loss Torque";
BA_ "UserSigValidity" SG_ 2214659330 HEV_FrctTqVal 3;
BA_ "RoutingFactor" SG_ 2214659330 HEV_FrctTqVal 5;
BA_ "Version" SG_ 2214659330 HEV_FrctTqVal "18.10.07";
BA_ "Description" SG_ 2214659330 HEV_EngSpdVal "Engine Speed";
BA_ "UserSigValidity" SG_ 2214659330 HEV_EngSpdVal 3;
BA_ "RoutingFactor" SG_ 2214659330 HEV_EngSpdVal 5;
BA_ "Version" SG_ 2214659330 HEV_EngSpdVal "18.05.04";
BA_ "Description" SG_ 2214659330 HEV_EngOpSta "Engine Operating State";
BA_ "UserSigValidity" SG_ 2214659330 HEV_EngOpSta 3;
BA_ "RoutingFactor" SG_ 2214659330 HEV_EngOpSta 5;
BA_ "Version" SG_ 2214659330 HEV_EngOpSta "18.05.04";
BA_ "Description" SG_ 2214659330 HEV_IntakeAirTempVal "Intake air temperature";
BA_ "UserSigValidity" SG_ 2214659330 HEV_IntakeAirTempVal 3;
BA_ "RoutingFactor" SG_ 2214659330 HEV_IntakeAirTempVal 5;
BA_ "Version" SG_ 2214659330 HEV_IntakeAirTempVal "18.05.04";
BA_ "Description" SG_ 2214659330 HEV_AccelPdlVal "The signal is a measure of the Accelerator Pedal value.

The accelerator pedal value is determined via 2 pedal sensors, which are connected mechanically to the accelerator pedal. If the EMS-ECU recognizes that the accelerator pedal is not activated, then the value 00 H is carried over on the CAN. If the EMS-ECU detects that the accelerator pedal is fully activated, then 3FE H is carried over on the CAN bus.

If an error is detected on both pedal sensor channels, this is identified by the value 3FFH";
BA_ "UserSigValidity" SG_ 2214659330 HEV_AccelPdlVal 3;
BA_ "RoutingFactor" SG_ 2214659330 HEV_AccelPdlVal 5;
BA_ "Version" SG_ 2214659330 HEV_AccelPdlVal "19.11.11";
BA_ "Description" SG_ 2214659330 HEV_IndTqTar "Indicated Engine (Desired) Torque";
BA_ "UserSigValidity" SG_ 2214659330 HEV_IndTqTar 3;
BA_ "RoutingFactor" SG_ 2214659330 HEV_IndTqTar 5;
BA_ "Version" SG_ 2214659330 HEV_IndTqTar "18.05.04";
BA_ "GenMsgSendType" BO_ 2214659331 0;
BA_ "GenMsgCycleTime" BO_ 2214659331 50;
BA_ "GenMsgCycleTimeFast" BO_ 2214659331 0;
BA_ "GenMsgNrOfRepetition" BO_ 2214659331 0;
BA_ "VFrameFormat" BO_ 2214659331 1;
BA_ "GenMsgSendType" BO_ 2214659332 0;
BA_ "GenMsgCycleTime" BO_ 2214659332 50;
BA_ "GenMsgCycleTimeFast" BO_ 2214659332 0;
BA_ "GenMsgNrOfRepetition" BO_ 2214659332 0;
BA_ "VFrameFormat" BO_ 2214659332 1;
BA_ "GenMsgSendType" BO_ 2307024129 0;
BA_ "GenMsgCycleTimeFast" BO_ 2307024129 0;
BA_ "GenMsgNrOfRepetition" BO_ 2307024129 0;
BA_ "VFrameFormat" BO_ 2307024129 1;
BA_ "Description" SG_ 2307024129 EMS_Crc8Val "The data area for CRC calculation is based on the data length (DLC) of the message DB.

The CRC shall be calculated over the entire data block (excluding the CRC bytes) including the user data, alive counter and Data ID



- CRC Polynomial (0x1021) , Initial Value : 0xFFFF, XOR value : 0x0000, Data ID : Message ID + 0xF800 

- The initial value is for CRC calculation and the message should be sent with the calculated result value. 

- The mathematical expression to 16 bit CRC polynomial is given here. G(x) = x16 + x12 + x5 + 1



<For CRC calculation of CAN-FD Msg for HS CAN domain ECUs>



- HS-CAN Messages that routed from CAN-FD domain are using 29 bit Extended CAN ID and splitted into 8 Byte Messages.

(from 1 to 4 Msgs, depending on source CAN-FD Msg¡¯s DLC)

- For splitted CAN-FD Msgs¡¯ CRC calculation, HS CAN ECUs should use source CAN-FD Msg¡¯s original STD ID. 

- The original STD ID can be read from Ext ID¡¯s 4~6th Byte.

Eg. STD 0x6AA : EXT SPLT 0x1A8[6AA]01 / 0x1A8[6AA]02 / 0x1A8[6AA]03 / 0x1A8[6AA]04 

(2~4th splitited Msgs can be omitted depending on source CAN-FD Msg¡¯s DLC)

- Aslo, HS-CAN ECUs should use merged data block (from whole splitted Msg) for CRC calculation.";
BA_ "GenSigStartValue" SG_ 2307024129 EMS_Crc8Val 65535;
BA_ "UserSigValidity" SG_ 2307024129 EMS_Crc8Val 3;
BA_ "RoutingFactor" SG_ 2307024129 EMS_Crc8Val 2;
BA_ "Version" SG_ 2307024129 EMS_Crc8Val "21.09.03";
BA_ "Description" SG_ 2307024129 EMS_AlvCnt8Val "For the first transmission request for a data element the counter shall be initialized with 0 and shall be incremented by 1 for every subsequent send request. 

When the counter reaches the maximum value(0xFF), then it shall restart with 0 for the next send request";
BA_ "UserSigValidity" SG_ 2307024129 EMS_AlvCnt8Val 3;
BA_ "RoutingFactor" SG_ 2307024129 EMS_AlvCnt8Val 2;
BA_ "Version" SG_ 2307024129 EMS_AlvCnt8Val "21.09.03";
BA_ "Description" SG_ 2307024129 HEV_EngClntTempVal "Engine coolant temperature";
BA_ "UserSigValidity" SG_ 2307024129 HEV_EngClntTempVal 3;
BA_ "RoutingFactor" SG_ 2307024129 HEV_EngClntTempVal 2;
BA_ "Version" SG_ 2307024129 HEV_EngClntTempVal "17.11.00";
BA_ "Description" SG_ 2307024129 HEV_EngOilTempVal "Engine Oil Temperature";
BA_ "UserSigValidity" SG_ 2307024129 HEV_EngOilTempVal 3;
BA_ "RoutingFactor" SG_ 2307024129 HEV_EngOilTempVal 2;
BA_ "Version" SG_ 2307024129 HEV_EngOilTempVal "17.11.00";
BA_ "Description" SG_ 2307024129 HEV_VbOffActSta "ECU adaptive values and failure memory erase after battery disconnection";
BA_ "UserSigValidity" SG_ 2307024129 HEV_VbOffActSta 3;
BA_ "RoutingFactor" SG_ 2307024129 HEV_VbOffActSta 2;
BA_ "Version" SG_ 2307024129 HEV_VbOffActSta "17.11.00";
BA_ "Description" SG_ 2307024129 HEV_AirCompOffReq "air conditioner compressor off request";
BA_ "UserSigValidity" SG_ 2307024129 HEV_AirCompOffReq 3;
BA_ "RoutingFactor" SG_ 2307024129 HEV_AirCompOffReq 2;
BA_ "Version" SG_ 2307024129 HEV_AirCompOffReq "17.11.00";
BA_ "Description" SG_ 2307024129 HEV_MilConfgVal "Configuration of MIL handing and failure memory management";
BA_ "UserSigValidity" SG_ 2307024129 HEV_MilConfgVal 3;
BA_ "RoutingFactor" SG_ 2307024129 HEV_MilConfgVal 2;
BA_ "Version" SG_ 2307024129 HEV_MilConfgVal "17.11.00";
BA_ "Description" SG_ 2307024129 HEV_CF_EMS_LOCKUP "Engine lock up maintenance request state

0x0 : Engine doesn't require lock up maintenance

0x1 : Engine require lock up mainentance";
BA_ "UserSigValidity" SG_ 2307024129 HEV_CF_EMS_LOCKUP 3;
BA_ "RoutingFactor" SG_ 2307024129 HEV_CF_EMS_LOCKUP 2;
BA_ "Version" SG_ 2307024129 HEV_CF_EMS_LOCKUP "18.10.12";
BA_ "Description" SG_ 2307024129 HEV_OilLvlSta "This signal indicates the replace time of engine oil.";
BA_ "UserSigValidity" SG_ 2307024129 HEV_OilLvlSta 3;
BA_ "RoutingFactor" SG_ 2307024129 HEV_OilLvlSta 2;
BA_ "Version" SG_ 2307024129 HEV_OilLvlSta "20.12.04";
BA_ "Description" SG_ 2307024129 HEV_ImmoLmpReq "Immobilizer Lamp";
BA_ "UserSigValidity" SG_ 2307024129 HEV_ImmoLmpReq 3;
BA_ "RoutingFactor" SG_ 2307024129 HEV_ImmoLmpReq 2;
BA_ "Version" SG_ 2307024129 HEV_ImmoLmpReq "17.11.00";
BA_ "Description" SG_ 2307024129 HEV_MilReq "This signal indicates the status of MIL physical output.";
BA_ "UserSigValidity" SG_ 2307024129 HEV_MilReq 3;
BA_ "RoutingFactor" SG_ 2307024129 HEV_MilReq 2;
BA_ "Version" SG_ 2307024129 HEV_MilReq "17.11.00";
BA_ "Description" SG_ 2307024129 HEV_WiperSwSta "This signal indicates the status of a wiper switch.";
BA_ "UserSigValidity" SG_ 2307024129 HEV_WiperSwSta 3;
BA_ "RoutingFactor" SG_ 2307024129 HEV_WiperSwSta 2;
BA_ "Version" SG_ 2307024129 HEV_WiperSwSta "17.11.00";
BA_ "Description" SG_ 2307024129 HEV_FanOpSta "This signal indicates whether the cooling/condenser fan is operating or not.";
BA_ "UserSigValidity" SG_ 2307024129 HEV_FanOpSta 3;
BA_ "RoutingFactor" SG_ 2307024129 HEV_FanOpSta 2;
BA_ "Version" SG_ 2307024129 HEV_FanOpSta "17.11.00";
BA_ "Description" SG_ 2307024129 HEV_FanSta "This signal indicates the operating state of the cooling/condenser fan.";
BA_ "UserSigValidity" SG_ 2307024129 HEV_FanSta 3;
BA_ "RoutingFactor" SG_ 2307024129 HEV_FanSta 2;
BA_ "Version" SG_ 2307024129 HEV_FanSta "17.11.00";
BA_ "Description" SG_ 2307024129 HEV_BrkLtSwSta "Brake light Switch";
BA_ "UserSigValidity" SG_ 2307024129 HEV_BrkLtSwSta 3;
BA_REL_ "GenSigTimeoutTime" BU_SG_REL_ BLTN_CAM SG_ 2307024129 HEV_BrkLtSwSta 1500;
BA_ "RoutingFactor" SG_ 2307024129 HEV_BrkLtSwSta 2;
BA_ "Version" SG_ 2307024129 HEV_BrkLtSwSta "17.11.00";
BA_ "GenMsgSendType" BO_ 2307024130 0;
BA_ "GenMsgCycleTimeFast" BO_ 2307024130 0;
BA_ "GenMsgNrOfRepetition" BO_ 2307024130 0;
BA_ "VFrameFormat" BO_ 2307024130 1;
BA_ "Description" SG_ 2307024130 HEV_IgnCycCntVal "Number of driving cycle since first ECU power-up. The counter increases each time a driving cycle with engine running for a specified time duration is detected. This value is only initialized with 0 on saved RAM lost (or reprogramming).";
BA_ "UserSigValidity" SG_ 2307024130 HEV_IgnCycCntVal 3;
BA_ "RoutingFactor" SG_ 2307024130 HEV_IgnCycCntVal 2;
BA_ "Version" SG_ 2307024130 HEV_IgnCycCntVal "17.11.00";
BA_ "Description" SG_ 2307024130 HEV_SoakTimeVal "Engine soaking time";
BA_ "UserSigValidity" SG_ 2307024130 HEV_SoakTimeVal 3;
BA_ "RoutingFactor" SG_ 2307024130 HEV_SoakTimeVal 2;
BA_ "Version" SG_ 2307024130 HEV_SoakTimeVal "17.11.00";
BA_ "Description" SG_ 2307024130 HEV_SoakTimeErrSta "If the HEV_SoakTimeErrSta = 1 then the engine is in fuel cut off state, i.e. e. no injection is applied.";
BA_ "UserSigValidity" SG_ 2307024130 HEV_SoakTimeErrSta 3;
BA_ "RoutingFactor" SG_ 2307024130 HEV_SoakTimeErrSta 2;
BA_ "Version" SG_ 2307024130 HEV_SoakTimeErrSta "19.11.11";
BA_ "UserSigValidity" SG_ 2307024130 HEV_SoakTimeOvrSta 3;
BA_ "RoutingFactor" SG_ 2307024130 HEV_SoakTimeOvrSta 2;
BA_ "Version" SG_ 2307024130 HEV_SoakTimeOvrSta "18.12.01";
BA_ "UserSigValidity" SG_ 2307024130 HEV_FuelRunOutSta 3;
BA_ "RoutingFactor" SG_ 2307024130 HEV_FuelRunOutSta 2;
BA_ "Version" SG_ 2307024130 HEV_FuelRunOutSta "17.11.00";
BA_ "UserSigValidity" SG_ 2307024130 HEV_FuelRunOutDetSta 3;
BA_ "RoutingFactor" SG_ 2307024130 HEV_FuelRunOutDetSta 2;
BA_ "Version" SG_ 2307024130 HEV_FuelRunOutDetSta "17.11.00";
BA_ "Description" SG_ 2307024130 HEV_FuelCnsmptSumVal "Fuel Comsumption summed";
BA_ "UserSigValidity" SG_ 2307024130 HEV_FuelCnsmptSumVal 3;
BA_ "RoutingFactor" SG_ 2307024130 HEV_FuelCnsmptSumVal 2;
BA_ "Version" SG_ 2307024130 HEV_FuelCnsmptSumVal "17.11.00";
BA_ "GenMsgSendType" BO_ 2307024131 0;
BA_ "GenMsgCycleTimeFast" BO_ 2307024131 0;
BA_ "GenMsgNrOfRepetition" BO_ 2307024131 0;
BA_ "VFrameFormat" BO_ 2307024131 1;
BA_ "Description" SG_ 2307024131 HEV_EstClntTempVal "Estimated Engine Coolant Temperature";
BA_ "UserSigValidity" SG_ 2307024131 HEV_EstClntTempVal 3;
BA_ "RoutingFactor" SG_ 2307024131 HEV_EstClntTempVal 2;
BA_ "Version" SG_ 2307024131 HEV_EstClntTempVal "17.11.00";
BA_ "Description" SG_ 2307024131 HEV_EstAmbtAirTempVal "Estimated Ambient air temperature";
BA_ "GenSigStartValue" SG_ 2307024131 HEV_EstAmbtAirTempVal 91;
BA_ "UserSigValidity" SG_ 2307024131 HEV_EstAmbtAirTempVal 3;
BA_ "RoutingFactor" SG_ 2307024131 HEV_EstAmbtAirTempVal 2;
BA_ "Version" SG_ 2307024131 HEV_EstAmbtAirTempVal "17.11.00";
BA_ "Description" SG_ 2307024131 HEV_RbmSta "Status of rate-based monitoring



Value Description



Bit0 : minimum trip length condition 

Bit1 : vehicle speed condition 

Bit2 : continuous idle condition 

Bit3 : ambient temperature condition 

Bit4 : maximum altitude condition 

Bit5 : fuel engine operation

Bit6 : cold start condition for HEV";
BA_ "UserSigValidity" SG_ 2307024131 HEV_RbmSta 3;
BA_ "RoutingFactor" SG_ 2307024131 HEV_RbmSta 2;
BA_ "Version" SG_ 2307024131 HEV_RbmSta "19.11.11";
BA_ "Description" SG_ 2307024131 HEV_WarmUpReq_For_DATC "Flag indicating an EMS request not to stop the engine.

 * This signal is for reference on the DATC.

 * This signal is same as HEV_WarmUpReq (@EMS_09_10ms).";
BA_ "UserSigValidity" SG_ 2307024131 HEV_WarmUpReq_For_DATC 3;
BA_ "RoutingFactor" SG_ 2307024131 HEV_WarmUpReq_For_DATC 2;
BA_ "Version" SG_ 2307024131 HEV_WarmUpReq_For_DATC "19.09.04";
BA_ "Description" SG_ 2307024131 HEV_RbmInhbtSta "Inhibition of rate based monitoring";
BA_ "UserSigValidity" SG_ 2307024131 HEV_RbmInhbtSta 3;
BA_ "RoutingFactor" SG_ 2307024131 HEV_RbmInhbtSta 2;
BA_ "Version" SG_ 2307024131 HEV_RbmInhbtSta "17.11.00";
BA_ "Description" SG_ 2307024131 HEV_EhrsTempSta "The  signal is condition about EHRS' temperature";
BA_ "UserSigValidity" SG_ 2307024131 HEV_EhrsTempSta 3;
BA_ "RoutingFactor" SG_ 2307024131 HEV_EhrsTempSta 2;
BA_ "Version" SG_ 2307024131 HEV_EhrsTempSta "17.11.00";
BA_ "Description" SG_ 2307024131 HEV_Aaf_WrnLamp "Air Flap Warning Lamp/Message Request Signal indicates whether Warning Lamp/Message should be displayed in the display screen in order to warn AAF System failure to customer.";
BA_ "UserSigValidity" SG_ 2307024131 HEV_Aaf_WrnLamp 3;
BA_ "RoutingFactor" SG_ 2307024131 HEV_Aaf_WrnLamp 2;
BA_ "Version" SG_ 2307024131 HEV_Aaf_WrnLamp "19.11.11";
BA_ "Description" SG_ 2307024131 HEV_OPSFail "The signal indicates the status of the 'Oil Pressure Warning Lamp'";
BA_ "UserSigValidity" SG_ 2307024131 HEV_OPSFail 3;
BA_ "RoutingFactor" SG_ 2307024131 HEV_OPSFail 2;
BA_ "Version" SG_ 2307024131 HEV_OPSFail "18.05.04";
BA_ "Description" SG_ 2307024131 HEV_EngDsplceTyp "This signal indicates the engine displacement (volume).";
BA_ "UserSigValidity" SG_ 2307024131 HEV_EngDsplceTyp 3;
BA_ "RoutingFactor" SG_ 2307024131 HEV_EngDsplceTyp 2;
BA_ "Version" SG_ 2307024131 HEV_EngDsplceTyp "19.07.01";
BA_ "UserSigValidity" SG_ 2307024131 HEV_EngTyp2 3;
BA_ "RoutingFactor" SG_ 2307024131 HEV_EngTyp2 2;
BA_ "Version" SG_ 2307024131 HEV_EngTyp2 "19.07.01";
BA_ "UserSigValidity" SG_ 2307024131 HEV_EngTyp1 3;
BA_ "RoutingFactor" SG_ 2307024131 HEV_EngTyp1 2;
BA_ "Version" SG_ 2307024131 HEV_EngTyp1 "19.07.01";
BA_ "Description" SG_ 2307024131 HEV_S_F "AMS/ISG system type indicator";
BA_ "UserSigValidity" SG_ 2307024131 HEV_S_F 3;
BA_ "RoutingFactor" SG_ 2307024131 HEV_S_F 2;
BA_ "Version" SG_ 2307024131 HEV_S_F "19.07.01";
BA_ "Description" SG_ 2307024131 HEV_S_F_GEN "system generation type indicator";
BA_ "UserSigValidity" SG_ 2307024131 HEV_S_F_GEN 3;
BA_ "RoutingFactor" SG_ 2307024131 HEV_S_F_GEN 2;
BA_ "Version" SG_ 2307024131 HEV_S_F_GEN "19.07.01";
BA_ "Description" SG_ 2307024131 HEV_AptVal "APT Value";
BA_ "UserSigValidity" SG_ 2307024131 HEV_AptVal 3;
BA_ "RoutingFactor" SG_ 2307024131 HEV_AptVal 2;
BA_ "Version" SG_ 2307024131 HEV_AptVal "17.11.00";
BA_ "GenMsgSendType" BO_ 2307024132 0;
BA_ "GenMsgCycleTimeFast" BO_ 2307024132 0;
BA_ "GenMsgNrOfRepetition" BO_ 2307024132 0;
BA_ "VFrameFormat" BO_ 2307024132 1;
BA_ "Description" SG_ 2307024132 HEV_RbmSta_2nd "Status of rate-based monitoring



Value Description

Bit0 : cold start condition for PHEV

Bit1 : cold start inhibition condition for HEV/PHEV

Bit2 : reserved

Bit3 : reserved

Bit4 : reserved

Bit5 : reserved

Bit6 : reserved";
BA_ "UserSigValidity" SG_ 2307024132 HEV_RbmSta_2nd 3;
BA_ "RoutingFactor" SG_ 2307024132 HEV_RbmSta_2nd 2;
BA_ "Version" SG_ 2307024132 HEV_RbmSta_2nd "19.10.00";
BA_ "Description" SG_ 2307024132 HEV_OilLifeRatio "EMS calculates remaining engine oil life, and Cluster displays this information with % unit, in order to guide driver to change engine oil.";
BA_ "UserSigValidity" SG_ 2307024132 HEV_OilLifeRatio 3;
BA_ "RoutingFactor" SG_ 2307024132 HEV_OilLifeRatio 2;
BA_ "Version" SG_ 2307024132 HEV_OilLifeRatio "20.12.04";
BA_ "Description" SG_ 2307024132 HEV_OilLifeEna "Cluster displays engine oil life warning and life ratio signal if this enabling bit is true.";
BA_ "UserSigValidity" SG_ 2307024132 HEV_OilLifeEna 3;
BA_ "RoutingFactor" SG_ 2307024132 HEV_OilLifeEna 2;
BA_ "Version" SG_ 2307024132 HEV_OilLifeEna "20.12.04";
BA_ "Description" SG_ 2307024132 HEV_OilLifeWarn "This signal indicates status of engine oil life warning.";
BA_ "UserSigValidity" SG_ 2307024132 HEV_OilLifeWarn 3;
BA_ "RoutingFactor" SG_ 2307024132 HEV_OilLifeWarn 2;
BA_ "Version" SG_ 2307024132 HEV_OilLifeWarn "20.12.04";
BA_ "Description" SG_ 2307024132 HEV_ExtSoakTimeVal "The SoakTimeExt is the Additional soak time information, which start to increase from the moment that Soak Time is over 255 min.



Total Soak Time [min] = 1 * HEV_SoakTimeVal (EMS_08_100ms) [min] + 5 * HEV_ExtSoakTimeVal (EMS_08_100ms) [min]";
BA_ "UserSigValidity" SG_ 2307024132 HEV_ExtSoakTimeVal 3;
BA_ "RoutingFactor" SG_ 2307024132 HEV_ExtSoakTimeVal 2;
BA_ "Version" SG_ 2307024132 HEV_ExtSoakTimeVal "21.06.08";
BA_ "Description" SG_ 2307024132 HEV_RECTrigSta "Trigger signal(10 event) - when REC is occurred in the HEV ECU(Engine controller)";
BA_ "UserSigValidity" SG_ 2307024132 HEV_RECTrigSta 3;
BA_ "RoutingFactor" SG_ 2307024132 HEV_RECTrigSta 2;
BA_ "Version" SG_ 2307024132 HEV_RECTrigSta "20.02.02";
BA_ "Description" SG_ 2307024132 HEV_PendingTrigSta "Trigger signal(10 event) - when Pending DTC is occurred in the HEV ECU(Engine controller)";
BA_ "UserSigValidity" SG_ 2307024132 HEV_PendingTrigSta 3;
BA_ "RoutingFactor" SG_ 2307024132 HEV_PendingTrigSta 2;
BA_ "Version" SG_ 2307024132 HEV_PendingTrigSta "20.02.02";
BA_ "GenMsgSendType" BO_ 2277634049 0;
BA_ "GenMsgCycleTime" BO_ 2277634049 150;
BA_ "GenMsgCycleTimeFast" BO_ 2277634049 0;
BA_ "GenMsgNrOfRepetition" BO_ 2277634049 0;
BA_ "VFrameFormat" BO_ 2277634049 1;
BA_ "Description" SG_ 2277634049 EPB_Crc1Val "The data area for CRC calculation is based on the data length (DLC) of the message DB.

The CRC shall be calculated over the entire data block (excluding the CRC bytes) including the user data, alive counter and Data ID



- CRC Polynomial (0x1021) , Initial Value : 0xFFFF, XOR value : 0x0000, Data ID : Message ID + 0xF800 

- The initial value is for CRC calculation and the message should be sent with the calculated result value. 

- The mathematical expression to 16 bit CRC polynomial is given here. G(x) = x16 + x12 + x5 + 1



<For CRC calculation of CAN-FD Msg for HS CAN domain ECUs>



- HS-CAN Messages that routed from CAN-FD domain are using 29 bit Extended CAN ID and splitted into 8 Byte Messages.

(from 1 to 4 Msgs, depending on source CAN-FD Msg¡¯s DLC)

- For splitted CAN-FD Msgs¡¯ CRC calculation, HS CAN ECUs should use source CAN-FD Msg¡¯s original STD ID. 

- The original STD ID can be read from Ext ID¡¯s 4~6th Byte.

Eg. STD 0x6AA : EXT SPLT 0x1A8[6AA]01 / 0x1A8[6AA]02 / 0x1A8[6AA]03 / 0x1A8[6AA]04 

(2~4th splitited Msgs can be omitted depending on source CAN-FD Msg¡¯s DLC)

- Aslo, HS-CAN ECUs should use merged data block (from whole splitted Msg) for CRC calculation.";
BA_ "GenSigStartValue" SG_ 2277634049 EPB_Crc1Val 65535;
BA_ "UserSigValidity" SG_ 2277634049 EPB_Crc1Val 3;
BA_ "RoutingFactor" SG_ 2277634049 EPB_Crc1Val 3;
BA_ "Version" SG_ 2277634049 EPB_Crc1Val "21.09.03";
BA_ "Description" SG_ 2277634049 EPB_AlvCnt1Val "For the first transmission request for a data element the counter shall be initialized with 0 and shall be incremented by 1 for every subsequent send request. 

When the counter reaches the maximum value(0xFF), then it shall restart with 0 for the next send request";
BA_ "UserSigValidity" SG_ 2277634049 EPB_AlvCnt1Val 3;
BA_ "RoutingFactor" SG_ 2277634049 EPB_AlvCnt1Val 3;
BA_ "Version" SG_ 2277634049 EPB_AlvCnt1Val "21.09.03";
BA_ "Description" SG_ 2277634049 EPB_LmpStaDis "This signal indicates status lamp request from EPB to lamp control unit.

- If a lamp control unit can not get this signal via CAN due to any errors, the last lamp state before the error should be maintained.

- When EPB apply switch is pressed in the IG-key off sate, the parking brake lamp should be on for 15 seconds and off. In this case, the cluster shall have CAN wake-up capability.



EPB_LmpStaDis(0H) - Parking brake lamp status (Off)

EPB_LmpStaDis(1H) - Parking brake lamp status (On)

EPB_LmpStaDis(2H) - Parking brake lamp status (Blinking at 1Hz)";
BA_ "UserSigValidity" SG_ 2277634049 EPB_LmpStaDis 3;
BA_REL_ "GenSigTimeoutTime" BU_SG_REL_ GW_APSU SG_ 2277634049 EPB_LmpStaDis 1500;
BA_REL_ "GenSigTimeoutTime" BU_SG_REL_ GW_DPSU SG_ 2277634049 EPB_LmpStaDis 1500;
BA_REL_ "GenSigTimeoutTime" BU_SG_REL_ GW_RLPSU SG_ 2277634049 EPB_LmpStaDis 1500;
BA_REL_ "GenSigTimeoutTime" BU_SG_REL_ GW_RRPSU SG_ 2277634049 EPB_LmpStaDis 1500;
BA_REL_ "GenSigTimeoutTime" BU_SG_REL_ PFSU SG_ 2277634049 EPB_LmpStaDis 1500;
BA_REL_ "GenSigTimeoutTime" BU_SG_REL_ RLHV SG_ 2277634049 EPB_LmpStaDis 1500;
BA_REL_ "GenSigTimeoutTime" BU_SG_REL_ RRHV SG_ 2277634049 EPB_LmpStaDis 1500;
BA_ "RoutingFactor" SG_ 2277634049 EPB_LmpStaDis 3;
BA_ "Version" SG_ 2277634049 EPB_LmpStaDis "20.07.03";
BA_ "Description" SG_ 2277634049 EPB_FlrLmpStaDis "Information about the failure lamp request from EPB to lamp control unit.



EPB_F_LAMP(0H) - Yellow failure lamp status(Off)

EPB_F_LAMP(1H) - Yellow failure lamp status(On)

EPB_F_LAMP(2H) - Yellow failure lamp status(Blinking at 1 Hz)";
BA_ "UserSigValidity" SG_ 2277634049 EPB_FlrLmpStaDis 3;
BA_ "RoutingFactor" SG_ 2277634049 EPB_FlrLmpStaDis 3;
BA_ "Version" SG_ 2277634049 EPB_FlrLmpStaDis "17.12.00";
BA_ "Description" SG_ 2277634049 EPB_OutDataDis "An EPB can show its information message to driver on a cluster or a display module with this signal. ¡Ø 0x4 is for China";
BA_ "UserSigValidity" SG_ 2277634049 EPB_OutDataDis 3;
BA_ "RoutingFactor" SG_ 2277634049 EPB_OutDataDis 3;
BA_ "Version" SG_ 2277634049 EPB_OutDataDis "22.07.06";
BA_ "Description" SG_ 2277634049 EPB_AlrmReq "This signal indicates that an EPB requests cluster or tone controller to ring the alarm according to the status of an EPB.



Conversion [Condition]

0H : Normal operation

1H : EPB_CLU = 2 or 3

(send signals three time in a row & 1st signal should be sent at the same time as corresponding EPB_CLU 1st Signal)

2H : Dynamic braking[ECD, RWU] (send signal continuously)

3H : Reserved";
BA_ "UserSigValidity" SG_ 2277634049 EPB_AlrmReq 3;
BA_ "RoutingFactor" SG_ 2277634049 EPB_AlrmReq 3;
BA_ "Version" SG_ 2277634049 EPB_AlrmReq "17.12.00";
BA_ "Description" SG_ 2277634049 EPB_SwPosSta "Information about the EPB control switch state";
BA_ "UserSigValidity" SG_ 2277634049 EPB_SwPosSta 3;
BA_ "RoutingFactor" SG_ 2277634049 EPB_SwPosSta 3;
BA_ "Version" SG_ 2277634049 EPB_SwPosSta "17.12.00";
BA_ "Description" SG_ 2277634049 EPB_RrBrkLtActvReq "If an EPB acts braking and the vehicle speed is higher than pre-defined condition then rear brake lamp shall be turned on. This signal requests ESC or brake lamp controller to turn on rear brake lamp.";
BA_ "UserSigValidity" SG_ 2277634049 EPB_RrBrkLtActvReq 3;
BA_ "RoutingFactor" SG_ 2277634049 EPB_RrBrkLtActvReq 3;
BA_ "Version" SG_ 2277634049 EPB_RrBrkLtActvReq "17.12.00";
BA_ "Description" SG_ 2277634049 EPB_FrcErrSta "Detail descriptions of error status of EPB force if EPB_FrcErrSta = 00H";
BA_ "UserSigValidity" SG_ 2277634049 EPB_FrcErrSta 3;
BA_ "RoutingFactor" SG_ 2277634049 EPB_FrcErrSta 3;
BA_ "Version" SG_ 2277634049 EPB_FrcErrSta "17.12.00";
BA_ "Description" SG_ 2277634049 EPB_DynmBrkFrcReqSigSta "This signal indicates the validity of EPB_DynmBrkFrcReqSigSta (EPB request for ESP to activate Dynamic Brake Function) signal.";
BA_ "GenSigStartValue" SG_ 2277634049 EPB_DynmBrkFrcReqSigSta 1;
BA_ "UserSigValidity" SG_ 2277634049 EPB_DynmBrkFrcReqSigSta 3;
BA_ "RoutingFactor" SG_ 2277634049 EPB_DynmBrkFrcReqSigSta 3;
BA_ "Version" SG_ 2277634049 EPB_DynmBrkFrcReqSigSta "17.12.00";
BA_ "Description" SG_ 2277634049 EPB_FrcSta "Information about the force status of the EPB";
BA_ "UserSigValidity" SG_ 2277634049 EPB_FrcSta 3;
BA_ "RoutingFactor" SG_ 2277634049 EPB_FrcSta 3;
BA_ "Version" SG_ 2277634049 EPB_FrcSta "17.12.00";
BA_ "Description" SG_ 2277634049 EPB_FlSta "Information about availability of EPB. If this bit is set (EPB is not available), EPB motor control is not possible, e.g. by external AVH request.";
BA_ "GenSigStartValue" SG_ 2277634049 EPB_FlSta 2;
BA_ "UserSigValidity" SG_ 2277634049 EPB_FlSta 3;
BA_ "RoutingFactor" SG_ 2277634049 EPB_FlSta 3;
BA_ "Version" SG_ 2277634049 EPB_FlSta "17.12.00";
BA_ "Description" SG_ 2277634049 EPB_EscReqAckSta "Acknowledge signal for ESC request (e.g. AVH).



ESC sends request to release (1) or clamping (2) via signal REQ_EPB_ACT. The EPB acknowledges this request with EPB_EscReqAckSta = 1 within the time tESP_REQ_OK (value tbd) and performs according to the requested action. If signal EPB_EscReqAckSta remains = 0 for longer than tESP_REQ_OK, the requested action will be discarded.";
BA_ "UserSigValidity" SG_ 2277634049 EPB_EscReqAckSta 3;
BA_ "RoutingFactor" SG_ 2277634049 EPB_EscReqAckSta 3;
BA_ "Version" SG_ 2277634049 EPB_EscReqAckSta "17.12.00";
BA_ "Description" SG_ 2277634049 EPB_DynmBrkFrcReq "EPB dynamic Braking Request";
BA_ "UserSigValidity" SG_ 2277634049 EPB_DynmBrkFrcReq 3;
BA_ "RoutingFactor" SG_ 2277634049 EPB_DynmBrkFrcReq 3;
BA_ "Version" SG_ 2277634049 EPB_DynmBrkFrcReq "17.12.00";
BA_ "Description" SG_ 2277634049 EPB_EmerModReq "This signal is for requesting EPB emergency mode to eEPB ECU.

- EPB Initialization in Progress: EPB Initialization in Progress

- Emergency EPB Mode : eEPB will response to VCU parking requirement

- Normal EPB Mode : EPB will response to VCU parking requirement";
BA_ "UserSigValidity" SG_ 2277634049 EPB_EmerModReq 3;
BA_ "RoutingFactor" SG_ 2277634049 EPB_EmerModReq 3;
BA_ "Version" SG_ 2277634049 EPB_EmerModReq "22.10.20";
BA_ "GenMsgSendType" BO_ 2277634050 0;
BA_ "GenMsgCycleTime" BO_ 2277634050 150;
BA_ "GenMsgCycleTimeFast" BO_ 2277634050 0;
BA_ "GenMsgNrOfRepetition" BO_ 2277634050 0;
BA_ "VFrameFormat" BO_ 2277634050 1;
BA_ "Description" SG_ 2277634050 EPB_ActlFrcVal "Actual braking force measured by EPB force sensor.";
BA_ "GenSigStartValue" SG_ 2277634050 EPB_ActlFrcVal 1000;
BA_ "UserSigValidity" SG_ 2277634050 EPB_ActlFrcVal 3;
BA_ "RoutingFactor" SG_ 2277634050 EPB_ActlFrcVal 3;
BA_ "Version" SG_ 2277634050 EPB_ActlFrcVal "17.12.00";
BA_ "Description" SG_ 2277634050 EPB_EpbSta4VcuReq "This signal indicates the status of EPB parking actuation operated by VCU's request.";
BA_ "UserSigValidity" SG_ 2277634050 EPB_EpbSta4VcuReq 3;
BA_ "RoutingFactor" SG_ 2277634050 EPB_EpbSta4VcuReq 3;
BA_ "Version" SG_ 2277634050 EPB_EpbSta4VcuReq "22.11.00";
BA_ "Description" SG_ 2277634050 EPB_DynmBrkFrcDclReq "Requested deceleration for DBF. The ESC must consider this value if EPB_DynmBrkFrcReq is equal to 1.";
BA_ "UserSigValidity" SG_ 2277634050 EPB_DynmBrkFrcDclReq 3;
BA_ "RoutingFactor" SG_ 2277634050 EPB_DynmBrkFrcDclReq 3;
BA_ "Version" SG_ 2277634050 EPB_DynmBrkFrcDclReq "17.12.00";
BA_ "Description" SG_ 2277634050 eEPB_EpbSta4VcuReq "This signal indicates the status of eEPB parking actuation operated by VCU's request.";
BA_ "UserSigValidity" SG_ 2277634050 eEPB_EpbSta4VcuReq 3;
BA_ "RoutingFactor" SG_ 2277634050 eEPB_EpbSta4VcuReq 3;
BA_ "Version" SG_ 2277634050 eEPB_EpbSta4VcuReq "22.07.06";
BA_ "Description" SG_ 2277634050 eEPB_EPBSta "Information about availability of EPB. If this bit is set (eEPB is not available), EPB motor control is not possible, e.g. by external VCU request.";
BA_ "UserSigValidity" SG_ 2277634050 eEPB_EPBSta 3;
BA_ "RoutingFactor" SG_ 2277634050 eEPB_EPBSta 3;
BA_ "Version" SG_ 2277634050 eEPB_EPBSta "22.07.06";
BA_ "Description" SG_ 2277634050 EPB_EpbHWCtrlNeedReq "IEB EPB HW Control Need Request";
BA_ "UserSigValidity" SG_ 2277634050 EPB_EpbHWCtrlNeedReq 3;
BA_ "RoutingFactor" SG_ 2277634050 EPB_EpbHWCtrlNeedReq 3;
BA_ "Version" SG_ 2277634050 EPB_EpbHWCtrlNeedReq "22.10.20";
BA_ "Description" SG_ 2277634050 EPB_EpbHwCtrState "IEB EPB HW Control State";
BA_ "UserSigValidity" SG_ 2277634050 EPB_EpbHwCtrState 3;
BA_ "RoutingFactor" SG_ 2277634050 EPB_EpbHwCtrState 3;
BA_ "Version" SG_ 2277634050 EPB_EpbHwCtrState "22.11.07";
BA_ "Description" SG_ 2277634050 EPB_EpbActivated "IEB Left EPB Activation Information";
BA_ "UserSigValidity" SG_ 2277634050 EPB_EpbActivated 3;
BA_ "RoutingFactor" SG_ 2277634050 EPB_EpbActivated 3;
BA_ "Version" SG_ 2277634050 EPB_EpbActivated "22.10.20";
BA_ "GenMsgCycleTime" BO_ 1874 0;
BA_ "GenMsgCycleTimeFast" BO_ 1874 0;
BA_ "GenMsgNrOfRepetition" BO_ 1874 0;
BA_ "DiagRequest" BO_ 1874 1;
BA_ "GenMsgILSupport" BO_ 1874 0;
BA_ "TpMessage" BO_ 1874 1;
BA_ "TpTxIndex" BO_ 1874 121;
BA_ "Description" SG_ 1874 GST_DLBCU_Byte0 "TP Index : 121";
BA_ "UsrSigPurpose" SG_ 1874 GST_DLBCU_Byte0 3;
BA_ "UserSigValidity" SG_ 1874 GST_DLBCU_Byte0 0;
BA_REL_ "GenSigTimeoutTime" BU_SG_REL_ GW_DLBCU SG_ 1874 GST_DLBCU_Byte0 0;
BA_ "NetworkRequest" SG_ 1874 GST_DLBCU_Byte0 0;
BA_ "NetworkRequestHoldingTime" SG_ 1874 GST_DLBCU_Byte0 5000;
BA_ "Version" SG_ 1874 GST_DLBCU_Byte0 "21.02.04";
BA_ "Description" SG_ 1874 GST_DLBCU_Byte2 "TP Index : 121";
BA_ "UsrSigPurpose" SG_ 1874 GST_DLBCU_Byte2 3;
BA_ "UserSigValidity" SG_ 1874 GST_DLBCU_Byte2 0;
BA_REL_ "GenSigTimeoutTime" BU_SG_REL_ GW_DLBCU SG_ 1874 GST_DLBCU_Byte2 0;
BA_ "NetworkRequest" SG_ 1874 GST_DLBCU_Byte2 0;
BA_ "NetworkRequestHoldingTime" SG_ 1874 GST_DLBCU_Byte2 5000;
BA_ "Version" SG_ 1874 GST_DLBCU_Byte2 "21.02.04";
BA_ "Description" SG_ 1874 GST_DLBCU_Byte3 "TP Index : 121";
BA_ "UsrSigPurpose" SG_ 1874 GST_DLBCU_Byte3 3;
BA_ "UserSigValidity" SG_ 1874 GST_DLBCU_Byte3 0;
BA_REL_ "GenSigTimeoutTime" BU_SG_REL_ GW_DLBCU SG_ 1874 GST_DLBCU_Byte3 0;
BA_ "NetworkRequest" SG_ 1874 GST_DLBCU_Byte3 0;
BA_ "NetworkRequestHoldingTime" SG_ 1874 GST_DLBCU_Byte3 5000;
BA_ "Version" SG_ 1874 GST_DLBCU_Byte3 "21.02.04";
BA_ "Description" SG_ 1874 GST_DLBCU_Byte4 "TP Index : 121";
BA_ "UsrSigPurpose" SG_ 1874 GST_DLBCU_Byte4 3;
BA_ "UserSigValidity" SG_ 1874 GST_DLBCU_Byte4 0;
BA_REL_ "GenSigTimeoutTime" BU_SG_REL_ GW_DLBCU SG_ 1874 GST_DLBCU_Byte4 0;
BA_ "NetworkRequest" SG_ 1874 GST_DLBCU_Byte4 0;
BA_ "NetworkRequestHoldingTime" SG_ 1874 GST_DLBCU_Byte4 5000;
BA_ "Version" SG_ 1874 GST_DLBCU_Byte4 "21.02.04";
BA_ "Description" SG_ 1874 GST_DLBCU_Byte5 "TP Index : 121";
BA_ "UsrSigPurpose" SG_ 1874 GST_DLBCU_Byte5 3;
BA_ "UserSigValidity" SG_ 1874 GST_DLBCU_Byte5 0;
BA_REL_ "GenSigTimeoutTime" BU_SG_REL_ GW_DLBCU SG_ 1874 GST_DLBCU_Byte5 0;
BA_ "NetworkRequest" SG_ 1874 GST_DLBCU_Byte5 0;
BA_ "NetworkRequestHoldingTime" SG_ 1874 GST_DLBCU_Byte5 5000;
BA_ "Version" SG_ 1874 GST_DLBCU_Byte5 "21.02.04";
BA_ "Description" SG_ 1874 GST_DLBCU_Byte6 "TP Index : 121";
BA_ "UsrSigPurpose" SG_ 1874 GST_DLBCU_Byte6 3;
BA_ "UserSigValidity" SG_ 1874 GST_DLBCU_Byte6 0;
BA_REL_ "GenSigTimeoutTime" BU_SG_REL_ GW_DLBCU SG_ 1874 GST_DLBCU_Byte6 0;
BA_ "NetworkRequest" SG_ 1874 GST_DLBCU_Byte6 0;
BA_ "NetworkRequestHoldingTime" SG_ 1874 GST_DLBCU_Byte6 5000;
BA_ "Version" SG_ 1874 GST_DLBCU_Byte6 "21.02.04";
BA_ "Description" SG_ 1874 GST_DLBCU_Byte7 "TP Index : 121";
BA_ "UsrSigPurpose" SG_ 1874 GST_DLBCU_Byte7 3;
BA_ "UserSigValidity" SG_ 1874 GST_DLBCU_Byte7 0;
BA_REL_ "GenSigTimeoutTime" BU_SG_REL_ GW_DLBCU SG_ 1874 GST_DLBCU_Byte7 0;
BA_ "NetworkRequest" SG_ 1874 GST_DLBCU_Byte7 0;
BA_ "NetworkRequestHoldingTime" SG_ 1874 GST_DLBCU_Byte7 5000;
BA_ "Version" SG_ 1874 GST_DLBCU_Byte7 "21.02.04";
BA_ "Description" SG_ 1874 GST_DLBCU_Byte1 "TP Index : 121";
BA_ "UsrSigPurpose" SG_ 1874 GST_DLBCU_Byte1 3;
BA_ "UserSigValidity" SG_ 1874 GST_DLBCU_Byte1 0;
BA_REL_ "GenSigTimeoutTime" BU_SG_REL_ GW_DLBCU SG_ 1874 GST_DLBCU_Byte1 0;
BA_ "NetworkRequest" SG_ 1874 GST_DLBCU_Byte1 0;
BA_ "NetworkRequestHoldingTime" SG_ 1874 GST_DLBCU_Byte1 5000;
BA_ "Version" SG_ 1874 GST_DLBCU_Byte1 "21.02.04";
BA_ "GenMsgCycleTime" BO_ 1873 0;
BA_ "GenMsgCycleTimeFast" BO_ 1873 0;
BA_ "GenMsgNrOfRepetition" BO_ 1873 0;
BA_ "DiagRequest" BO_ 1873 1;
BA_ "GenMsgILSupport" BO_ 1873 0;
BA_ "TpMessage" BO_ 1873 1;
BA_ "TpTxIndex" BO_ 1873 122;
BA_ "Description" SG_ 1873 GST_DPSS_Byte0 "TP Index : 122";
BA_ "UsrSigPurpose" SG_ 1873 GST_DPSS_Byte0 3;
BA_ "UserSigValidity" SG_ 1873 GST_DPSS_Byte0 0;
BA_REL_ "GenSigTimeoutTime" BU_SG_REL_ GW_DPSU SG_ 1873 GST_DPSS_Byte0 0;
BA_ "NetworkRequest" SG_ 1873 GST_DPSS_Byte0 0;
BA_ "NetworkRequestHoldingTime" SG_ 1873 GST_DPSS_Byte0 5000;
BA_ "Version" SG_ 1873 GST_DPSS_Byte0 "21.02.04";
BA_ "Description" SG_ 1873 GST_DPSS_Byte2 "TP Index : 122";
BA_ "UsrSigPurpose" SG_ 1873 GST_DPSS_Byte2 3;
BA_ "UserSigValidity" SG_ 1873 GST_DPSS_Byte2 0;
BA_REL_ "GenSigTimeoutTime" BU_SG_REL_ GW_DPSU SG_ 1873 GST_DPSS_Byte2 0;
BA_ "NetworkRequest" SG_ 1873 GST_DPSS_Byte2 0;
BA_ "NetworkRequestHoldingTime" SG_ 1873 GST_DPSS_Byte2 5000;
BA_ "Version" SG_ 1873 GST_DPSS_Byte2 "21.02.04";
BA_ "Description" SG_ 1873 GST_DPSS_Byte3 "TP Index : 122";
BA_ "UsrSigPurpose" SG_ 1873 GST_DPSS_Byte3 3;
BA_ "UserSigValidity" SG_ 1873 GST_DPSS_Byte3 0;
BA_REL_ "GenSigTimeoutTime" BU_SG_REL_ GW_DPSU SG_ 1873 GST_DPSS_Byte3 0;
BA_ "NetworkRequest" SG_ 1873 GST_DPSS_Byte3 0;
BA_ "NetworkRequestHoldingTime" SG_ 1873 GST_DPSS_Byte3 5000;
BA_ "Version" SG_ 1873 GST_DPSS_Byte3 "21.02.04";
BA_ "Description" SG_ 1873 GST_DPSS_Byte4 "TP Index : 122";
BA_ "UsrSigPurpose" SG_ 1873 GST_DPSS_Byte4 3;
BA_ "UserSigValidity" SG_ 1873 GST_DPSS_Byte4 0;
BA_REL_ "GenSigTimeoutTime" BU_SG_REL_ GW_DPSU SG_ 1873 GST_DPSS_Byte4 0;
BA_ "NetworkRequest" SG_ 1873 GST_DPSS_Byte4 0;
BA_ "NetworkRequestHoldingTime" SG_ 1873 GST_DPSS_Byte4 5000;
BA_ "Version" SG_ 1873 GST_DPSS_Byte4 "21.02.04";
BA_ "Description" SG_ 1873 GST_DPSS_Byte5 "TP Index : 122";
BA_ "UsrSigPurpose" SG_ 1873 GST_DPSS_Byte5 3;
BA_ "UserSigValidity" SG_ 1873 GST_DPSS_Byte5 0;
BA_REL_ "GenSigTimeoutTime" BU_SG_REL_ GW_DPSU SG_ 1873 GST_DPSS_Byte5 0;
BA_ "NetworkRequest" SG_ 1873 GST_DPSS_Byte5 0;
BA_ "NetworkRequestHoldingTime" SG_ 1873 GST_DPSS_Byte5 5000;
BA_ "Version" SG_ 1873 GST_DPSS_Byte5 "21.02.04";
BA_ "Description" SG_ 1873 GST_DPSS_Byte6 "TP Index : 122";
BA_ "UsrSigPurpose" SG_ 1873 GST_DPSS_Byte6 3;
BA_ "UserSigValidity" SG_ 1873 GST_DPSS_Byte6 0;
BA_REL_ "GenSigTimeoutTime" BU_SG_REL_ GW_DPSU SG_ 1873 GST_DPSS_Byte6 0;
BA_ "NetworkRequest" SG_ 1873 GST_DPSS_Byte6 0;
BA_ "NetworkRequestHoldingTime" SG_ 1873 GST_DPSS_Byte6 5000;
BA_ "Version" SG_ 1873 GST_DPSS_Byte6 "21.02.04";
BA_ "Description" SG_ 1873 GST_DPSS_Byte7 "TP Index : 122";
BA_ "UsrSigPurpose" SG_ 1873 GST_DPSS_Byte7 3;
BA_ "UserSigValidity" SG_ 1873 GST_DPSS_Byte7 0;
BA_REL_ "GenSigTimeoutTime" BU_SG_REL_ GW_DPSU SG_ 1873 GST_DPSS_Byte7 0;
BA_ "NetworkRequest" SG_ 1873 GST_DPSS_Byte7 0;
BA_ "NetworkRequestHoldingTime" SG_ 1873 GST_DPSS_Byte7 5000;
BA_ "Version" SG_ 1873 GST_DPSS_Byte7 "21.02.04";
BA_ "Description" SG_ 1873 GST_DPSS_Byte1 "TP Index : 122";
BA_ "UsrSigPurpose" SG_ 1873 GST_DPSS_Byte1 3;
BA_ "UserSigValidity" SG_ 1873 GST_DPSS_Byte1 0;
BA_REL_ "GenSigTimeoutTime" BU_SG_REL_ GW_DPSU SG_ 1873 GST_DPSS_Byte1 0;
BA_ "NetworkRequest" SG_ 1873 GST_DPSS_Byte1 0;
BA_ "NetworkRequestHoldingTime" SG_ 1873 GST_DPSS_Byte1 5000;
BA_ "Version" SG_ 1873 GST_DPSS_Byte1 "21.02.04";
BA_ "GenMsgCycleTime" BO_ 1907 0;
BA_ "GenMsgCycleTimeFast" BO_ 1907 0;
BA_ "GenMsgNrOfRepetition" BO_ 1907 0;
BA_ "DiagRequest" BO_ 1907 1;
BA_ "GenMsgILSupport" BO_ 1907 0;
BA_ "TpMessage" BO_ 1907 1;
BA_ "TpTxIndex" BO_ 1907 158;
BA_ "Description" SG_ 1907 GST_RARS_Byte0 "TP Index : 158";
BA_ "UsrSigPurpose" SG_ 1907 GST_RARS_Byte0 3;
BA_ "UserSigValidity" SG_ 1907 GST_RARS_Byte0 0;
BA_REL_ "GenSigTimeoutTime" BU_SG_REL_ ARS SG_ 1907 GST_RARS_Byte0 0;
BA_ "NetworkRequest" SG_ 1907 GST_RARS_Byte0 0;
BA_ "NetworkRequestHoldingTime" SG_ 1907 GST_RARS_Byte0 5000;
BA_ "Version" SG_ 1907 GST_RARS_Byte0 "21.02.04";
BA_ "Description" SG_ 1907 GST_RARS_Byte2 "TP Index : 158";
BA_ "UsrSigPurpose" SG_ 1907 GST_RARS_Byte2 3;
BA_ "UserSigValidity" SG_ 1907 GST_RARS_Byte2 0;
BA_REL_ "GenSigTimeoutTime" BU_SG_REL_ ARS SG_ 1907 GST_RARS_Byte2 0;
BA_ "NetworkRequest" SG_ 1907 GST_RARS_Byte2 0;
BA_ "NetworkRequestHoldingTime" SG_ 1907 GST_RARS_Byte2 5000;
BA_ "Version" SG_ 1907 GST_RARS_Byte2 "21.02.04";
BA_ "Description" SG_ 1907 GST_RARS_Byte3 "TP Index : 158";
BA_ "UsrSigPurpose" SG_ 1907 GST_RARS_Byte3 3;
BA_ "UserSigValidity" SG_ 1907 GST_RARS_Byte3 0;
BA_REL_ "GenSigTimeoutTime" BU_SG_REL_ ARS SG_ 1907 GST_RARS_Byte3 0;
BA_ "NetworkRequest" SG_ 1907 GST_RARS_Byte3 0;
BA_ "NetworkRequestHoldingTime" SG_ 1907 GST_RARS_Byte3 5000;
BA_ "Version" SG_ 1907 GST_RARS_Byte3 "21.02.04";
BA_ "Description" SG_ 1907 GST_RARS_Byte4 "TP Index : 158";
BA_ "UsrSigPurpose" SG_ 1907 GST_RARS_Byte4 3;
BA_ "UserSigValidity" SG_ 1907 GST_RARS_Byte4 0;
BA_REL_ "GenSigTimeoutTime" BU_SG_REL_ ARS SG_ 1907 GST_RARS_Byte4 0;
BA_ "NetworkRequest" SG_ 1907 GST_RARS_Byte4 0;
BA_ "NetworkRequestHoldingTime" SG_ 1907 GST_RARS_Byte4 5000;
BA_ "Version" SG_ 1907 GST_RARS_Byte4 "21.02.04";
BA_ "Description" SG_ 1907 GST_RARS_Byte5 "TP Index : 158";
BA_ "UsrSigPurpose" SG_ 1907 GST_RARS_Byte5 3;
BA_ "UserSigValidity" SG_ 1907 GST_RARS_Byte5 0;
BA_REL_ "GenSigTimeoutTime" BU_SG_REL_ ARS SG_ 1907 GST_RARS_Byte5 0;
BA_ "NetworkRequest" SG_ 1907 GST_RARS_Byte5 0;
BA_ "NetworkRequestHoldingTime" SG_ 1907 GST_RARS_Byte5 5000;
BA_ "Version" SG_ 1907 GST_RARS_Byte5 "21.02.04";
BA_ "Description" SG_ 1907 GST_RARS_Byte6 "TP Index : 158";
BA_ "UsrSigPurpose" SG_ 1907 GST_RARS_Byte6 3;
BA_ "UserSigValidity" SG_ 1907 GST_RARS_Byte6 0;
BA_REL_ "GenSigTimeoutTime" BU_SG_REL_ ARS SG_ 1907 GST_RARS_Byte6 0;
BA_ "NetworkRequest" SG_ 1907 GST_RARS_Byte6 0;
BA_ "NetworkRequestHoldingTime" SG_ 1907 GST_RARS_Byte6 5000;
BA_ "Version" SG_ 1907 GST_RARS_Byte6 "21.02.04";
BA_ "Description" SG_ 1907 GST_RARS_Byte7 "TP Index : 158";
BA_ "UsrSigPurpose" SG_ 1907 GST_RARS_Byte7 3;
BA_ "UserSigValidity" SG_ 1907 GST_RARS_Byte7 0;
BA_REL_ "GenSigTimeoutTime" BU_SG_REL_ ARS SG_ 1907 GST_RARS_Byte7 0;
BA_ "NetworkRequest" SG_ 1907 GST_RARS_Byte7 0;
BA_ "NetworkRequestHoldingTime" SG_ 1907 GST_RARS_Byte7 5000;
BA_ "Version" SG_ 1907 GST_RARS_Byte7 "21.02.04";
BA_ "Description" SG_ 1907 GST_RARS_Byte1 "TP Index : 158";
BA_ "UsrSigPurpose" SG_ 1907 GST_RARS_Byte1 3;
BA_ "UserSigValidity" SG_ 1907 GST_RARS_Byte1 0;
BA_REL_ "GenSigTimeoutTime" BU_SG_REL_ ARS SG_ 1907 GST_RARS_Byte1 0;
BA_ "NetworkRequest" SG_ 1907 GST_RARS_Byte1 0;
BA_ "NetworkRequestHoldingTime" SG_ 1907 GST_RARS_Byte1 5000;
BA_ "Version" SG_ 1907 GST_RARS_Byte1 "21.02.04";
BA_ "GenMsgCycleTime" BO_ 1876 0;
BA_ "GenMsgCycleTimeFast" BO_ 1876 0;
BA_ "GenMsgNrOfRepetition" BO_ 1876 0;
BA_ "DiagRequest" BO_ 1876 1;
BA_ "GenMsgILSupport" BO_ 1876 0;
BA_ "TpMessage" BO_ 1876 1;
BA_ "TpTxIndex" BO_ 1876 263;
BA_ "Description" SG_ 1876 GST_RLMSS_MSS_RL_Byte0 "TP Index : 263";
BA_ "UsrSigPurpose" SG_ 1876 GST_RLMSS_MSS_RL_Byte0 3;
BA_ "UserSigValidity" SG_ 1876 GST_RLMSS_MSS_RL_Byte0 0;
BA_REL_ "GenSigTimeoutTime" BU_SG_REL_ GW_RLPSU SG_ 1876 GST_RLMSS_MSS_RL_Byte0 0;
BA_ "NetworkRequest" SG_ 1876 GST_RLMSS_MSS_RL_Byte0 0;
BA_ "NetworkRequestHoldingTime" SG_ 1876 GST_RLMSS_MSS_RL_Byte0 5000;
BA_ "Version" SG_ 1876 GST_RLMSS_MSS_RL_Byte0 "23.04.07";
BA_ "Description" SG_ 1876 GST_RLMSS_MSS_RL_Byte2 "TP Index : 263";
BA_ "UsrSigPurpose" SG_ 1876 GST_RLMSS_MSS_RL_Byte2 3;
BA_ "UserSigValidity" SG_ 1876 GST_RLMSS_MSS_RL_Byte2 0;
BA_REL_ "GenSigTimeoutTime" BU_SG_REL_ GW_RLPSU SG_ 1876 GST_RLMSS_MSS_RL_Byte2 0;
BA_ "NetworkRequest" SG_ 1876 GST_RLMSS_MSS_RL_Byte2 0;
BA_ "NetworkRequestHoldingTime" SG_ 1876 GST_RLMSS_MSS_RL_Byte2 5000;
BA_ "Version" SG_ 1876 GST_RLMSS_MSS_RL_Byte2 "23.04.07";
BA_ "Description" SG_ 1876 GST_RLMSS_MSS_RL_Byte3 "TP Index : 263";
BA_ "UsrSigPurpose" SG_ 1876 GST_RLMSS_MSS_RL_Byte3 3;
BA_ "UserSigValidity" SG_ 1876 GST_RLMSS_MSS_RL_Byte3 0;
BA_REL_ "GenSigTimeoutTime" BU_SG_REL_ GW_RLPSU SG_ 1876 GST_RLMSS_MSS_RL_Byte3 0;
BA_ "NetworkRequest" SG_ 1876 GST_RLMSS_MSS_RL_Byte3 0;
BA_ "NetworkRequestHoldingTime" SG_ 1876 GST_RLMSS_MSS_RL_Byte3 5000;
BA_ "Version" SG_ 1876 GST_RLMSS_MSS_RL_Byte3 "23.04.07";
BA_ "Description" SG_ 1876 GST_RLMSS_MSS_RL_Byte4 "TP Index : 263";
BA_ "UsrSigPurpose" SG_ 1876 GST_RLMSS_MSS_RL_Byte4 3;
BA_ "UserSigValidity" SG_ 1876 GST_RLMSS_MSS_RL_Byte4 0;
BA_REL_ "GenSigTimeoutTime" BU_SG_REL_ GW_RLPSU SG_ 1876 GST_RLMSS_MSS_RL_Byte4 0;
BA_ "NetworkRequest" SG_ 1876 GST_RLMSS_MSS_RL_Byte4 0;
BA_ "NetworkRequestHoldingTime" SG_ 1876 GST_RLMSS_MSS_RL_Byte4 5000;
BA_ "Version" SG_ 1876 GST_RLMSS_MSS_RL_Byte4 "23.04.07";
BA_ "Description" SG_ 1876 GST_RLMSS_MSS_RL_Byte5 "TP Index : 263";
BA_ "UsrSigPurpose" SG_ 1876 GST_RLMSS_MSS_RL_Byte5 3;
BA_ "UserSigValidity" SG_ 1876 GST_RLMSS_MSS_RL_Byte5 0;
BA_REL_ "GenSigTimeoutTime" BU_SG_REL_ GW_RLPSU SG_ 1876 GST_RLMSS_MSS_RL_Byte5 0;
BA_ "NetworkRequest" SG_ 1876 GST_RLMSS_MSS_RL_Byte5 0;
BA_ "NetworkRequestHoldingTime" SG_ 1876 GST_RLMSS_MSS_RL_Byte5 5000;
BA_ "Version" SG_ 1876 GST_RLMSS_MSS_RL_Byte5 "23.04.07";
BA_ "Description" SG_ 1876 GST_RLMSS_MSS_RL_Byte6 "TP Index : 263";
BA_ "UsrSigPurpose" SG_ 1876 GST_RLMSS_MSS_RL_Byte6 3;
BA_ "UserSigValidity" SG_ 1876 GST_RLMSS_MSS_RL_Byte6 0;
BA_REL_ "GenSigTimeoutTime" BU_SG_REL_ GW_RLPSU SG_ 1876 GST_RLMSS_MSS_RL_Byte6 0;
BA_ "NetworkRequest" SG_ 1876 GST_RLMSS_MSS_RL_Byte6 0;
BA_ "NetworkRequestHoldingTime" SG_ 1876 GST_RLMSS_MSS_RL_Byte6 5000;
BA_ "Version" SG_ 1876 GST_RLMSS_MSS_RL_Byte6 "23.04.07";
BA_ "Description" SG_ 1876 GST_RLMSS_MSS_RL_Byte7 "TP Index : 263";
BA_ "UsrSigPurpose" SG_ 1876 GST_RLMSS_MSS_RL_Byte7 3;
BA_ "UserSigValidity" SG_ 1876 GST_RLMSS_MSS_RL_Byte7 0;
BA_REL_ "GenSigTimeoutTime" BU_SG_REL_ GW_RLPSU SG_ 1876 GST_RLMSS_MSS_RL_Byte7 0;
BA_ "NetworkRequest" SG_ 1876 GST_RLMSS_MSS_RL_Byte7 0;
BA_ "NetworkRequestHoldingTime" SG_ 1876 GST_RLMSS_MSS_RL_Byte7 5000;
BA_ "Version" SG_ 1876 GST_RLMSS_MSS_RL_Byte7 "23.04.07";
BA_ "Description" SG_ 1876 GST_RLMSS_MSS_RL_Byte1 "TP Index : 263";
BA_ "UsrSigPurpose" SG_ 1876 GST_RLMSS_MSS_RL_Byte1 3;
BA_ "UserSigValidity" SG_ 1876 GST_RLMSS_MSS_RL_Byte1 0;
BA_REL_ "GenSigTimeoutTime" BU_SG_REL_ GW_RLPSU SG_ 1876 GST_RLMSS_MSS_RL_Byte1 0;
BA_ "NetworkRequest" SG_ 1876 GST_RLMSS_MSS_RL_Byte1 0;
BA_ "NetworkRequestHoldingTime" SG_ 1876 GST_RLMSS_MSS_RL_Byte1 5000;
BA_ "Version" SG_ 1876 GST_RLMSS_MSS_RL_Byte1 "23.04.07";
BA_ "GenMsgCycleTime" BO_ 1875 0;
BA_ "GenMsgCycleTimeFast" BO_ 1875 0;
BA_ "GenMsgNrOfRepetition" BO_ 1875 0;
BA_ "DiagRequest" BO_ 1875 1;
BA_ "GenMsgILSupport" BO_ 1875 0;
BA_ "TpMessage" BO_ 1875 1;
BA_ "TpTxIndex" BO_ 1875 262;
BA_ "Description" SG_ 1875 GST_RLMSU_MSU_RL_Byte0 "TP Index : 262";
BA_ "UsrSigPurpose" SG_ 1875 GST_RLMSU_MSU_RL_Byte0 3;
BA_ "UserSigValidity" SG_ 1875 GST_RLMSU_MSU_RL_Byte0 0;
BA_REL_ "GenSigTimeoutTime" BU_SG_REL_ GW_RLPSU SG_ 1875 GST_RLMSU_MSU_RL_Byte0 0;
BA_ "NetworkRequest" SG_ 1875 GST_RLMSU_MSU_RL_Byte0 0;
BA_ "NetworkRequestHoldingTime" SG_ 1875 GST_RLMSU_MSU_RL_Byte0 5000;
BA_ "Version" SG_ 1875 GST_RLMSU_MSU_RL_Byte0 "23.04.07";
BA_ "Description" SG_ 1875 GST_RLMSU_MSU_RL_Byte2 "TP Index : 262";
BA_ "UsrSigPurpose" SG_ 1875 GST_RLMSU_MSU_RL_Byte2 3;
BA_ "UserSigValidity" SG_ 1875 GST_RLMSU_MSU_RL_Byte2 0;
BA_REL_ "GenSigTimeoutTime" BU_SG_REL_ GW_RLPSU SG_ 1875 GST_RLMSU_MSU_RL_Byte2 0;
BA_ "NetworkRequest" SG_ 1875 GST_RLMSU_MSU_RL_Byte2 0;
BA_ "NetworkRequestHoldingTime" SG_ 1875 GST_RLMSU_MSU_RL_Byte2 5000;
BA_ "Version" SG_ 1875 GST_RLMSU_MSU_RL_Byte2 "23.04.07";
BA_ "Description" SG_ 1875 GST_RLMSU_MSU_RL_Byte3 "TP Index : 262";
BA_ "UsrSigPurpose" SG_ 1875 GST_RLMSU_MSU_RL_Byte3 3;
BA_ "UserSigValidity" SG_ 1875 GST_RLMSU_MSU_RL_Byte3 0;
BA_REL_ "GenSigTimeoutTime" BU_SG_REL_ GW_RLPSU SG_ 1875 GST_RLMSU_MSU_RL_Byte3 0;
BA_ "NetworkRequest" SG_ 1875 GST_RLMSU_MSU_RL_Byte3 0;
BA_ "NetworkRequestHoldingTime" SG_ 1875 GST_RLMSU_MSU_RL_Byte3 5000;
BA_ "Version" SG_ 1875 GST_RLMSU_MSU_RL_Byte3 "23.04.07";
BA_ "Description" SG_ 1875 GST_RLMSU_MSU_RL_Byte4 "TP Index : 262";
BA_ "UsrSigPurpose" SG_ 1875 GST_RLMSU_MSU_RL_Byte4 3;
BA_ "UserSigValidity" SG_ 1875 GST_RLMSU_MSU_RL_Byte4 0;
BA_REL_ "GenSigTimeoutTime" BU_SG_REL_ GW_RLPSU SG_ 1875 GST_RLMSU_MSU_RL_Byte4 0;
BA_ "NetworkRequest" SG_ 1875 GST_RLMSU_MSU_RL_Byte4 0;
BA_ "NetworkRequestHoldingTime" SG_ 1875 GST_RLMSU_MSU_RL_Byte4 5000;
BA_ "Version" SG_ 1875 GST_RLMSU_MSU_RL_Byte4 "23.04.07";
BA_ "Description" SG_ 1875 GST_RLMSU_MSU_RL_Byte5 "TP Index : 262";
BA_ "UsrSigPurpose" SG_ 1875 GST_RLMSU_MSU_RL_Byte5 3;
BA_ "UserSigValidity" SG_ 1875 GST_RLMSU_MSU_RL_Byte5 0;
BA_REL_ "GenSigTimeoutTime" BU_SG_REL_ GW_RLPSU SG_ 1875 GST_RLMSU_MSU_RL_Byte5 0;
BA_ "NetworkRequest" SG_ 1875 GST_RLMSU_MSU_RL_Byte5 0;
BA_ "NetworkRequestHoldingTime" SG_ 1875 GST_RLMSU_MSU_RL_Byte5 5000;
BA_ "Version" SG_ 1875 GST_RLMSU_MSU_RL_Byte5 "23.04.07";
BA_ "Description" SG_ 1875 GST_RLMSU_MSU_RL_Byte6 "TP Index : 262";
BA_ "UsrSigPurpose" SG_ 1875 GST_RLMSU_MSU_RL_Byte6 3;
BA_ "UserSigValidity" SG_ 1875 GST_RLMSU_MSU_RL_Byte6 0;
BA_REL_ "GenSigTimeoutTime" BU_SG_REL_ GW_RLPSU SG_ 1875 GST_RLMSU_MSU_RL_Byte6 0;
BA_ "NetworkRequest" SG_ 1875 GST_RLMSU_MSU_RL_Byte6 0;
BA_ "NetworkRequestHoldingTime" SG_ 1875 GST_RLMSU_MSU_RL_Byte6 5000;
BA_ "Version" SG_ 1875 GST_RLMSU_MSU_RL_Byte6 "23.04.07";
BA_ "Description" SG_ 1875 GST_RLMSU_MSU_RL_Byte7 "TP Index : 262";
BA_ "UsrSigPurpose" SG_ 1875 GST_RLMSU_MSU_RL_Byte7 3;
BA_ "UserSigValidity" SG_ 1875 GST_RLMSU_MSU_RL_Byte7 0;
BA_REL_ "GenSigTimeoutTime" BU_SG_REL_ GW_RLPSU SG_ 1875 GST_RLMSU_MSU_RL_Byte7 0;
BA_ "NetworkRequest" SG_ 1875 GST_RLMSU_MSU_RL_Byte7 0;
BA_ "NetworkRequestHoldingTime" SG_ 1875 GST_RLMSU_MSU_RL_Byte7 5000;
BA_ "Version" SG_ 1875 GST_RLMSU_MSU_RL_Byte7 "23.04.07";
BA_ "Description" SG_ 1875 GST_RLMSU_MSU_RL_Byte1 "TP Index : 262";
BA_ "UsrSigPurpose" SG_ 1875 GST_RLMSU_MSU_RL_Byte1 3;
BA_ "UserSigValidity" SG_ 1875 GST_RLMSU_MSU_RL_Byte1 0;
BA_REL_ "GenSigTimeoutTime" BU_SG_REL_ GW_RLPSU SG_ 1875 GST_RLMSU_MSU_RL_Byte1 0;
BA_ "NetworkRequest" SG_ 1875 GST_RLMSU_MSU_RL_Byte1 0;
BA_ "NetworkRequestHoldingTime" SG_ 1875 GST_RLMSU_MSU_RL_Byte1 5000;
BA_ "Version" SG_ 1875 GST_RLMSU_MSU_RL_Byte1 "23.04.07";
BA_ "GenMsgCycleTime" BO_ 1906 0;
BA_ "GenMsgCycleTimeFast" BO_ 1906 0;
BA_ "GenMsgNrOfRepetition" BO_ 1906 0;
BA_ "DiagRequest" BO_ 1906 1;
BA_ "GenMsgILSupport" BO_ 1906 0;
BA_ "TpMessage" BO_ 1906 1;
BA_ "TpTxIndex" BO_ 1906 261;
BA_ "Description" SG_ 1906 GST_RRMSS_MSS_RR_Byte0 "TP Index : 261";
BA_ "UsrSigPurpose" SG_ 1906 GST_RRMSS_MSS_RR_Byte0 3;
BA_ "UserSigValidity" SG_ 1906 GST_RRMSS_MSS_RR_Byte0 0;
BA_REL_ "GenSigTimeoutTime" BU_SG_REL_ GW_RRPSU SG_ 1906 GST_RRMSS_MSS_RR_Byte0 0;
BA_ "NetworkRequest" SG_ 1906 GST_RRMSS_MSS_RR_Byte0 0;
BA_ "NetworkRequestHoldingTime" SG_ 1906 GST_RRMSS_MSS_RR_Byte0 5000;
BA_ "Version" SG_ 1906 GST_RRMSS_MSS_RR_Byte0 "23.11.01";
BA_ "Description" SG_ 1906 GST_RRMSS_MSS_RR_Byte2 "TP Index : 261";
BA_ "UsrSigPurpose" SG_ 1906 GST_RRMSS_MSS_RR_Byte2 3;
BA_ "UserSigValidity" SG_ 1906 GST_RRMSS_MSS_RR_Byte2 0;
BA_REL_ "GenSigTimeoutTime" BU_SG_REL_ GW_RRPSU SG_ 1906 GST_RRMSS_MSS_RR_Byte2 0;
BA_ "NetworkRequest" SG_ 1906 GST_RRMSS_MSS_RR_Byte2 0;
BA_ "NetworkRequestHoldingTime" SG_ 1906 GST_RRMSS_MSS_RR_Byte2 5000;
BA_ "Version" SG_ 1906 GST_RRMSS_MSS_RR_Byte2 "23.11.01";
BA_ "Description" SG_ 1906 GST_RRMSS_MSS_RR_Byte3 "TP Index : 261";
BA_ "UsrSigPurpose" SG_ 1906 GST_RRMSS_MSS_RR_Byte3 3;
BA_ "UserSigValidity" SG_ 1906 GST_RRMSS_MSS_RR_Byte3 0;
BA_REL_ "GenSigTimeoutTime" BU_SG_REL_ GW_RRPSU SG_ 1906 GST_RRMSS_MSS_RR_Byte3 0;
BA_ "NetworkRequest" SG_ 1906 GST_RRMSS_MSS_RR_Byte3 0;
BA_ "NetworkRequestHoldingTime" SG_ 1906 GST_RRMSS_MSS_RR_Byte3 5000;
BA_ "Version" SG_ 1906 GST_RRMSS_MSS_RR_Byte3 "23.11.01";
BA_ "Description" SG_ 1906 GST_RRMSS_MSS_RR_Byte4 "TP Index : 261";
BA_ "UsrSigPurpose" SG_ 1906 GST_RRMSS_MSS_RR_Byte4 3;
BA_ "UserSigValidity" SG_ 1906 GST_RRMSS_MSS_RR_Byte4 0;
BA_REL_ "GenSigTimeoutTime" BU_SG_REL_ GW_RRPSU SG_ 1906 GST_RRMSS_MSS_RR_Byte4 0;
BA_ "NetworkRequest" SG_ 1906 GST_RRMSS_MSS_RR_Byte4 0;
BA_ "NetworkRequestHoldingTime" SG_ 1906 GST_RRMSS_MSS_RR_Byte4 5000;
BA_ "Version" SG_ 1906 GST_RRMSS_MSS_RR_Byte4 "23.11.01";
BA_ "Description" SG_ 1906 GST_RRMSS_MSS_RR_Byte5 "TP Index : 261";
BA_ "UsrSigPurpose" SG_ 1906 GST_RRMSS_MSS_RR_Byte5 3;
BA_ "UserSigValidity" SG_ 1906 GST_RRMSS_MSS_RR_Byte5 0;
BA_REL_ "GenSigTimeoutTime" BU_SG_REL_ GW_RRPSU SG_ 1906 GST_RRMSS_MSS_RR_Byte5 0;
BA_ "NetworkRequest" SG_ 1906 GST_RRMSS_MSS_RR_Byte5 0;
BA_ "NetworkRequestHoldingTime" SG_ 1906 GST_RRMSS_MSS_RR_Byte5 5000;
BA_ "Version" SG_ 1906 GST_RRMSS_MSS_RR_Byte5 "23.11.01";
BA_ "Description" SG_ 1906 GST_RRMSS_MSS_RR_Byte6 "TP Index : 261";
BA_ "UsrSigPurpose" SG_ 1906 GST_RRMSS_MSS_RR_Byte6 3;
BA_ "UserSigValidity" SG_ 1906 GST_RRMSS_MSS_RR_Byte6 0;
BA_REL_ "GenSigTimeoutTime" BU_SG_REL_ GW_RRPSU SG_ 1906 GST_RRMSS_MSS_RR_Byte6 0;
BA_ "NetworkRequest" SG_ 1906 GST_RRMSS_MSS_RR_Byte6 0;
BA_ "NetworkRequestHoldingTime" SG_ 1906 GST_RRMSS_MSS_RR_Byte6 5000;
BA_ "Version" SG_ 1906 GST_RRMSS_MSS_RR_Byte6 "23.11.01";
BA_ "Description" SG_ 1906 GST_RRMSS_MSS_RR_Byte7 "TP Index : 261";
BA_ "UsrSigPurpose" SG_ 1906 GST_RRMSS_MSS_RR_Byte7 3;
BA_ "UserSigValidity" SG_ 1906 GST_RRMSS_MSS_RR_Byte7 0;
BA_REL_ "GenSigTimeoutTime" BU_SG_REL_ GW_RRPSU SG_ 1906 GST_RRMSS_MSS_RR_Byte7 0;
BA_ "NetworkRequest" SG_ 1906 GST_RRMSS_MSS_RR_Byte7 0;
BA_ "NetworkRequestHoldingTime" SG_ 1906 GST_RRMSS_MSS_RR_Byte7 5000;
BA_ "Version" SG_ 1906 GST_RRMSS_MSS_RR_Byte7 "23.11.01";
BA_ "Description" SG_ 1906 GST_RRMSS_MSS_RR_Byte1 "TP Index : 261";
BA_ "UsrSigPurpose" SG_ 1906 GST_RRMSS_MSS_RR_Byte1 3;
BA_ "UserSigValidity" SG_ 1906 GST_RRMSS_MSS_RR_Byte1 0;
BA_REL_ "GenSigTimeoutTime" BU_SG_REL_ GW_RRPSU SG_ 1906 GST_RRMSS_MSS_RR_Byte1 0;
BA_ "NetworkRequest" SG_ 1906 GST_RRMSS_MSS_RR_Byte1 0;
BA_ "NetworkRequestHoldingTime" SG_ 1906 GST_RRMSS_MSS_RR_Byte1 5000;
BA_ "Version" SG_ 1906 GST_RRMSS_MSS_RR_Byte1 "23.11.01";
BA_ "GenMsgSendType" BO_ 2210462212 0;
BA_ "GenMsgCycleTime" BO_ 2210462212 50;
BA_ "GenMsgCycleTimeFast" BO_ 2210462212 0;
BA_ "GenMsgNrOfRepetition" BO_ 2210462212 0;
BA_ "VFrameFormat" BO_ 2210462212 1;
BA_ "Description" SG_ 2210462212 HCU_11sMaxSpdLimOperSta "110kph Max Speed Limitation Status for 11 passenger vehicle";
BA_ "UserSigValidity" SG_ 2210462212 HCU_11sMaxSpdLimOperSta 3;
BA_ "RoutingFactor" SG_ 2210462212 HCU_11sMaxSpdLimOperSta 5;
BA_ "Version" SG_ 2210462212 HCU_11sMaxSpdLimOperSta "23.09.04";
BA_ "GenMsgSendType" BO_ 881 0;
BA_ "GenMsgCycleTime" BO_ 881 1000;
BA_ "GenMsgCycleTimeFast" BO_ 881 0;
BA_ "GenMsgNrOfRepetition" BO_ 881 0;
BA_ "UserSigValidity" SG_ 881 HU_GNSS_UTC_year 1;
BA_REL_ "GenSigTimeoutTime" BU_SG_REL_ BLTN_CAM SG_ 881 HU_GNSS_UTC_year 5000;
BA_ "Version" SG_ 881 HU_GNSS_UTC_year "23.08.10";
BA_ "Description" SG_ 881 HU_GNSS_UTC_month "range : [1, 12]";
BA_ "UserSigValidity" SG_ 881 HU_GNSS_UTC_month 1;
BA_REL_ "GenSigTimeoutTime" BU_SG_REL_ BLTN_CAM SG_ 881 HU_GNSS_UTC_month 5000;
BA_ "Version" SG_ 881 HU_GNSS_UTC_month "22.07.05";
BA_ "Description" SG_ 881 HU_GNSS_UTC_day "range : [1, 31]";
BA_ "UserSigValidity" SG_ 881 HU_GNSS_UTC_day 1;
BA_REL_ "GenSigTimeoutTime" BU_SG_REL_ BLTN_CAM SG_ 881 HU_GNSS_UTC_day 5000;
BA_ "Version" SG_ 881 HU_GNSS_UTC_day "22.07.05";
BA_ "Description" SG_ 881 HU_GNSS_UTC_hour "range : [0, 23]";
BA_ "UserSigValidity" SG_ 881 HU_GNSS_UTC_hour 1;
BA_REL_ "GenSigTimeoutTime" BU_SG_REL_ BLTN_CAM SG_ 881 HU_GNSS_UTC_hour 5000;
BA_ "Version" SG_ 881 HU_GNSS_UTC_hour "22.07.05";
BA_ "Description" SG_ 881 HU_GNSS_UTC_min "range : [0,59]";
BA_ "UserSigValidity" SG_ 881 HU_GNSS_UTC_min 1;
BA_REL_ "GenSigTimeoutTime" BU_SG_REL_ BLTN_CAM SG_ 881 HU_GNSS_UTC_min 5000;
BA_ "Version" SG_ 881 HU_GNSS_UTC_min "22.07.05";
BA_ "Description" SG_ 881 HU_GNSS_UTC_sec "ragne : [0, 60]  /  60 only for the leap second";
BA_ "UserSigValidity" SG_ 881 HU_GNSS_UTC_sec 1;
BA_REL_ "GenSigTimeoutTime" BU_SG_REL_ BLTN_CAM SG_ 881 HU_GNSS_UTC_sec 5000;
BA_ "Version" SG_ 881 HU_GNSS_UTC_sec "22.07.05";
BA_ "Description" SG_ 881 HU_GNSS_UTC_offset "GPS = UTC + offset";
BA_ "UserSigValidity" SG_ 881 HU_GNSS_UTC_offset 1;
BA_REL_ "GenSigTimeoutTime" BU_SG_REL_ BLTN_CAM SG_ 881 HU_GNSS_UTC_offset 5000;
BA_ "Version" SG_ 881 HU_GNSS_UTC_offset "22.07.05";
BA_ "GenMsgSendType" BO_ 883 0;
BA_ "GenMsgCycleTime" BO_ 883 1000;
BA_ "GenMsgCycleTimeFast" BO_ 883 0;
BA_ "GenMsgNrOfRepetition" BO_ 883 0;
BA_ "Description" SG_ 883 HU_GNSS_DGPS_age "whed using DGPS, (DGPS time - current time.)";
BA_ "UserSigValidity" SG_ 883 HU_GNSS_DGPS_age 1;
BA_ "Version" SG_ 883 HU_GNSS_DGPS_age "22.07.05";
BA_ "UserSigValidity" SG_ 883 HU_GNSS_TimeSource 1;
BA_ "Version" SG_ 883 HU_GNSS_TimeSource "22.07.05";
BA_ "UserSigValidity" SG_ 883 HU_GNSS_search 1;
BA_ "Version" SG_ 883 HU_GNSS_search "22.07.05";
BA_ "Description" SG_ 883 HU_GNSS_DST "DST setting";
BA_ "GenSigStartValue" SG_ 883 HU_GNSS_DST 3;
BA_ "UserSigValidity" SG_ 883 HU_GNSS_DST 1;
BA_REL_ "GenSigTimeoutTime" BU_SG_REL_ BLTN_CAM SG_ 883 HU_GNSS_DST 5000;
BA_ "Version" SG_ 883 HU_GNSS_DST "22.07.05";
BA_ "UserSigValidity" SG_ 883 HU_GNSS_SV_count 1;
BA_ "Version" SG_ 883 HU_GNSS_SV_count "22.07.05";
BA_ "Description" SG_ 883 HU_GNSS_TimezoneOffset "offset = [ value * factor(15) ] min.";
BA_ "UserSigValidity" SG_ 883 HU_GNSS_TimezoneOffset 1;
BA_REL_ "GenSigTimeoutTime" BU_SG_REL_ BLTN_CAM SG_ 883 HU_GNSS_TimezoneOffset 5000;
BA_ "Version" SG_ 883 HU_GNSS_TimezoneOffset "22.07.05";
BA_ "UserSigValidity" SG_ 883 HU_GNSS_Fix_status 1;
BA_ "Version" SG_ 883 HU_GNSS_Fix_status "22.07.05";
BA_ "GenMsgSendType" BO_ 884 0;
BA_ "GenMsgCycleTime" BO_ 884 1000;
BA_ "GenMsgCycleTimeFast" BO_ 884 0;
BA_ "GenMsgNrOfRepetition" BO_ 884 0;
BA_ "Description" SG_ 884 HU_MM_Latitude "range = -90*1,000,000 <= Value <=90*1,000,000

unit = degree*1,000,000";
BA_ "UserSigValidity" SG_ 884 HU_MM_Latitude 1;
BA_REL_ "GenSigTimeoutTime" BU_SG_REL_ BLTN_CAM SG_ 884 HU_MM_Latitude 5000;
BA_ "Version" SG_ 884 HU_MM_Latitude "22.07.05";
BA_ "Description" SG_ 884 HU_MM_Longitude "range = -180*1,000,000 <= Value <= 180*1,000,000

unit = degree*1,000,000";
BA_ "UserSigValidity" SG_ 884 HU_MM_Longitude 1;
BA_REL_ "GenSigTimeoutTime" BU_SG_REL_ BLTN_CAM SG_ 884 HU_MM_Longitude 5000;
BA_ "Version" SG_ 884 HU_MM_Longitude "22.07.05";
BA_ "GenMsgSendType" BO_ 721 0;
BA_ "GenMsgCycleTime" BO_ 721 100;
BA_ "GenMsgCycleTimeFast" BO_ 721 0;
BA_ "GenMsgNrOfRepetition" BO_ 721 0;
BA_ "Description" SG_ 721 HU_DR_Position_Status "0x1:Valid";
BA_ "UserSigValidity" SG_ 721 HU_DR_Position_Status 1;
BA_ "Version" SG_ 721 HU_DR_Position_Status "22.07.05";
BA_ "Description" SG_ 721 HU_DR_Altitude_Status "0x1=Valid";
BA_ "UserSigValidity" SG_ 721 HU_DR_Altitude_Status 1;
BA_ "Version" SG_ 721 HU_DR_Altitude_Status "22.07.05";
BA_ "Description" SG_ 721 HU_DR_Altitude "MSL";
BA_ "UserSigValidity" SG_ 721 HU_DR_Altitude 1;
BA_REL_ "GenSigTimeoutTime" BU_SG_REL_ BLTN_CAM SG_ 721 HU_DR_Altitude 1500;
BA_ "Version" SG_ 721 HU_DR_Altitude "22.07.05";
BA_ "Description" SG_ 721 HU_DR_Heading_Status "0x1=Valid";
BA_ "UserSigValidity" SG_ 721 HU_DR_Heading_Status 1;
BA_ "Version" SG_ 721 HU_DR_Heading_Status "22.07.05";
BA_ "Description" SG_ 721 HU_DR_Speed_Status "0x1=Valid";
BA_ "UserSigValidity" SG_ 721 HU_DR_Speed_Status 1;
BA_ "Version" SG_ 721 HU_DR_Speed_Status "22.07.05";
BA_ "Description" SG_ 721 HU_DR_DirectionSwitch_Sta "0x1=valid";
BA_ "UserSigValidity" SG_ 721 HU_DR_DirectionSwitch_Sta 1;
BA_ "Version" SG_ 721 HU_DR_DirectionSwitch_Sta "22.07.05";
BA_ "Description" SG_ 721 HU_DR_Direction "0x1=Backward";
BA_ "UserSigValidity" SG_ 721 HU_DR_Direction 1;
BA_ "Version" SG_ 721 HU_DR_Direction "22.07.05";
BA_ "Description" SG_ 721 HU_DR_GyroCalib_Sta "0x1=Calibrated";
BA_ "UserSigValidity" SG_ 721 HU_DR_GyroCalib_Sta 1;
BA_ "Version" SG_ 721 HU_DR_GyroCalib_Sta "22.07.05";
BA_ "Description" SG_ 721 HU_DR_TachoCalib_Sta "0x1=Calibrated";
BA_ "UserSigValidity" SG_ 721 HU_DR_TachoCalib_Sta 1;
BA_ "Version" SG_ 721 HU_DR_TachoCalib_Sta "22.07.05";
BA_ "Description" SG_ 721 HU_DR_Solution_Sta "0x1 : Dr is fully calibrated and DR position is valid";
BA_ "UserSigValidity" SG_ 721 HU_DR_Solution_Sta 1;
BA_ "Version" SG_ 721 HU_DR_Solution_Sta "22.07.05";
BA_ "Description" SG_ 721 HU_DR_GNSS_Fix_Age "0-254 = Time since last GNSS fix

255= No GNSS fix yet";
BA_ "UserSigValidity" SG_ 721 HU_DR_GNSS_Fix_Age 1;
BA_ "Version" SG_ 721 HU_DR_GNSS_Fix_Age "22.07.05";
BA_ "GenMsgSendType" BO_ 722 0;
BA_ "GenMsgCycleTime" BO_ 722 100;
BA_ "GenMsgCycleTimeFast" BO_ 722 0;
BA_ "GenMsgNrOfRepetition" BO_ 722 0;
BA_ "UserSigValidity" SG_ 722 HU_DR_Latitude 1;
BA_REL_ "GenSigTimeoutTime" BU_SG_REL_ BLTN_CAM SG_ 722 HU_DR_Latitude 1500;
BA_ "Version" SG_ 722 HU_DR_Latitude "22.07.05";
BA_ "UserSigValidity" SG_ 722 HU_DR_Longitude 1;
BA_REL_ "GenSigTimeoutTime" BU_SG_REL_ BLTN_CAM SG_ 722 HU_DR_Longitude 1500;
BA_ "Version" SG_ 722 HU_DR_Longitude "22.07.05";
BA_ "GenMsgSendType" BO_ 723 0;
BA_ "GenMsgCycleTime" BO_ 723 100;
BA_ "GenMsgCycleTimeFast" BO_ 723 0;
BA_ "GenMsgNrOfRepetition" BO_ 723 0;
BA_ "UserSigValidity" SG_ 723 HU_DR_Heading 1;
BA_REL_ "GenSigTimeoutTime" BU_SG_REL_ BLTN_CAM SG_ 723 HU_DR_Heading 1500;
BA_ "Version" SG_ 723 HU_DR_Heading "22.07.05";
BA_ "Description" SG_ 723 HU_DR_Speed "negative if the direction is backward.";
BA_ "UserSigValidity" SG_ 723 HU_DR_Speed 1;
BA_ "Version" SG_ 723 HU_DR_Speed "22.07.05";
BA_ "GenMsgSendType" BO_ 787 0;
BA_ "Description" SG_ 787 DPSU_DrvSlidePosition "DRIVER SEAT SLIDE POSITION (UNIT: mm, 1 Value ´ç 2mm)";
BA_ "GenSigSendType" SG_ 787 DPSU_DrvSlidePosition 4;
BA_ "UserSigValidity" SG_ 787 DPSU_DrvSlidePosition 0;
BA_REL_ "GenSigTimeoutTime" BU_SG_REL_ CGW_CCU SG_ 787 DPSU_DrvSlidePosition 1500;
BA_REL_ "GenSigTimeoutTime" BU_SG_REL_ GW_RLPSU SG_ 787 DPSU_DrvSlidePosition 1500;
BA_REL_ "GenSigTimeoutTime" BU_SG_REL_ GW_RRPSU SG_ 787 DPSU_DrvSlidePosition 1500;
BA_ "NetworkRequest" SG_ 787 DPSU_DrvSlidePosition 0;
BA_ "NetworkRequestHoldingTime" SG_ 787 DPSU_DrvSlidePosition 5000;
BA_ "Version" SG_ 787 DPSU_DrvSlidePosition "22.06.05";
BA_ "Description" SG_ 787 DPSU_DrvHeightPosition "DRIVER SEAT HEIGHT POSITION (UNIT: mm)";
BA_ "GenSigSendType" SG_ 787 DPSU_DrvHeightPosition 4;
BA_ "UserSigValidity" SG_ 787 DPSU_DrvHeightPosition 0;
BA_REL_ "GenSigTimeoutTime" BU_SG_REL_ CGW_CCU SG_ 787 DPSU_DrvHeightPosition 1500;
BA_REL_ "GenSigTimeoutTime" BU_SG_REL_ GW_RLPSU SG_ 787 DPSU_DrvHeightPosition 1500;
BA_REL_ "GenSigTimeoutTime" BU_SG_REL_ GW_RRPSU SG_ 787 DPSU_DrvHeightPosition 1500;
BA_ "NetworkRequest" SG_ 787 DPSU_DrvHeightPosition 0;
BA_ "NetworkRequestHoldingTime" SG_ 787 DPSU_DrvHeightPosition 5000;
BA_ "Version" SG_ 787 DPSU_DrvHeightPosition "22.02.05";
BA_ "Description" SG_ 787 DPSU_DrvReclinePosition "DRIVER SEAT RECLINE POSITION (UNIT: ¢ª)";
BA_ "GenSigSendType" SG_ 787 DPSU_DrvReclinePosition 4;
BA_ "UserSigValidity" SG_ 787 DPSU_DrvReclinePosition 0;
BA_REL_ "GenSigTimeoutTime" BU_SG_REL_ CGW_CCU SG_ 787 DPSU_DrvReclinePosition 1500;
BA_REL_ "GenSigTimeoutTime" BU_SG_REL_ GW_RLPSU SG_ 787 DPSU_DrvReclinePosition 1500;
BA_REL_ "GenSigTimeoutTime" BU_SG_REL_ GW_RRPSU SG_ 787 DPSU_DrvReclinePosition 1500;
BA_ "NetworkRequest" SG_ 787 DPSU_DrvReclinePosition 0;
BA_ "NetworkRequestHoldingTime" SG_ 787 DPSU_DrvReclinePosition 5000;
BA_ "Version" SG_ 787 DPSU_DrvReclinePosition "22.02.05";
BA_ "Description" SG_ 787 DPSU_DrvRelaxTiltPosition "DRIVER SEAT RELAX TILT POSITION (UNIT: ¢ª)";
BA_ "GenSigSendType" SG_ 787 DPSU_DrvRelaxTiltPosition 4;
BA_ "UserSigValidity" SG_ 787 DPSU_DrvRelaxTiltPosition 0;
BA_REL_ "GenSigTimeoutTime" BU_SG_REL_ CGW_CCU SG_ 787 DPSU_DrvRelaxTiltPosition 1500;
BA_REL_ "GenSigTimeoutTime" BU_SG_REL_ GW_RLPSU SG_ 787 DPSU_DrvRelaxTiltPosition 1500;
BA_REL_ "GenSigTimeoutTime" BU_SG_REL_ GW_RRPSU SG_ 787 DPSU_DrvRelaxTiltPosition 1500;
BA_ "NetworkRequest" SG_ 787 DPSU_DrvRelaxTiltPosition 0;
BA_ "NetworkRequestHoldingTime" SG_ 787 DPSU_DrvRelaxTiltPosition 5000;
BA_ "Version" SG_ 787 DPSU_DrvRelaxTiltPosition "22.02.05";
BA_ "GenMsgCycleTime" BO_ 1915 0;
BA_ "GenMsgCycleTimeFast" BO_ 1915 0;
BA_ "GenMsgNrOfRepetition" BO_ 1915 0;
BA_ "DiagResponse" BO_ 1915 1;
BA_ "GenMsgILSupport" BO_ 1915 0;
BA_ "TpMessage" BO_ 1915 1;
BA_ "TpTxIndex" BO_ 1915 158;
BA_ "Description" SG_ 1915 RARS_GST_Byte0 "TP Index : 158";
BA_ "UsrSigPurpose" SG_ 1915 RARS_GST_Byte0 4;
BA_ "UserSigValidity" SG_ 1915 RARS_GST_Byte0 0;
BA_REL_ "GenSigTimeoutTime" BU_SG_REL_ CGW_CCU SG_ 1915 RARS_GST_Byte0 0;
BA_ "NetworkRequest" SG_ 1915 RARS_GST_Byte0 0;
BA_ "NetworkRequestHoldingTime" SG_ 1915 RARS_GST_Byte0 5000;
BA_ "Version" SG_ 1915 RARS_GST_Byte0 "22.07.01";
BA_ "Description" SG_ 1915 RARS_GST_Byte2 "TP Index : 158";
BA_ "UsrSigPurpose" SG_ 1915 RARS_GST_Byte2 4;
BA_ "UserSigValidity" SG_ 1915 RARS_GST_Byte2 0;
BA_REL_ "GenSigTimeoutTime" BU_SG_REL_ CGW_CCU SG_ 1915 RARS_GST_Byte2 0;
BA_ "NetworkRequest" SG_ 1915 RARS_GST_Byte2 0;
BA_ "NetworkRequestHoldingTime" SG_ 1915 RARS_GST_Byte2 5000;
BA_ "Version" SG_ 1915 RARS_GST_Byte2 "22.07.01";
BA_ "Description" SG_ 1915 RARS_GST_Byte3 "TP Index : 158";
BA_ "UsrSigPurpose" SG_ 1915 RARS_GST_Byte3 4;
BA_ "UserSigValidity" SG_ 1915 RARS_GST_Byte3 0;
BA_REL_ "GenSigTimeoutTime" BU_SG_REL_ CGW_CCU SG_ 1915 RARS_GST_Byte3 0;
BA_ "NetworkRequest" SG_ 1915 RARS_GST_Byte3 0;
BA_ "NetworkRequestHoldingTime" SG_ 1915 RARS_GST_Byte3 5000;
BA_ "Version" SG_ 1915 RARS_GST_Byte3 "22.07.01";
BA_ "Description" SG_ 1915 RARS_GST_Byte4 "TP Index : 158";
BA_ "UsrSigPurpose" SG_ 1915 RARS_GST_Byte4 4;
BA_ "UserSigValidity" SG_ 1915 RARS_GST_Byte4 0;
BA_REL_ "GenSigTimeoutTime" BU_SG_REL_ CGW_CCU SG_ 1915 RARS_GST_Byte4 0;
BA_ "NetworkRequest" SG_ 1915 RARS_GST_Byte4 0;
BA_ "NetworkRequestHoldingTime" SG_ 1915 RARS_GST_Byte4 5000;
BA_ "Version" SG_ 1915 RARS_GST_Byte4 "22.07.01";
BA_ "Description" SG_ 1915 RARS_GST_Byte5 "TP Index : 158";
BA_ "UsrSigPurpose" SG_ 1915 RARS_GST_Byte5 4;
BA_ "UserSigValidity" SG_ 1915 RARS_GST_Byte5 0;
BA_REL_ "GenSigTimeoutTime" BU_SG_REL_ CGW_CCU SG_ 1915 RARS_GST_Byte5 0;
BA_ "NetworkRequest" SG_ 1915 RARS_GST_Byte5 0;
BA_ "NetworkRequestHoldingTime" SG_ 1915 RARS_GST_Byte5 5000;
BA_ "Version" SG_ 1915 RARS_GST_Byte5 "22.07.01";
BA_ "Description" SG_ 1915 RARS_GST_Byte6 "TP Index : 158";
BA_ "UsrSigPurpose" SG_ 1915 RARS_GST_Byte6 4;
BA_ "UserSigValidity" SG_ 1915 RARS_GST_Byte6 0;
BA_REL_ "GenSigTimeoutTime" BU_SG_REL_ CGW_CCU SG_ 1915 RARS_GST_Byte6 0;
BA_ "NetworkRequest" SG_ 1915 RARS_GST_Byte6 0;
BA_ "NetworkRequestHoldingTime" SG_ 1915 RARS_GST_Byte6 5000;
BA_ "Version" SG_ 1915 RARS_GST_Byte6 "22.07.01";
BA_ "Description" SG_ 1915 RARS_GST_Byte7 "TP Index : 158";
BA_ "UsrSigPurpose" SG_ 1915 RARS_GST_Byte7 4;
BA_ "UserSigValidity" SG_ 1915 RARS_GST_Byte7 0;
BA_REL_ "GenSigTimeoutTime" BU_SG_REL_ CGW_CCU SG_ 1915 RARS_GST_Byte7 0;
BA_ "NetworkRequest" SG_ 1915 RARS_GST_Byte7 0;
BA_ "NetworkRequestHoldingTime" SG_ 1915 RARS_GST_Byte7 5000;
BA_ "Version" SG_ 1915 RARS_GST_Byte7 "22.07.01";
BA_ "Description" SG_ 1915 RARS_GST_Byte1 "TP Index : 158";
BA_ "UsrSigPurpose" SG_ 1915 RARS_GST_Byte1 4;
BA_ "UserSigValidity" SG_ 1915 RARS_GST_Byte1 0;
BA_REL_ "GenSigTimeoutTime" BU_SG_REL_ CGW_CCU SG_ 1915 RARS_GST_Byte1 0;
BA_ "NetworkRequest" SG_ 1915 RARS_GST_Byte1 0;
BA_ "NetworkRequestHoldingTime" SG_ 1915 RARS_GST_Byte1 5000;
BA_ "Version" SG_ 1915 RARS_GST_Byte1 "22.07.01";
BA_ "GenMsgSendType" BO_ 791 0;
BA_ "Description" SG_ 791 RCM_Crc4Val "The data area for CRC calculation is based on the data length (DLC) of the message DB.

The CRC shall be calculated over the entire data block (excluding the CRC bytes) including the user data, alive counter and Data ID 

 

- CRC Polynomial (0x1D) , Initial Value : 0x00, XOR value : 0xFF, Data ID Mode : Both, Data ID : Message ID + 0xF800 

- The initial value is for CRC calculation and the message should be sent with the calculated result value. 

The mathematical expression to 8 bit CRC polynomial is given here. G(x) = x8 + x4 + x3 + x2 + 1";
BA_ "GenSigSendType" SG_ 791 RCM_Crc4Val 4;
BA_ "UserSigValidity" SG_ 791 RCM_Crc4Val 0;
BA_ "Version" SG_ 791 RCM_Crc4Val "22.05.03";
BA_ "Description" SG_ 791 RCM_AlvCnt4Val "For the first transmission request for a data element the counter shall be initialized with 0 and shall be incremented by 1

for every subsequent send request. When the counter reaches the maximum value(0xE), then it shall restart with 0 for the next send request";
BA_ "GenSigSendType" SG_ 791 RCM_AlvCnt4Val 4;
BA_ "UserSigValidity" SG_ 791 RCM_AlvCnt4Val 0;
BA_ "Version" SG_ 791 RCM_AlvCnt4Val "22.05.03";
BA_ "Description" SG_ 791 RCM_RR_SunroofOpnSta "Sunroof Glass Open Status";
BA_ "GenSigSendType" SG_ 791 RCM_RR_SunroofOpnSta 4;
BA_ "UserSigValidity" SG_ 791 RCM_RR_SunroofOpnSta 0;
BA_REL_ "GenSigTimeoutTime" BU_SG_REL_ CGW_CCU SG_ 791 RCM_RR_SunroofOpnSta 1500;
BA_ "NetworkRequest" SG_ 791 RCM_RR_SunroofOpnSta 0;
BA_ "NetworkRequestHoldingTime" SG_ 791 RCM_RR_SunroofOpnSta 5000;
BA_ "Version" SG_ 791 RCM_RR_SunroofOpnSta "22.02.05";
BA_ "Description" SG_ 791 RCM_RR_GlsOpSta "Sunroof Glass Operation Status";
BA_ "GenSigSendType" SG_ 791 RCM_RR_GlsOpSta 4;
BA_ "UserSigValidity" SG_ 791 RCM_RR_GlsOpSta 0;
BA_REL_ "GenSigTimeoutTime" BU_SG_REL_ CGW_CCU SG_ 791 RCM_RR_GlsOpSta 1500;
BA_ "Version" SG_ 791 RCM_RR_GlsOpSta "22.02.05";
BA_ "Description" SG_ 791 RCM_RR_GlsPosSta "Sunroof Glass Position Status";
BA_ "GenSigSendType" SG_ 791 RCM_RR_GlsPosSta 4;
BA_ "UserSigValidity" SG_ 791 RCM_RR_GlsPosSta 0;
BA_REL_ "GenSigTimeoutTime" BU_SG_REL_ CGW_CCU SG_ 791 RCM_RR_GlsPosSta 1500;
BA_ "Version" SG_ 791 RCM_RR_GlsPosSta "22.07.04";
BA_ "Description" SG_ 791 RCM_RR_GlsFltSta "Sunroof Glass Fault Status";
BA_ "GenSigSendType" SG_ 791 RCM_RR_GlsFltSta 4;
BA_ "GenSigStartValue" SG_ 791 RCM_RR_GlsFltSta 2;
BA_ "UserSigValidity" SG_ 791 RCM_RR_GlsFltSta 0;
BA_REL_ "GenSigTimeoutTime" BU_SG_REL_ CGW_CCU SG_ 791 RCM_RR_GlsFltSta 1500;
BA_ "Version" SG_ 791 RCM_RR_GlsFltSta "22.02.05";
BA_ "GenMsgSendType" BO_ 792 0;
BA_ "Description" SG_ 792 RCM_Crc5Val "The data area for CRC calculation is based on the data length (DLC) of the message DB.

The CRC shall be calculated over the entire data block (excluding the CRC bytes) including the user data, alive counter and Data ID 

 

- CRC Polynomial (0x1D) , Initial Value : 0x00, XOR value : 0xFF, Data ID Mode : Both, Data ID : Message ID + 0xF800 

- The initial value is for CRC calculation and the message should be sent with the calculated result value. 

The mathematical expression to 8 bit CRC polynomial is given here. G(x) = x8 + x4 + x3 + x2 + 1";
BA_ "GenSigSendType" SG_ 792 RCM_Crc5Val 4;
BA_ "UserSigValidity" SG_ 792 RCM_Crc5Val 0;
BA_ "Version" SG_ 792 RCM_Crc5Val "22.05.03";
BA_ "Description" SG_ 792 RCM_AlvCnt5Val "For the first transmission request for a data element the counter shall be initialized with 0 and shall be incremented by 1

for every subsequent send request. When the counter reaches the maximum value(0xE), then it shall restart with 0 for the next send request";
BA_ "GenSigSendType" SG_ 792 RCM_AlvCnt5Val 4;
BA_ "UserSigValidity" SG_ 792 RCM_AlvCnt5Val 0;
BA_ "Version" SG_ 792 RCM_AlvCnt5Val "22.05.03";
BA_ "Description" SG_ 792 RCM_RR_BldPosSta "Sunroof Blind Position Status";
BA_ "GenSigSendType" SG_ 792 RCM_RR_BldPosSta 4;
BA_ "UserSigValidity" SG_ 792 RCM_RR_BldPosSta 0;
BA_REL_ "GenSigTimeoutTime" BU_SG_REL_ CGW_CCU SG_ 792 RCM_RR_BldPosSta 1500;
BA_REL_ "GenSigTimeoutTime" BU_SG_REL_ SGU SG_ 792 RCM_RR_BldPosSta 1500;
BA_ "Version" SG_ 792 RCM_RR_BldPosSta "22.02.05";
BA_ "Description" SG_ 792 RCM_RR_BldFltSta "Sunroof Blind Fault Status";
BA_ "GenSigSendType" SG_ 792 RCM_RR_BldFltSta 4;
BA_ "GenSigStartValue" SG_ 792 RCM_RR_BldFltSta 2;
BA_ "UserSigValidity" SG_ 792 RCM_RR_BldFltSta 0;
BA_REL_ "GenSigTimeoutTime" BU_SG_REL_ CGW_CCU SG_ 792 RCM_RR_BldFltSta 1500;
BA_ "Version" SG_ 792 RCM_RR_BldFltSta "22.02.05";
BA_ "GenMsgCycleTime" BO_ 1884 0;
BA_ "GenMsgCycleTimeFast" BO_ 1884 0;
BA_ "GenMsgNrOfRepetition" BO_ 1884 0;
BA_ "DiagResponse" BO_ 1884 1;
BA_ "GenMsgILSupport" BO_ 1884 0;
BA_ "TpMessage" BO_ 1884 1;
BA_ "TpTxIndex" BO_ 1884 263;
BA_ "Description" SG_ 1884 RLMSS_MSS_RL_GST_Byte0 "TP Index : 263";
BA_ "UsrSigPurpose" SG_ 1884 RLMSS_MSS_RL_GST_Byte0 4;
BA_ "UserSigValidity" SG_ 1884 RLMSS_MSS_RL_GST_Byte0 0;
BA_REL_ "GenSigTimeoutTime" BU_SG_REL_ CGW_CCU SG_ 1884 RLMSS_MSS_RL_GST_Byte0 0;
BA_ "Version" SG_ 1884 RLMSS_MSS_RL_GST_Byte0 "23.04.07";
BA_ "Description" SG_ 1884 RLMSS_MSS_RL_GST_Byte2 "TP Index : 263";
BA_ "UsrSigPurpose" SG_ 1884 RLMSS_MSS_RL_GST_Byte2 4;
BA_ "UserSigValidity" SG_ 1884 RLMSS_MSS_RL_GST_Byte2 0;
BA_REL_ "GenSigTimeoutTime" BU_SG_REL_ CGW_CCU SG_ 1884 RLMSS_MSS_RL_GST_Byte2 0;
BA_ "Version" SG_ 1884 RLMSS_MSS_RL_GST_Byte2 "23.04.07";
BA_ "Description" SG_ 1884 RLMSS_MSS_RL_GST_Byte3 "TP Index : 263";
BA_ "UsrSigPurpose" SG_ 1884 RLMSS_MSS_RL_GST_Byte3 4;
BA_ "UserSigValidity" SG_ 1884 RLMSS_MSS_RL_GST_Byte3 0;
BA_REL_ "GenSigTimeoutTime" BU_SG_REL_ CGW_CCU SG_ 1884 RLMSS_MSS_RL_GST_Byte3 0;
BA_ "Version" SG_ 1884 RLMSS_MSS_RL_GST_Byte3 "23.04.07";
BA_ "Description" SG_ 1884 RLMSS_MSS_RL_GST_Byte4 "TP Index : 263";
BA_ "UsrSigPurpose" SG_ 1884 RLMSS_MSS_RL_GST_Byte4 4;
BA_ "UserSigValidity" SG_ 1884 RLMSS_MSS_RL_GST_Byte4 0;
BA_REL_ "GenSigTimeoutTime" BU_SG_REL_ CGW_CCU SG_ 1884 RLMSS_MSS_RL_GST_Byte4 0;
BA_ "Version" SG_ 1884 RLMSS_MSS_RL_GST_Byte4 "23.04.07";
BA_ "Description" SG_ 1884 RLMSS_MSS_RL_GST_Byte5 "TP Index : 263";
BA_ "UsrSigPurpose" SG_ 1884 RLMSS_MSS_RL_GST_Byte5 4;
BA_ "UserSigValidity" SG_ 1884 RLMSS_MSS_RL_GST_Byte5 0;
BA_REL_ "GenSigTimeoutTime" BU_SG_REL_ CGW_CCU SG_ 1884 RLMSS_MSS_RL_GST_Byte5 0;
BA_ "Version" SG_ 1884 RLMSS_MSS_RL_GST_Byte5 "23.04.07";
BA_ "Description" SG_ 1884 RLMSS_MSS_RL_GST_Byte6 "TP Index : 263";
BA_ "UsrSigPurpose" SG_ 1884 RLMSS_MSS_RL_GST_Byte6 4;
BA_ "UserSigValidity" SG_ 1884 RLMSS_MSS_RL_GST_Byte6 0;
BA_REL_ "GenSigTimeoutTime" BU_SG_REL_ CGW_CCU SG_ 1884 RLMSS_MSS_RL_GST_Byte6 0;
BA_ "Version" SG_ 1884 RLMSS_MSS_RL_GST_Byte6 "23.04.07";
BA_ "Description" SG_ 1884 RLMSS_MSS_RL_GST_Byte7 "TP Index : 263";
BA_ "UsrSigPurpose" SG_ 1884 RLMSS_MSS_RL_GST_Byte7 4;
BA_ "UserSigValidity" SG_ 1884 RLMSS_MSS_RL_GST_Byte7 0;
BA_REL_ "GenSigTimeoutTime" BU_SG_REL_ CGW_CCU SG_ 1884 RLMSS_MSS_RL_GST_Byte7 0;
BA_ "Version" SG_ 1884 RLMSS_MSS_RL_GST_Byte7 "23.04.07";
BA_ "Description" SG_ 1884 RLMSS_MSS_RL_GST_Byte1 "TP Index : 263";
BA_ "UsrSigPurpose" SG_ 1884 RLMSS_MSS_RL_GST_Byte1 4;
BA_ "UserSigValidity" SG_ 1884 RLMSS_MSS_RL_GST_Byte1 0;
BA_REL_ "GenSigTimeoutTime" BU_SG_REL_ CGW_CCU SG_ 1884 RLMSS_MSS_RL_GST_Byte1 0;
BA_ "Version" SG_ 1884 RLMSS_MSS_RL_GST_Byte1 "23.04.07";
BA_ "GenMsgCycleTime" BO_ 1883 0;
BA_ "GenMsgCycleTimeFast" BO_ 1883 0;
BA_ "GenMsgNrOfRepetition" BO_ 1883 0;
BA_ "DiagResponse" BO_ 1883 1;
BA_ "GenMsgILSupport" BO_ 1883 0;
BA_ "TpMessage" BO_ 1883 1;
BA_ "TpTxIndex" BO_ 1883 262;
BA_ "Description" SG_ 1883 RLMSU_MSU_RL_GST_Byte0 "TP Index : 262";
BA_ "UsrSigPurpose" SG_ 1883 RLMSU_MSU_RL_GST_Byte0 4;
BA_ "UserSigValidity" SG_ 1883 RLMSU_MSU_RL_GST_Byte0 0;
BA_REL_ "GenSigTimeoutTime" BU_SG_REL_ CGW_CCU SG_ 1883 RLMSU_MSU_RL_GST_Byte0 0;
BA_ "Version" SG_ 1883 RLMSU_MSU_RL_GST_Byte0 "23.04.07";
BA_ "Description" SG_ 1883 RLMSU_MSU_RL_GST_Byte2 "TP Index : 262";
BA_ "UsrSigPurpose" SG_ 1883 RLMSU_MSU_RL_GST_Byte2 4;
BA_ "UserSigValidity" SG_ 1883 RLMSU_MSU_RL_GST_Byte2 0;
BA_REL_ "GenSigTimeoutTime" BU_SG_REL_ CGW_CCU SG_ 1883 RLMSU_MSU_RL_GST_Byte2 0;
BA_ "Version" SG_ 1883 RLMSU_MSU_RL_GST_Byte2 "23.04.07";
BA_ "Description" SG_ 1883 RLMSU_MSU_RL_GST_Byte3 "TP Index : 262";
BA_ "UsrSigPurpose" SG_ 1883 RLMSU_MSU_RL_GST_Byte3 4;
BA_ "UserSigValidity" SG_ 1883 RLMSU_MSU_RL_GST_Byte3 0;
BA_REL_ "GenSigTimeoutTime" BU_SG_REL_ CGW_CCU SG_ 1883 RLMSU_MSU_RL_GST_Byte3 0;
BA_ "Version" SG_ 1883 RLMSU_MSU_RL_GST_Byte3 "23.04.07";
BA_ "Description" SG_ 1883 RLMSU_MSU_RL_GST_Byte4 "TP Index : 262";
BA_ "UsrSigPurpose" SG_ 1883 RLMSU_MSU_RL_GST_Byte4 4;
BA_ "UserSigValidity" SG_ 1883 RLMSU_MSU_RL_GST_Byte4 0;
BA_REL_ "GenSigTimeoutTime" BU_SG_REL_ CGW_CCU SG_ 1883 RLMSU_MSU_RL_GST_Byte4 0;
BA_ "Version" SG_ 1883 RLMSU_MSU_RL_GST_Byte4 "23.04.07";
BA_ "Description" SG_ 1883 RLMSU_MSU_RL_GST_Byte5 "TP Index : 262";
BA_ "UsrSigPurpose" SG_ 1883 RLMSU_MSU_RL_GST_Byte5 4;
BA_ "UserSigValidity" SG_ 1883 RLMSU_MSU_RL_GST_Byte5 0;
BA_REL_ "GenSigTimeoutTime" BU_SG_REL_ CGW_CCU SG_ 1883 RLMSU_MSU_RL_GST_Byte5 0;
BA_ "Version" SG_ 1883 RLMSU_MSU_RL_GST_Byte5 "23.04.07";
BA_ "Description" SG_ 1883 RLMSU_MSU_RL_GST_Byte6 "TP Index : 262";
BA_ "UsrSigPurpose" SG_ 1883 RLMSU_MSU_RL_GST_Byte6 4;
BA_ "UserSigValidity" SG_ 1883 RLMSU_MSU_RL_GST_Byte6 0;
BA_REL_ "GenSigTimeoutTime" BU_SG_REL_ CGW_CCU SG_ 1883 RLMSU_MSU_RL_GST_Byte6 0;
BA_ "Version" SG_ 1883 RLMSU_MSU_RL_GST_Byte6 "23.04.07";
BA_ "Description" SG_ 1883 RLMSU_MSU_RL_GST_Byte7 "TP Index : 262";
BA_ "UsrSigPurpose" SG_ 1883 RLMSU_MSU_RL_GST_Byte7 4;
BA_ "UserSigValidity" SG_ 1883 RLMSU_MSU_RL_GST_Byte7 0;
BA_REL_ "GenSigTimeoutTime" BU_SG_REL_ CGW_CCU SG_ 1883 RLMSU_MSU_RL_GST_Byte7 0;
BA_ "Version" SG_ 1883 RLMSU_MSU_RL_GST_Byte7 "23.04.07";
BA_ "Description" SG_ 1883 RLMSU_MSU_RL_GST_Byte1 "TP Index : 262";
BA_ "UsrSigPurpose" SG_ 1883 RLMSU_MSU_RL_GST_Byte1 4;
BA_ "UserSigValidity" SG_ 1883 RLMSU_MSU_RL_GST_Byte1 0;
BA_REL_ "GenSigTimeoutTime" BU_SG_REL_ CGW_CCU SG_ 1883 RLMSU_MSU_RL_GST_Byte1 0;
BA_ "Version" SG_ 1883 RLMSU_MSU_RL_GST_Byte1 "23.04.07";
BA_ "GenMsgCycleTime" BO_ 1850 0;
BA_ "GenMsgCycleTimeFast" BO_ 1850 0;
BA_ "GenMsgNrOfRepetition" BO_ 1850 0;
BA_ "DiagResponse" BO_ 1850 1;
BA_ "GenMsgILSupport" BO_ 1850 0;
BA_ "TpMessage" BO_ 1850 1;
BA_ "TpTxIndex" BO_ 1850 161;
BA_ "Description" SG_ 1850 RLPSU_PSU_RL_GST_Byte0 "TP Index : 161";
BA_ "UsrSigPurpose" SG_ 1850 RLPSU_PSU_RL_GST_Byte0 4;
BA_ "UserSigValidity" SG_ 1850 RLPSU_PSU_RL_GST_Byte0 0;
BA_REL_ "GenSigTimeoutTime" BU_SG_REL_ CGW_CCU SG_ 1850 RLPSU_PSU_RL_GST_Byte0 0;
BA_ "NetworkRequest" SG_ 1850 RLPSU_PSU_RL_GST_Byte0 0;
BA_ "NetworkRequestHoldingTime" SG_ 1850 RLPSU_PSU_RL_GST_Byte0 5000;
BA_ "Version" SG_ 1850 RLPSU_PSU_RL_GST_Byte0 "22.11.14";
BA_ "Description" SG_ 1850 RLPSU_PSU_RL_GST_Byte2 "TP Index : 161";
BA_ "UsrSigPurpose" SG_ 1850 RLPSU_PSU_RL_GST_Byte2 4;
BA_ "UserSigValidity" SG_ 1850 RLPSU_PSU_RL_GST_Byte2 0;
BA_REL_ "GenSigTimeoutTime" BU_SG_REL_ CGW_CCU SG_ 1850 RLPSU_PSU_RL_GST_Byte2 0;
BA_ "NetworkRequest" SG_ 1850 RLPSU_PSU_RL_GST_Byte2 0;
BA_ "NetworkRequestHoldingTime" SG_ 1850 RLPSU_PSU_RL_GST_Byte2 5000;
BA_ "Version" SG_ 1850 RLPSU_PSU_RL_GST_Byte2 "22.11.14";
BA_ "Description" SG_ 1850 RLPSU_PSU_RL_GST_Byte3 "TP Index : 161";
BA_ "UsrSigPurpose" SG_ 1850 RLPSU_PSU_RL_GST_Byte3 4;
BA_ "UserSigValidity" SG_ 1850 RLPSU_PSU_RL_GST_Byte3 0;
BA_REL_ "GenSigTimeoutTime" BU_SG_REL_ CGW_CCU SG_ 1850 RLPSU_PSU_RL_GST_Byte3 0;
BA_ "NetworkRequest" SG_ 1850 RLPSU_PSU_RL_GST_Byte3 0;
BA_ "NetworkRequestHoldingTime" SG_ 1850 RLPSU_PSU_RL_GST_Byte3 5000;
BA_ "Version" SG_ 1850 RLPSU_PSU_RL_GST_Byte3 "22.11.14";
BA_ "Description" SG_ 1850 RLPSU_PSU_RL_GST_Byte4 "TP Index : 161";
BA_ "UsrSigPurpose" SG_ 1850 RLPSU_PSU_RL_GST_Byte4 4;
BA_ "UserSigValidity" SG_ 1850 RLPSU_PSU_RL_GST_Byte4 0;
BA_REL_ "GenSigTimeoutTime" BU_SG_REL_ CGW_CCU SG_ 1850 RLPSU_PSU_RL_GST_Byte4 0;
BA_ "NetworkRequest" SG_ 1850 RLPSU_PSU_RL_GST_Byte4 0;
BA_ "NetworkRequestHoldingTime" SG_ 1850 RLPSU_PSU_RL_GST_Byte4 5000;
BA_ "Version" SG_ 1850 RLPSU_PSU_RL_GST_Byte4 "22.11.14";
BA_ "Description" SG_ 1850 RLPSU_PSU_RL_GST_Byte5 "TP Index : 161";
BA_ "UsrSigPurpose" SG_ 1850 RLPSU_PSU_RL_GST_Byte5 4;
BA_ "UserSigValidity" SG_ 1850 RLPSU_PSU_RL_GST_Byte5 0;
BA_REL_ "GenSigTimeoutTime" BU_SG_REL_ CGW_CCU SG_ 1850 RLPSU_PSU_RL_GST_Byte5 0;
BA_ "NetworkRequest" SG_ 1850 RLPSU_PSU_RL_GST_Byte5 0;
BA_ "NetworkRequestHoldingTime" SG_ 1850 RLPSU_PSU_RL_GST_Byte5 5000;
BA_ "Version" SG_ 1850 RLPSU_PSU_RL_GST_Byte5 "22.11.14";
BA_ "Description" SG_ 1850 RLPSU_PSU_RL_GST_Byte6 "TP Index : 161";
BA_ "UsrSigPurpose" SG_ 1850 RLPSU_PSU_RL_GST_Byte6 4;
BA_ "UserSigValidity" SG_ 1850 RLPSU_PSU_RL_GST_Byte6 0;
BA_REL_ "GenSigTimeoutTime" BU_SG_REL_ CGW_CCU SG_ 1850 RLPSU_PSU_RL_GST_Byte6 0;
BA_ "NetworkRequest" SG_ 1850 RLPSU_PSU_RL_GST_Byte6 0;
BA_ "NetworkRequestHoldingTime" SG_ 1850 RLPSU_PSU_RL_GST_Byte6 5000;
BA_ "Version" SG_ 1850 RLPSU_PSU_RL_GST_Byte6 "22.11.14";
BA_ "Description" SG_ 1850 RLPSU_PSU_RL_GST_Byte7 "TP Index : 161";
BA_ "UsrSigPurpose" SG_ 1850 RLPSU_PSU_RL_GST_Byte7 4;
BA_ "UserSigValidity" SG_ 1850 RLPSU_PSU_RL_GST_Byte7 0;
BA_REL_ "GenSigTimeoutTime" BU_SG_REL_ CGW_CCU SG_ 1850 RLPSU_PSU_RL_GST_Byte7 0;
BA_ "NetworkRequest" SG_ 1850 RLPSU_PSU_RL_GST_Byte7 0;
BA_ "NetworkRequestHoldingTime" SG_ 1850 RLPSU_PSU_RL_GST_Byte7 5000;
BA_ "Version" SG_ 1850 RLPSU_PSU_RL_GST_Byte7 "22.11.14";
BA_ "Description" SG_ 1850 RLPSU_PSU_RL_GST_Byte1 "TP Index : 161";
BA_ "UsrSigPurpose" SG_ 1850 RLPSU_PSU_RL_GST_Byte1 4;
BA_ "UserSigValidity" SG_ 1850 RLPSU_PSU_RL_GST_Byte1 0;
BA_REL_ "GenSigTimeoutTime" BU_SG_REL_ CGW_CCU SG_ 1850 RLPSU_PSU_RL_GST_Byte1 0;
BA_ "NetworkRequest" SG_ 1850 RLPSU_PSU_RL_GST_Byte1 0;
BA_ "NetworkRequestHoldingTime" SG_ 1850 RLPSU_PSU_RL_GST_Byte1 5000;
BA_ "Version" SG_ 1850 RLPSU_PSU_RL_GST_Byte1 "22.11.14";
BA_ "GenMsgCycleTime" BO_ 1914 0;
BA_ "GenMsgCycleTimeFast" BO_ 1914 0;
BA_ "GenMsgNrOfRepetition" BO_ 1914 0;
BA_ "DiagResponse" BO_ 1914 1;
BA_ "GenMsgILSupport" BO_ 1914 0;
BA_ "TpMessage" BO_ 1914 1;
BA_ "TpTxIndex" BO_ 1914 261;
BA_ "Description" SG_ 1914 RRMSS_MSS_RR_GST_Byte0 "TP Index : 261";
BA_ "UsrSigPurpose" SG_ 1914 RRMSS_MSS_RR_GST_Byte0 4;
BA_ "UserSigValidity" SG_ 1914 RRMSS_MSS_RR_GST_Byte0 0;
BA_REL_ "GenSigTimeoutTime" BU_SG_REL_ CGW_CCU SG_ 1914 RRMSS_MSS_RR_GST_Byte0 0;
BA_ "Version" SG_ 1914 RRMSS_MSS_RR_GST_Byte0 "23.11.01";
BA_ "Description" SG_ 1914 RRMSS_MSS_RR_GST_Byte2 "TP Index : 261";
BA_ "UsrSigPurpose" SG_ 1914 RRMSS_MSS_RR_GST_Byte2 4;
BA_ "UserSigValidity" SG_ 1914 RRMSS_MSS_RR_GST_Byte2 0;
BA_REL_ "GenSigTimeoutTime" BU_SG_REL_ CGW_CCU SG_ 1914 RRMSS_MSS_RR_GST_Byte2 0;
BA_ "Version" SG_ 1914 RRMSS_MSS_RR_GST_Byte2 "23.11.01";
BA_ "Description" SG_ 1914 RRMSS_MSS_RR_GST_Byte3 "TP Index : 261";
BA_ "UsrSigPurpose" SG_ 1914 RRMSS_MSS_RR_GST_Byte3 4;
BA_ "UserSigValidity" SG_ 1914 RRMSS_MSS_RR_GST_Byte3 0;
BA_REL_ "GenSigTimeoutTime" BU_SG_REL_ CGW_CCU SG_ 1914 RRMSS_MSS_RR_GST_Byte3 0;
BA_ "Version" SG_ 1914 RRMSS_MSS_RR_GST_Byte3 "23.11.01";
BA_ "Description" SG_ 1914 RRMSS_MSS_RR_GST_Byte4 "TP Index : 261";
BA_ "UsrSigPurpose" SG_ 1914 RRMSS_MSS_RR_GST_Byte4 4;
BA_ "UserSigValidity" SG_ 1914 RRMSS_MSS_RR_GST_Byte4 0;
BA_REL_ "GenSigTimeoutTime" BU_SG_REL_ CGW_CCU SG_ 1914 RRMSS_MSS_RR_GST_Byte4 0;
BA_ "Version" SG_ 1914 RRMSS_MSS_RR_GST_Byte4 "23.11.01";
BA_ "Description" SG_ 1914 RRMSS_MSS_RR_GST_Byte5 "TP Index : 261";
BA_ "UsrSigPurpose" SG_ 1914 RRMSS_MSS_RR_GST_Byte5 4;
BA_ "UserSigValidity" SG_ 1914 RRMSS_MSS_RR_GST_Byte5 0;
BA_REL_ "GenSigTimeoutTime" BU_SG_REL_ CGW_CCU SG_ 1914 RRMSS_MSS_RR_GST_Byte5 0;
BA_ "Version" SG_ 1914 RRMSS_MSS_RR_GST_Byte5 "23.11.01";
BA_ "Description" SG_ 1914 RRMSS_MSS_RR_GST_Byte6 "TP Index : 261";
BA_ "UsrSigPurpose" SG_ 1914 RRMSS_MSS_RR_GST_Byte6 4;
BA_ "UserSigValidity" SG_ 1914 RRMSS_MSS_RR_GST_Byte6 0;
BA_REL_ "GenSigTimeoutTime" BU_SG_REL_ CGW_CCU SG_ 1914 RRMSS_MSS_RR_GST_Byte6 0;
BA_ "Version" SG_ 1914 RRMSS_MSS_RR_GST_Byte6 "23.11.01";
BA_ "Description" SG_ 1914 RRMSS_MSS_RR_GST_Byte7 "TP Index : 261";
BA_ "UsrSigPurpose" SG_ 1914 RRMSS_MSS_RR_GST_Byte7 4;
BA_ "UserSigValidity" SG_ 1914 RRMSS_MSS_RR_GST_Byte7 0;
BA_REL_ "GenSigTimeoutTime" BU_SG_REL_ CGW_CCU SG_ 1914 RRMSS_MSS_RR_GST_Byte7 0;
BA_ "Version" SG_ 1914 RRMSS_MSS_RR_GST_Byte7 "23.11.01";
BA_ "Description" SG_ 1914 RRMSS_MSS_RR_GST_Byte1 "TP Index : 261";
BA_ "UsrSigPurpose" SG_ 1914 RRMSS_MSS_RR_GST_Byte1 4;
BA_ "UserSigValidity" SG_ 1914 RRMSS_MSS_RR_GST_Byte1 0;
BA_REL_ "GenSigTimeoutTime" BU_SG_REL_ CGW_CCU SG_ 1914 RRMSS_MSS_RR_GST_Byte1 0;
BA_ "Version" SG_ 1914 RRMSS_MSS_RR_GST_Byte1 "23.11.01";
BA_ "GenMsgCycleTime" BO_ 1849 0;
BA_ "GenMsgCycleTimeFast" BO_ 1849 0;
BA_ "GenMsgNrOfRepetition" BO_ 1849 0;
BA_ "DiagResponse" BO_ 1849 1;
BA_ "GenMsgILSupport" BO_ 1849 0;
BA_ "TpMessage" BO_ 1849 1;
BA_ "TpTxIndex" BO_ 1849 166;
BA_ "Description" SG_ 1849 RRPSU_PSU_RR_GST_Byte0 "TP Index : 166";
BA_ "UsrSigPurpose" SG_ 1849 RRPSU_PSU_RR_GST_Byte0 4;
BA_ "UserSigValidity" SG_ 1849 RRPSU_PSU_RR_GST_Byte0 0;
BA_REL_ "GenSigTimeoutTime" BU_SG_REL_ CGW_CCU SG_ 1849 RRPSU_PSU_RR_GST_Byte0 0;
BA_ "NetworkRequest" SG_ 1849 RRPSU_PSU_RR_GST_Byte0 0;
BA_ "NetworkRequestHoldingTime" SG_ 1849 RRPSU_PSU_RR_GST_Byte0 5000;
BA_ "Version" SG_ 1849 RRPSU_PSU_RR_GST_Byte0 "22.11.14";
BA_ "Description" SG_ 1849 RRPSU_PSU_RR_GST_Byte2 "TP Index : 166";
BA_ "UsrSigPurpose" SG_ 1849 RRPSU_PSU_RR_GST_Byte2 4;
BA_ "UserSigValidity" SG_ 1849 RRPSU_PSU_RR_GST_Byte2 0;
BA_REL_ "GenSigTimeoutTime" BU_SG_REL_ CGW_CCU SG_ 1849 RRPSU_PSU_RR_GST_Byte2 0;
BA_ "NetworkRequest" SG_ 1849 RRPSU_PSU_RR_GST_Byte2 0;
BA_ "NetworkRequestHoldingTime" SG_ 1849 RRPSU_PSU_RR_GST_Byte2 5000;
BA_ "Version" SG_ 1849 RRPSU_PSU_RR_GST_Byte2 "22.11.14";
BA_ "Description" SG_ 1849 RRPSU_PSU_RR_GST_Byte3 "TP Index : 166";
BA_ "UsrSigPurpose" SG_ 1849 RRPSU_PSU_RR_GST_Byte3 4;
BA_ "UserSigValidity" SG_ 1849 RRPSU_PSU_RR_GST_Byte3 0;
BA_REL_ "GenSigTimeoutTime" BU_SG_REL_ CGW_CCU SG_ 1849 RRPSU_PSU_RR_GST_Byte3 0;
BA_ "NetworkRequest" SG_ 1849 RRPSU_PSU_RR_GST_Byte3 0;
BA_ "NetworkRequestHoldingTime" SG_ 1849 RRPSU_PSU_RR_GST_Byte3 5000;
BA_ "Version" SG_ 1849 RRPSU_PSU_RR_GST_Byte3 "22.11.14";
BA_ "Description" SG_ 1849 RRPSU_PSU_RR_GST_Byte4 "TP Index : 166";
BA_ "UsrSigPurpose" SG_ 1849 RRPSU_PSU_RR_GST_Byte4 4;
BA_ "UserSigValidity" SG_ 1849 RRPSU_PSU_RR_GST_Byte4 0;
BA_REL_ "GenSigTimeoutTime" BU_SG_REL_ CGW_CCU SG_ 1849 RRPSU_PSU_RR_GST_Byte4 0;
BA_ "NetworkRequest" SG_ 1849 RRPSU_PSU_RR_GST_Byte4 0;
BA_ "NetworkRequestHoldingTime" SG_ 1849 RRPSU_PSU_RR_GST_Byte4 5000;
BA_ "Version" SG_ 1849 RRPSU_PSU_RR_GST_Byte4 "22.11.14";
BA_ "Description" SG_ 1849 RRPSU_PSU_RR_GST_Byte5 "TP Index : 166";
BA_ "UsrSigPurpose" SG_ 1849 RRPSU_PSU_RR_GST_Byte5 4;
BA_ "UserSigValidity" SG_ 1849 RRPSU_PSU_RR_GST_Byte5 0;
BA_REL_ "GenSigTimeoutTime" BU_SG_REL_ CGW_CCU SG_ 1849 RRPSU_PSU_RR_GST_Byte5 0;
BA_ "NetworkRequest" SG_ 1849 RRPSU_PSU_RR_GST_Byte5 0;
BA_ "NetworkRequestHoldingTime" SG_ 1849 RRPSU_PSU_RR_GST_Byte5 5000;
BA_ "Version" SG_ 1849 RRPSU_PSU_RR_GST_Byte5 "22.11.14";
BA_ "Description" SG_ 1849 RRPSU_PSU_RR_GST_Byte6 "TP Index : 166";
BA_ "UsrSigPurpose" SG_ 1849 RRPSU_PSU_RR_GST_Byte6 4;
BA_ "UserSigValidity" SG_ 1849 RRPSU_PSU_RR_GST_Byte6 0;
BA_REL_ "GenSigTimeoutTime" BU_SG_REL_ CGW_CCU SG_ 1849 RRPSU_PSU_RR_GST_Byte6 0;
BA_ "NetworkRequest" SG_ 1849 RRPSU_PSU_RR_GST_Byte6 0;
BA_ "NetworkRequestHoldingTime" SG_ 1849 RRPSU_PSU_RR_GST_Byte6 5000;
BA_ "Version" SG_ 1849 RRPSU_PSU_RR_GST_Byte6 "22.11.14";
BA_ "Description" SG_ 1849 RRPSU_PSU_RR_GST_Byte7 "TP Index : 166";
BA_ "UsrSigPurpose" SG_ 1849 RRPSU_PSU_RR_GST_Byte7 4;
BA_ "UserSigValidity" SG_ 1849 RRPSU_PSU_RR_GST_Byte7 0;
BA_REL_ "GenSigTimeoutTime" BU_SG_REL_ CGW_CCU SG_ 1849 RRPSU_PSU_RR_GST_Byte7 0;
BA_ "NetworkRequest" SG_ 1849 RRPSU_PSU_RR_GST_Byte7 0;
BA_ "NetworkRequestHoldingTime" SG_ 1849 RRPSU_PSU_RR_GST_Byte7 5000;
BA_ "Version" SG_ 1849 RRPSU_PSU_RR_GST_Byte7 "22.11.14";
BA_ "Description" SG_ 1849 RRPSU_PSU_RR_GST_Byte1 "TP Index : 166";
BA_ "UsrSigPurpose" SG_ 1849 RRPSU_PSU_RR_GST_Byte1 4;
BA_ "UserSigValidity" SG_ 1849 RRPSU_PSU_RR_GST_Byte1 0;
BA_REL_ "GenSigTimeoutTime" BU_SG_REL_ CGW_CCU SG_ 1849 RRPSU_PSU_RR_GST_Byte1 0;
BA_ "NetworkRequest" SG_ 1849 RRPSU_PSU_RR_GST_Byte1 0;
BA_ "NetworkRequestHoldingTime" SG_ 1849 RRPSU_PSU_RR_GST_Byte1 5000;
BA_ "Version" SG_ 1849 RRPSU_PSU_RR_GST_Byte1 "22.11.14";
BA_ "GenMsgSendType" BO_ 799 0;
BA_ "Description" SG_ 799 SBCM_DRV_Crc1Val "The data area for CRC calculation is based on the data length (DLC) of the message DB.

The CRC shall be calculated over the entire data block (excluding the CRC bytes) including the user data, alive counter and Data ID 

 

- CRC Polynomial (0x1D) , Initial Value : 0x00, XOR value : 0xFF, Data ID Mode : Both, Data ID : Message ID + 0xF800 

- The initial value is for CRC calculation and the message should be sent with the calculated result value. 

The mathematical expression to 8 bit CRC polynomial is given here. G(x) = x8 + x4 + x3 + x2 + 1";
BA_ "GenSigSendType" SG_ 799 SBCM_DRV_Crc1Val 4;
BA_ "UserSigValidity" SG_ 799 SBCM_DRV_Crc1Val 0;
BA_ "Version" SG_ 799 SBCM_DRV_Crc1Val "21.09.03";
BA_ "Description" SG_ 799 DRV_CrashUnlockCmd "Drive Crash Unlock Command";
BA_ "GenSigSendType" SG_ 799 DRV_CrashUnlockCmd 4;
BA_ "UserSigValidity" SG_ 799 DRV_CrashUnlockCmd 0;
BA_REL_ "GenSigTimeoutTime" BU_SG_REL_ BLTN_CAM SG_ 799 DRV_CrashUnlockCmd 1500;
BA_ "NetworkRequest" SG_ 799 DRV_CrashUnlockCmd 0;
BA_ "Version" SG_ 799 DRV_CrashUnlockCmd "21.07.07";
BA_ "Description" SG_ 799 C_ApprOpenStatus "This is for Power Door System enable/disable signal.";
BA_ "GenSigSendType" SG_ 799 C_ApprOpenStatus 4;
BA_ "UserSigValidity" SG_ 799 C_ApprOpenStatus 0;
BA_ "Version" SG_ 799 C_ApprOpenStatus "21.07.07";
BA_ "Description" SG_ 799 SBCM_DRV_AlvCnt1Val "For the first transmission request for a data element the counter shall be initialized with 0 and shall be incremented by 1

for every subsequent send request. When the counter reaches the maximum value(0xE), then it shall restart with 0 for the next send request";
BA_ "GenSigSendType" SG_ 799 SBCM_DRV_AlvCnt1Val 4;
BA_ "UserSigValidity" SG_ 799 SBCM_DRV_AlvCnt1Val 0;
BA_ "Version" SG_ 799 SBCM_DRV_AlvCnt1Val "21.09.03";
BA_ "Description" SG_ 799 DoorLock_DrvKeyLkSwSta_SBCM "Door Lock Driver Mechanical Key Input Signal";
BA_ "GenSigSendType" SG_ 799 DoorLock_DrvKeyLkSwSta_SBCM 4;
BA_ "UserSigValidity" SG_ 799 DoorLock_DrvKeyLkSwSta_SBCM 0;
BA_ "NetworkRequest" SG_ 799 DoorLock_DrvKeyLkSwSta_SBCM 0;
BA_ "Version" SG_ 799 DoorLock_DrvKeyLkSwSta_SBCM "21.07.07";
BA_ "Description" SG_ 799 DoorLock_DrvKeyUnLkSwSta_SBCM "Door Drive Mechanical Key Unlock Switch State";
BA_ "GenSigSendType" SG_ 799 DoorLock_DrvKeyUnLkSwSta_SBCM 4;
BA_ "UserSigValidity" SG_ 799 DoorLock_DrvKeyUnLkSwSta_SBCM 0;
BA_ "NetworkRequest" SG_ 799 DoorLock_DrvKeyUnLkSwSta_SBCM 0;
BA_ "Version" SG_ 799 DoorLock_DrvKeyUnLkSwSta_SBCM "21.07.07";
BA_ "Description" SG_ 799 Warn_DrvDrSwSta_SBCM "Warning Drive Door Switch State";
BA_ "GenSigSendType" SG_ 799 Warn_DrvDrSwSta_SBCM 4;
BA_ "UserSigValidity" SG_ 799 Warn_DrvDrSwSta_SBCM 0;
BA_REL_ "GenSigTimeoutTime" BU_SG_REL_ ATS SG_ 799 Warn_DrvDrSwSta_SBCM 1500;
BA_REL_ "GenSigTimeoutTime" BU_SG_REL_ BLTN_CAM SG_ 799 Warn_DrvDrSwSta_SBCM 1500;
BA_REL_ "GenSigTimeoutTime" BU_SG_REL_ GW_DPSU SG_ 799 Warn_DrvDrSwSta_SBCM 1500;
BA_REL_ "GenSigTimeoutTime" BU_SG_REL_ PSB SG_ 799 Warn_DrvDrSwSta_SBCM 1500;
BA_REL_ "GenSigTimeoutTime" BU_SG_REL_ RWPC SG_ 799 Warn_DrvDrSwSta_SBCM 1500;
BA_REL_ "GenSigTimeoutTime" BU_SG_REL_ WPC SG_ 799 Warn_DrvDrSwSta_SBCM 1500;
BA_REL_ "GenSigTimeoutTime" BU_SG_REL_ WPC2 SG_ 799 Warn_DrvDrSwSta_SBCM 1500;
BA_ "NetworkRequest" SG_ 799 Warn_DrvDrSwSta_SBCM 0;
BA_ "Version" SG_ 799 Warn_DrvDrSwSta_SBCM "21.09.05";
BA_ "Description" SG_ 799 DoorLock_DrvDrUnLkSta_SBCM "Drive Door Lock Unlock Status";
BA_ "GenSigSendType" SG_ 799 DoorLock_DrvDrUnLkSta_SBCM 4;
BA_ "UserSigValidity" SG_ 799 DoorLock_DrvDrUnLkSta_SBCM 0;
BA_REL_ "GenSigTimeoutTime" BU_SG_REL_ ATS SG_ 799 DoorLock_DrvDrUnLkSta_SBCM 1500;
BA_REL_ "GenSigTimeoutTime" BU_SG_REL_ GW_DPSU SG_ 799 DoorLock_DrvDrUnLkSta_SBCM 1500;
BA_ "NetworkRequest" SG_ 799 DoorLock_DrvDrUnLkSta_SBCM 0;
BA_ "Version" SG_ 799 DoorLock_DrvDrUnLkSta_SBCM "21.09.05";
BA_ "Description" SG_ 799 DRV_SEAWarn_LH "Drive (FLH) Door SEA Warning";
BA_ "GenSigSendType" SG_ 799 DRV_SEAWarn_LH 4;
BA_ "UserSigValidity" SG_ 799 DRV_SEAWarn_LH 0;
BA_ "NetworkRequest" SG_ 799 DRV_SEAWarn_LH 0;
BA_ "Version" SG_ 799 DRV_SEAWarn_LH "21.07.07";
BA_ "Description" SG_ 799 DRV_SEAWarn_RH "Drive (FRH) Door SEA Warning";
BA_ "GenSigSendType" SG_ 799 DRV_SEAWarn_RH 4;
BA_ "UserSigValidity" SG_ 799 DRV_SEAWarn_RH 0;
BA_ "NetworkRequest" SG_ 799 DRV_SEAWarn_RH 0;
BA_ "Version" SG_ 799 DRV_SEAWarn_RH "21.07.07";
BA_ "Description" SG_ 799 DRV_SEWWarn_LH "Drive (FLH) Door Safety Exit Warning";
BA_ "GenSigSendType" SG_ 799 DRV_SEWWarn_LH 4;
BA_ "UserSigValidity" SG_ 799 DRV_SEWWarn_LH 0;
BA_ "NetworkRequest" SG_ 799 DRV_SEWWarn_LH 0;
BA_ "Version" SG_ 799 DRV_SEWWarn_LH "21.07.07";
BA_ "Description" SG_ 799 DRV_SEWWarn_RH "Drive (FRH) Door Safety Exit Warning";
BA_ "GenSigSendType" SG_ 799 DRV_SEWWarn_RH 4;
BA_ "UserSigValidity" SG_ 799 DRV_SEWWarn_RH 0;
BA_ "NetworkRequest" SG_ 799 DRV_SEWWarn_RH 0;
BA_ "Version" SG_ 799 DRV_SEWWarn_RH "21.07.07";
BA_ "GenSigSendType" SG_ 799 DRV_MRActivationAlarm 4;
BA_ "UserSigValidity" SG_ 799 DRV_MRActivationAlarm 0;
BA_ "NetworkRequest" SG_ 799 DRV_MRActivationAlarm 0;
BA_ "NetworkRequestHoldingTime" SG_ 799 DRV_MRActivationAlarm 5000;
BA_ "Version" SG_ 799 DRV_MRActivationAlarm "21.07.07";
BA_ "GenSigSendType" SG_ 799 DRV_ReleaseWarn 4;
BA_ "UserSigValidity" SG_ 799 DRV_ReleaseWarn 0;
BA_ "NetworkRequest" SG_ 799 DRV_ReleaseWarn 0;
BA_ "NetworkRequestHoldingTime" SG_ 799 DRV_ReleaseWarn 5000;
BA_ "Version" SG_ 799 DRV_ReleaseWarn "21.09.05";
BA_ "Description" SG_ 799 Latch_TypeOption_DRV "If the E-Lacth is applied, the signal will be send for identify the door lock/unlock function and option.";
BA_ "GenSigSendType" SG_ 799 Latch_TypeOption_DRV 4;
BA_ "UserSigValidity" SG_ 799 Latch_TypeOption_DRV 0;
BA_REL_ "GenSigTimeoutTime" BU_SG_REL_ GW_APSU SG_ 799 Latch_TypeOption_DRV 1500;
BA_REL_ "GenSigTimeoutTime" BU_SG_REL_ GW_DPSU SG_ 799 Latch_TypeOption_DRV 1500;
BA_REL_ "GenSigTimeoutTime" BU_SG_REL_ GW_RLPSU SG_ 799 Latch_TypeOption_DRV 1500;
BA_REL_ "GenSigTimeoutTime" BU_SG_REL_ GW_RRPSU SG_ 799 Latch_TypeOption_DRV 1500;
BA_REL_ "GenSigTimeoutTime" BU_SG_REL_ RWPC SG_ 799 Latch_TypeOption_DRV 1500;
BA_REL_ "GenSigTimeoutTime" BU_SG_REL_ WPC SG_ 799 Latch_TypeOption_DRV 1500;
BA_REL_ "GenSigTimeoutTime" BU_SG_REL_ WPC2 SG_ 799 Latch_TypeOption_DRV 1500;
BA_ "NetworkRequest" SG_ 799 Latch_TypeOption_DRV 0;
BA_ "Version" SG_ 799 Latch_TypeOption_DRV "21.07.07";
BA_ "GenSigSendType" SG_ 799 DRV_SWFailAlarm 4;
BA_ "UserSigValidity" SG_ 799 DRV_SWFailAlarm 0;
BA_ "NetworkRequest" SG_ 799 DRV_SWFailAlarm 0;
BA_ "NetworkRequestHoldingTime" SG_ 799 DRV_SWFailAlarm 5000;
BA_ "Version" SG_ 799 DRV_SWFailAlarm "21.07.07";
BA_ "GenSigSendType" SG_ 799 USM_PwrDRApprOpnSetSta 4;
BA_ "UserSigValidity" SG_ 799 USM_PwrDRApprOpnSetSta 0;
BA_ "NetworkRequest" SG_ 799 USM_PwrDRApprOpnSetSta 0;
BA_ "NetworkRequestHoldingTime" SG_ 799 USM_PwrDRApprOpnSetSta 5000;
BA_ "Version" SG_ 799 USM_PwrDRApprOpnSetSta "21.07.07";
BA_ "GenSigSendType" SG_ 799 USM_PwrDRApprOpnSetOpt 4;
BA_ "UserSigValidity" SG_ 799 USM_PwrDRApprOpnSetOpt 0;
BA_ "NetworkRequest" SG_ 799 USM_PwrDRApprOpnSetOpt 0;
BA_ "NetworkRequestHoldingTime" SG_ 799 USM_PwrDRApprOpnSetOpt 5000;
BA_ "Version" SG_ 799 USM_PwrDRApprOpnSetOpt "21.07.07";
BA_ "GenSigSendType" SG_ 799 USM_PwrDRCloseByRKELockSta 4;
BA_ "UserSigValidity" SG_ 799 USM_PwrDRCloseByRKELockSta 0;
BA_ "NetworkRequest" SG_ 799 USM_PwrDRCloseByRKELockSta 0;
BA_ "NetworkRequestHoldingTime" SG_ 799 USM_PwrDRCloseByRKELockSta 5000;
BA_ "Version" SG_ 799 USM_PwrDRCloseByRKELockSta "22.10.01";
BA_ "GenSigSendType" SG_ 799 USM_PwrDRCloseByRKELockOpt 4;
BA_ "UserSigValidity" SG_ 799 USM_PwrDRCloseByRKELockOpt 0;
BA_ "NetworkRequest" SG_ 799 USM_PwrDRCloseByRKELockOpt 0;
BA_ "NetworkRequestHoldingTime" SG_ 799 USM_PwrDRCloseByRKELockOpt 5000;
BA_ "Version" SG_ 799 USM_PwrDRCloseByRKELockOpt "22.10.01";
BA_ "GenSigSendType" SG_ 799 USM_PwrDRCloseByBrakeSta 4;
BA_ "UserSigValidity" SG_ 799 USM_PwrDRCloseByBrakeSta 0;
BA_ "NetworkRequest" SG_ 799 USM_PwrDRCloseByBrakeSta 0;
BA_ "NetworkRequestHoldingTime" SG_ 799 USM_PwrDRCloseByBrakeSta 5000;
BA_ "Version" SG_ 799 USM_PwrDRCloseByBrakeSta "21.07.07";
BA_ "GenSigSendType" SG_ 799 USM_PwrDRCloseByBrakeOpt 4;
BA_ "UserSigValidity" SG_ 799 USM_PwrDRCloseByBrakeOpt 0;
BA_ "NetworkRequest" SG_ 799 USM_PwrDRCloseByBrakeOpt 0;
BA_ "NetworkRequestHoldingTime" SG_ 799 USM_PwrDRCloseByBrakeOpt 5000;
BA_ "Version" SG_ 799 USM_PwrDRCloseByBrakeOpt "21.07.07";
BA_ "GenSigSendType" SG_ 799 USM_PwrDRBuzzerSta 4;
BA_ "UserSigValidity" SG_ 799 USM_PwrDRBuzzerSta 0;
BA_ "NetworkRequest" SG_ 799 USM_PwrDRBuzzerSta 0;
BA_ "NetworkRequestHoldingTime" SG_ 799 USM_PwrDRBuzzerSta 5000;
BA_ "Version" SG_ 799 USM_PwrDRBuzzerSta "21.07.07";
BA_ "GenSigSendType" SG_ 799 USM_PwrDRBuzzerOpt 4;
BA_ "UserSigValidity" SG_ 799 USM_PwrDRBuzzerOpt 0;
BA_ "NetworkRequest" SG_ 799 USM_PwrDRBuzzerOpt 0;
BA_ "NetworkRequestHoldingTime" SG_ 799 USM_PwrDRBuzzerOpt 5000;
BA_ "Version" SG_ 799 USM_PwrDRBuzzerOpt "21.07.07";
BA_ "GenSigSendType" SG_ 799 PDS_TypeOption_DRV 4;
BA_ "UserSigValidity" SG_ 799 PDS_TypeOption_DRV 0;
BA_ "NetworkRequest" SG_ 799 PDS_TypeOption_DRV 0;
BA_ "Version" SG_ 799 PDS_TypeOption_DRV "23.04.02";
BA_ "Description" SG_ 799 C_DrvDoorApproachOpen "Fob searching start and stop signal for PDS.";
BA_ "GenSigSendType" SG_ 799 C_DrvDoorApproachOpen 4;
BA_ "UserSigValidity" SG_ 799 C_DrvDoorApproachOpen 0;
BA_ "Version" SG_ 799 C_DrvDoorApproachOpen "21.07.07";
BA_ "Description" SG_ 799 C_DrvDoorApproachClose "To close the door automatically, request the fob searching signal";
BA_ "GenSigSendType" SG_ 799 C_DrvDoorApproachClose 4;
BA_ "UserSigValidity" SG_ 799 C_DrvDoorApproachClose 0;
BA_ "Version" SG_ 799 C_DrvDoorApproachClose "21.07.07";
BA_ "GenSigSendType" SG_ 799 DoorLock_PDSLkSwSta_DRV 4;
BA_ "UserSigValidity" SG_ 799 DoorLock_PDSLkSwSta_DRV 0;
BA_ "NetworkRequest" SG_ 799 DoorLock_PDSLkSwSta_DRV 0;
BA_ "Version" SG_ 799 DoorLock_PDSLkSwSta_DRV "21.07.07";
BA_ "GenSigSendType" SG_ 799 DRVDoorPushAlarm 4;
BA_ "UserSigValidity" SG_ 799 DRVDoorPushAlarm 0;
BA_ "NetworkRequest" SG_ 799 DRVDoorPushAlarm 0;
BA_ "NetworkRequestHoldingTime" SG_ 799 DRVDoorPushAlarm 5000;
BA_ "Version" SG_ 799 DRVDoorPushAlarm "21.07.07";
BA_ "GenMsgSendType" BO_ 830 0;
BA_ "Description" SG_ 830 USM_CmdWPC2Sta "USM request value of WPC2";
BA_ "GenSigSendType" SG_ 830 USM_CmdWPC2Sta 4;
BA_ "UserSigValidity" SG_ 830 USM_CmdWPC2Sta 0;
BA_REL_ "GenSigTimeoutTime" BU_SG_REL_ CGW_CCU SG_ 830 USM_CmdWPC2Sta 1500;
BA_ "NetworkRequest" SG_ 830 USM_CmdWPC2Sta 0;
BA_ "NetworkRequestHoldingTime" SG_ 830 USM_CmdWPC2Sta 5000;
BA_ "Version" SG_ 830 USM_CmdWPC2Sta "22.02.06";
BA_ "Description" SG_ 830 WPC2_OptSta "Apply dual WPC information	2";
BA_ "GenSigSendType" SG_ 830 WPC2_OptSta 4;
BA_ "UserSigValidity" SG_ 830 WPC2_OptSta 0;
BA_REL_ "GenSigTimeoutTime" BU_SG_REL_ CGW_CCU SG_ 830 WPC2_OptSta 1500;
BA_ "NetworkRequest" SG_ 830 WPC2_OptSta 0;
BA_ "NetworkRequestHoldingTime" SG_ 830 WPC2_OptSta 5000;
BA_ "Version" SG_ 830 WPC2_OptSta "22.03.02";
BA_ "Description" SG_ 830 WPC2_SWVerMajor1 "Indicate the WPC2 software version as follows:

- The software version is displayed in three digits.

- The Major and Minor digits are separated by '.'

- Signal values are transmitted to ASCII codes.



¡Ø Example

WPC2_SWVerMajor1 : 0x41 (HEX) -> ASCII CODE : 'A' 

WPC2_SWVerMinor1 : 0x30 (HEX) -> ASCII CODE : '0'

WPC2_SWVerMinor2 : 0x33 (HEX) -> ASCII CODE : '3'

=> WPC2 S/W Ver is displayed 'A.03'";
BA_ "GenSigSendType" SG_ 830 WPC2_SWVerMajor1 4;
BA_ "UserSigValidity" SG_ 830 WPC2_SWVerMajor1 0;
BA_REL_ "GenSigTimeoutTime" BU_SG_REL_ CGW_CCU SG_ 830 WPC2_SWVerMajor1 1500;
BA_ "Version" SG_ 830 WPC2_SWVerMajor1 "22.02.06";
BA_ "Description" SG_ 830 WPC2_PhnLftWrngSta "Warning by WPC2 for User (Phone left in vehicle)";
BA_ "GenSigSendType" SG_ 830 WPC2_PhnLftWrngSta 4;
BA_ "UserSigValidity" SG_ 830 WPC2_PhnLftWrngSta 0;
BA_REL_ "GenSigTimeoutTime" BU_SG_REL_ CGW_CCU SG_ 830 WPC2_PhnLftWrngSta 1500;
BA_ "NetworkRequest" SG_ 830 WPC2_PhnLftWrngSta 0;
BA_ "NetworkRequestHoldingTime" SG_ 830 WPC2_PhnLftWrngSta 5000;
BA_ "Version" SG_ 830 WPC2_PhnLftWrngSta "24.01.00";
BA_ "Description" SG_ 830 WPC2_SWVerMinor1 "Indicate the WPC2 software version as follows:

- The software version is displayed in three digits.

- The Major and Minor digits are separated by '.'

- Signal values are transmitted to ASCII codes.



¡Ø Example

WPC2_SWVerMajor1 : 0x41 (HEX) -> ASCII CODE : 'A' 

WPC2_SWVerMinor1 : 0x30 (HEX) -> ASCII CODE : '0'

WPC2_SWVerMinor2 : 0x33 (HEX) -> ASCII CODE : '3'

=> WPC2 S/W Ver is displayed 'A.03'";
BA_ "GenSigSendType" SG_ 830 WPC2_SWVerMinor1 4;
BA_ "UserSigValidity" SG_ 830 WPC2_SWVerMinor1 0;
BA_REL_ "GenSigTimeoutTime" BU_SG_REL_ CGW_CCU SG_ 830 WPC2_SWVerMinor1 1500;
BA_ "Version" SG_ 830 WPC2_SWVerMinor1 "22.02.06";
BA_ "Description" SG_ 830 WPC2_SWVerMinor2 "Indicate the WPC2 software version as follows:

- The software version is displayed in three digits.

- The Major and Minor digits are separated by '.'

- Signal values are transmitted to ASCII codes.



¡Ø Example

WPC2_SWVerMajor1 : 0x41 (HEX) -> ASCII CODE : 'A' 

WPC2_SWVerMinor1 : 0x30 (HEX) -> ASCII CODE : '0'

WPC2_SWVerMinor2 : 0x33 (HEX) -> ASCII CODE : '3'

=> WPC2 S/W Ver is displayed 'A.03'";
BA_ "GenSigSendType" SG_ 830 WPC2_SWVerMinor2 4;
BA_ "UserSigValidity" SG_ 830 WPC2_SWVerMinor2 0;
BA_REL_ "GenSigTimeoutTime" BU_SG_REL_ CGW_CCU SG_ 830 WPC2_SWVerMinor2 1500;
BA_ "Version" SG_ 830 WPC2_SWVerMinor2 "22.02.06";
BA_ "Description" SG_ 830 WPC2_IndSyncVal "WPC IND ANIMATION SYNC SIGNAL";
BA_ "GenSigSendType" SG_ 830 WPC2_IndSyncVal 4;
BA_ "TimeoutValue" SG_ 830 WPC2_IndSyncVal "0x0";
BA_ "UserSigValidity" SG_ 830 WPC2_IndSyncVal 3;
BA_REL_ "GenSigTimeoutTime" BU_SG_REL_ RWPC SG_ 830 WPC2_IndSyncVal 1500;
BA_REL_ "GenSigTimeoutTime" BU_SG_REL_ WPC SG_ 830 WPC2_IndSyncVal 1500;
BA_ "Version" SG_ 830 WPC2_IndSyncVal "22.04.01";
VAL_ 788 APSU_AstSlidePosition 0 "0x0x0~0xFE:POSITION" 254 "0x0x0~0xFE:POSITION" 255 "invalid" ;
VAL_ 788 APSU_AstHeightPosition 0 "0x0x0~0xFE:POSITION" 254 "0x0x0~0xFE:POSITION" 255 "invalid" ;
VAL_ 788 APSU_AstReclinePosition 0 "0x0x0~0xFE:POSITION" 254 "0x0x0~0xFE:POSITION" 255 "invalid" ;
VAL_ 788 APSU_AstRelaxTiltPosition 0 "0x0x0~0xFE:POSITION" 254 "0x0x0~0xFE:POSITION" 255 "invalid" ;
VAL_ 2470761217 CLU_Crc7Val 0 "0x0x0~0xFFFF:CRCValue" 65535 "0x0x0~0xFFFF:CRCValue" ;
VAL_ 2470761217 CLU_AlvCnt7Val 0 "0x0x0~0xFF:AlvCntValue" 255 "0x0x0~0xFF:AlvCntValue" ;
VAL_ 2470761217 USM_AutoDrLkSetReq 0 "Default" 1 "Off" 2 "Vehicle Speed On (15Km)" 3 "Shift Lever On" 4 "Invalid" ;
VAL_ 2470761217 USM_AutoDrUnlckSetReq 0 "Default" 1 "Off" 2 "Key Out On (AllDoors)" 3 "Shift Lever On (AllDoors)" 4 "Override" 5 "Invalid" 6 "Key Out On (Driver Door)" 7 "Shift Lever On (Driver Door)" ;
VAL_ 2470761217 USM_HLmpEscrtSetReq 0 "Default Value" 1 "Escort Off" 2 "Escort On" 3 "Invalid" ;
VAL_ 2470761217 USM_SmrtTrnkSetReq 0 "Default" 1 "HandsFree Off" 2 "HandsFree On" 3 "Reserved" 4 "Invalid" ;
VAL_ 2470761217 USM_MdLmpSetReq 0 "Default Value" 1 "Mood Lamp Off" 2 "Mood Lamp On" 3 "Modd Lamp Auto" 4 "Invalid" 5 "Reserved" 6 "Reserved" 7 "Reserved" ;
VAL_ 2470761217 USM_HrnAnswerBckSetReq 0 "Default" 1 "Arm Disarm Buzzer Off" 2 "Arm Disarm Buzzer On" 3 "Invalid" ;
VAL_ 2470761217 USM_OneTouchTrplTrnSetReq 0 "Default" 1 "One Touch Turn Off" 2 "3 Flashing" 3 "5 Flashing" 4 "7 Flashing" 5 "Invalid" 6 "Reserved" 7 "Reserved" ;
VAL_ 2470761217 USM_PsmSetReq 0 "Default" 1 "Off (Disable)" 2 "50mmOn (Enable)" 3 "75mmOn (Enable)" 4 "Reserved" 5 "Reserved" 6 "Reserved" 7 "Invalid" ;
VAL_ 2470761217 USM_PtgmSetReq 0 "Default" 1 "Power Mode" 2 "Manual Mode" 3 "Invalid" ;
VAL_ 2470761217 USM_ScmSetReq 0 "Default" 1 "Steering Off" 2 "Steering On" 3 "Invalid" ;
VAL_ 2470761217 USM_OSTempUnitSetReq 0 "Default" 1 "Centigrade(¡É)" 2 "Fahrenheit(¢µ)" 3 "Invalid" ;
VAL_ 2470761217 USM_TfrChgSetReq 0 "Default" 1 "Disable" 2 "Enable" 3 "Reserved" ;
VAL_ 2470761217 USM_WALModSetreq 0 "Default" 1 "Disable" 2 "Enable" 3 "Invalid" ;
VAL_ 2470761217 USM_EscOffSetReq 0 "Default" 1 "Off Mode" 2 "Normal Mode" 3 "Sport mode" 4 "Reserved" 5 "Reserved" 6 "Reserved" 7 "Invalid" ;
VAL_ 2470761217 USM_PsmHgtSetReq 0 "Default(USM ¹Ì±¸¼º)" 1 "Off(Disable)" 2 "On(Enable)" 3 "Reserved" 4 "Reserved" 5 "Reserved" 6 "Reserved" 7 "Invalid" ;
VAL_ 2470761217 USM_Clu_BtnIllumiAlwaysOnReq 0 "Default" 1 "Off" 2 "On" 3 "Invalid" ;
VAL_ 733 CMS_LH_Crc1Val 0 "0x0x0~0xFF:CRCValue" 255 "0x0x0~0xFF:CRCValue" ;
VAL_ 733 CMS_LH_AlvCnt1Val 0 "AlvCntValue" 1 "AlvCntValue" 2 "AlvCntValue" 3 "AlvCntValue" 4 "AlvCntValue" 5 "AlvCntValue" 6 "AlvCntValue" 7 "AlvCntValue" 8 "AlvCntValue" 9 "AlvCntValue" 10 "AlvCntValue" 11 "AlvCntValue" 12 "AlvCntValue" 13 "AlvCntValue" 14 "AlvCntValue" 15 "AlvCntValue" ;
VAL_ 733 USM_TurnDstLnDispSta 0 "Default" 1 "Off" 2 "On" 3 "RESERVED" ;
VAL_ 733 USM_TurnDstLnDispStaRH 0 "Default" 1 "Off" 2 "On" 3 "RESERVED" ;
VAL_ 733 USM_RhstaLvlEnaSta 0 "Default" 1 "Off" 2 "On" 3 "RESERVED" ;
VAL_ 733 USM_RhstaLvlEnaStaRH 0 "Default" 1 "Off" 2 "On" 3 "RESERVED" ;
VAL_ 733 USM_CMSDayBrgtnsLvlLHSta 0 "-5 Level" 1 "-4 Level" 2 "-3 Level" 3 "-2 Level" 4 "-1 Level" 5 "0 Level" 6 "1 Level" 7 "2 Level" 8 "3 Level" 9 "4 Level" 10 "5 Level" 11 "RESERVED" 12 "RESERVED" 13 "RESERVED" 14 "Error Indicator" 15 "RESERVED" ;
VAL_ 733 USM_CMSNgtBrgtnsLvlLHSta 0 "-5 Level" 1 "-4 Level" 2 "-3 Level" 3 "-2 Level" 4 "-1 Level" 5 "0 Level" 6 "1 Level" 7 "2 Level" 8 "3 Level" 9 "4 Level" 10 "5 Level" 11 "RESERVED" 12 "RESERVED" 13 "RESERVED" 14 "Error Indicator" 15 "RESERVED" ;
VAL_ 733 IMS_CMSPlayBackSta_LH 0 "Stop" 1 "Play 1" 2 "Play 2" 3 "Play 3" 4 "Smart IMS" 5 "Profile 1" 6 "Profile 2" 7 "Guest" 8 "RESERVED" 9 "RESERVED" 10 "RESERVED" 11 "RESERVED" 12 "RESERVED" 13 "RESERVED" 14 "RESERVED" 15 "Error Indicator" ;
VAL_ 733 CMSFldReq 0 "Default" 1 "Folding Request" 2 "Unfolding Request" 3 "RESERVED" ;
VAL_ 733 CMS_LH_FoldingSta 0 "Off" 1 "Folding" 2 "RESERVED" 3 "Error Indicator" ;
VAL_ 733 CMS_LH_UnfoldingSta 0 "Off" 1 "Unfolding" 2 "RESERVED" 3 "Error Indicator" ;
VAL_ 733 CMS_LHVerPosVal 0 "0x0x00~0xFA:Real values" 250 "0x0x00~0xFA:Real values" 251 "RESERVED" 252 "RESERVED" 253 "RESERVED" 254 "RESERVED" 255 "Error Indicator" ;
VAL_ 733 CMS_LHHorPosVal 0 "0x0x00~0xFA:Real values" 250 "0x0x00~0xFA:Real values" 251 "RESERVED" 252 "RESERVED" 253 "RESERVED" 254 "RESERVED" 255 "Error Indicator" ;
VAL_ 733 Monitor_ViewPanningCmd 0 "No Movement" 1 "Move Up" 2 "Move Down" 3 "Move Left" 4 "Move Right" 5 "RESERVED" 6 "RESERVED" 7 "RESERVED" ;
VAL_ 2395189249 DATC_Crc8Val 0 "0x0x0~0xFFFF:CRCValue" 65535 "0x0x0~0xFFFF:CRCValue" ;
VAL_ 2395189249 DATC_AlvCnt8Val 0 "0x0x0~0xFF:AlvCntValue" 255 "0x0x0~0xFF:AlvCntValue" ;
VAL_ 2395189249 DATC_SmrtVntOnOffSta 0 "Fuction Off" 1 "Function On" 2 "Not Used" 3 "Error Indicator" ;
VAL_ 2395189249 DATC_PsAutoDis 0 "AUTO Off" 1 "AUTO On" 2 "Not used" 3 "Error Indicator" ;
VAL_ 2395189249 DATC_RrAutoDis 0 "AUTO Off(Default)" 1 "AUTO On" 2 "Reserved" 3 "Error Indicator" ;
VAL_ 2395189249 DATC_RrDrvModDis 0 "Off(Blank Display, ÅäÃâ¸ðµå ¹ÌÇ¥½Ã ¿¹) Auto ½Ã)(Default)" 1 "VENT" 2 "B_L" 3 "FLOOR" 4 "MIX (7 MODE DEF FLOOR)" 5 "DEF (MAX DEF)" 6 "AUTO DEFOG" 7 "7 MODE DEF VENT" 8 "MODE AUTO" 9 "7 MODE DEF VENT FLOOR" 10 "7 MODE DEF" 11 "DEF VENT (Arrow)" 12 "DEF FLOOR (Arrow)" 13 "DEF VENT FLOOR (Arrow)" 14 "DEF (Arrow)" 15 "Error Indicator" ;
VAL_ 2395189249 DATC_RrPassModDis 0 "Off(Blank Display, ÅäÃâ¸ðµå ¹ÌÇ¥½Ã ¿¹) Auto ½Ã)" 1 "VENT" 2 "B_L" 3 "FLOOR" 4 "MIX (7 MODE DEF FLOOR)" 5 "DEF(MAX DEF)" 6 "AUTO DEFOG" 7 "7 MODE DEF VENT" 8 "MODE AUTO" 9 "7 MODE DEF VENT FLOOR" 10 "7 MODE DEF" 11 "DEF VENT (Arrow)" 12 "DEF FLOOR (Arrow)" 13 "DEF VENT FLOOR (Arrow)" 14 "DEF (Arrow)" 15 "Error Indicator" ;
VAL_ 2395189249 DATC_DisplayThemes 0 "Default" 1 "White Theme" 2 "Black Theme" 3 "Invalid" ;
VAL_ 2395189249 DATC_EcoZoneDis 0 "Eco Zone OFF (Default)" 1 "Eco Zone ON" 2 "Not used" 3 "Error Indicator" ;
VAL_ 2395189249 DATC_AUTOStepPS 0 "Default" 1 "OFF" 2 "1st & 2nd & 3rd On (3 Step Type)" 3 "1st & 2nd On (3 Step Type)" 4 "1st On (3 Step Type)" 5 "1st & 2nd On (2 Step Type)" 6 "1st On (2 Step Type)" 7 "Error Indicator" ;
VAL_ 2395189249 DATC_AUTOStepRR 0 "Default" 1 "OFF" 2 "1st & 2nd & 3rd On (3 Step Type)" 3 "1st & 2nd On (3 Step Type)" 4 "1st On (3 Step Type)" 5 "1st & 2nd On (2 Step Type)" 6 "1st On (2 Step Type)" 7 "Error Indicator" ;
VAL_ 2214659329 EMS_Crc7Val 0 "0x0x0~0xFFFF:CRCValue" 65535 "0x0x0~0xFFFF:CRCValue" ;
VAL_ 2214659329 EMS_AlvCnt7Val 0 "0x0x0~0xFF:AlvCntValue" 255 "0x0x0~0xFF:AlvCntValue" ;
VAL_ 2214659329 HEV_OilDilution_IncICELoad 0 "OFF" 1 "ON" ;
VAL_ 2214659329 HEV_OilDilution_ServMode 0 "OFF" 1 "Healing I" 2 "Healing II" 3 "RESERVED" ;
VAL_ 2214659329 EMS_TqLmtSta 0 "Default/Normal" 1 "O2 Sensor Pre-Heating - To be Started" 2 "O2 Sensor Pre-Heating - Can be Started" 3 "Torque Limit for Low Temperature (Catalyst Heating)" 4 "Torque Ramping" 5 "Warming up" 6 "Torque Limit for High Temperature (Catalyst Overheating Protection)" 7 "Error" ;
VAL_ 2214659329 EMS_EU7 0 "Not EU7 vehicle" 1 "EU7 vehicle" ;
VAL_ 2214659330 HEV_EngOpSta 0 "ES(Engine Stop)" 1 "ST(Start)" 2 "IS(Idle speed)" 3 "PL(Part Load)" 4 "PU(Pull)" 5 "PUC(Fuel Cut off)" ;
VAL_ 2214659330 HEV_AccelPdlVal 0 "Accelerator Pedal not activated" 1022 "Accelerator Pedal fully activated" 1023 "Accelerator Pedal is defective (fail state) or Non-ETC system (APS is not installed)" ;
VAL_ 2307024129 EMS_Crc8Val 0 "0x0x0~0xFFFF:CRCValue" 65535 "0x0x0~0xFFFF:CRCValue" ;
VAL_ 2307024129 EMS_AlvCnt8Val 0 "0x0x0~0xFF:AlvCntValue" 255 "0x0x0~0xFF:AlvCntValue" ;
VAL_ 2307024129 HEV_VbOffActSta 0 "VB Off not Act" 1 "VB Off Act" 2 "Not used" 3 "Error indicator" ;
VAL_ 2307024129 HEV_AirCompOffReq 0 "none" 1 "off request" 2 "Not used" 3 "Error indicator" ;
VAL_ 2307024129 HEV_MilConfgVal 0 "No MIL" 1 "MIL/FMY treatment OBD1" 2 "MIL/FMY treatment OBD2" 3 "MIL/FMY treatment OBD2 (US)" 4 "MIL/FMY treatment EOBD" 5 "MIL/FMY treatment KOBD" ;
VAL_ 2307024129 HEV_CF_EMS_LOCKUP 0 "Request Off" 1 "Request On" ;
VAL_ 2307024129 HEV_OilLvlSta 0 "OIL LEVEL LAMP Off" 1 "OIL LEVEL LAMP On" 2 "Not used" 3 "Error indicator" ;
VAL_ 2307024129 HEV_ImmoLmpReq 0 "Off" 1 "Blink" 2 "On" 3 "Error indicator" ;
VAL_ 2307024129 HEV_MilReq 0 "Off" 1 "On" 2 "Not used" 3 "Error indicator" ;
VAL_ 2307024129 HEV_WiperSwSta 0 "Off" 1 "On" 2 "Not used" 3 "Error indicator" ;
VAL_ 2307024129 HEV_FanOpSta 0 "Off" 1 "On" 2 "Not used" 3 "Error indicator" ;
VAL_ 2307024129 HEV_FanSta 0 "Off" 1 "Low" 2 "Middle" 3 "High" ;
VAL_ 2307024129 HEV_BrkLtSwSta 0 "Not Support" 1 "Off" 2 "On" 3 "failure" ;
VAL_ 2307024130 HEV_SoakTimeErrSta 0 "No failure detected" 1 "Failure detected" 2 "Not used" 3 "Error indicator" ;
VAL_ 2307024130 HEV_SoakTimeOvrSta 0 "Engine soaking time < 360 min" 1 "Engine soaking time ¡Ã 360 min" 2 "Not used" 3 "Error indicator" ;
VAL_ 2307024130 HEV_FuelRunOutSta 0 "None" 1 "Fuel RunOut" 2 "Not used" 3 "Error indicator" ;
VAL_ 2307024130 HEV_FuelRunOutDetSta 0 "Inactive" 1 "Active" 2 "Not used" 3 "Error indicator" ;
VAL_ 2307024131 HEV_WarmUpReq_For_DATC 0 "Engine stop request" 1 "No engine stop request" ;
VAL_ 2307024131 HEV_RbmInhbtSta 0 "Enable of standardized vehicle operation and all numerators_denominators for RBM" 1 "Inhibition of standardized vehicle operation and all numerators_denominators for RBM" 2 "Not used" 3 "Error indicator" ;
VAL_ 2307024131 HEV_EhrsTempSta 0 "Normal" 1 "High" 3 "Fault" ;
VAL_ 2307024131 HEV_Aaf_WrnLamp 0 "Lamp OFF" 1 "Lamp ON" ;
VAL_ 2307024131 HEV_OPSFail 0 "Oil Pressure Warning Lamp OFF" 1 "Oil Pressure Warning Lamp ON" ;
VAL_ 2307024131 HEV_EngDsplceTyp 255 "Error indicator" ;
VAL_ 2307024131 HEV_EngTyp2 0 "LPI" 1 "MPI" 2 "GDI" 3 "TGDI" 4 "CVVL" 5 "CVVD" 6 "PDI" 7 "FFV" 8 "TCI" 9 "VGT" 10 "Turbo" 14 "Not used" 15 "Error indicator" ;
VAL_ 2307024131 HEV_EngTyp1 0 "epsilon(¥å)" 1 "gamma(¥ã)" 2 "kappa(¥ê)" 3 "theta(¥è)" 4 "nu(¥í)" 5 "lambda(¥ë)" 6 "tau(¥ó)" 10 "S" 11 "A" 12 "R" 13 "U" 14 "D" 15 "Error indicator" ;
VAL_ 2307024131 HEV_S_F 0 "AMS" 1 "ISG" 2 "Reserved" 3 "Reserved" ;
VAL_ 2307024131 HEV_S_F_GEN 0 "No AMS" 1 "1G Generation AMS" 2 "1.5G Generation AMS" 3 "2G Generation AMS" 4 "Reserved" 5 "Reserved" 6 "Reserved" 7 "Reserved" ;
VAL_ 2307024132 HEV_OilLifeRatio 1 "Engine oil life ratio with % unit" 2 "Engine oil life ratio with % unit" 3 "Engine oil life ratio with % unit" 4 "Engine oil life ratio with % unit" 5 "Engine oil life ratio with % unit" 6 "Engine oil life ratio with % unit" 7 "Engine oil life ratio with % unit" 8 "Engine oil life ratio with % unit" 9 "Engine oil life ratio with % unit" 10 "Engine oil life ratio with % unit" 11 "Engine oil life ratio with % unit" 12 "Engine oil life ratio with % unit" 13 "Engine oil life ratio with % unit" 14 "Engine oil life ratio with % unit" 15 "Engine oil life ratio with % unit" 16 "Engine oil life ratio with % unit" 17 "Engine oil life ratio with % unit" 18 "Engine oil life ratio with % unit" 19 "Engine oil life ratio with % unit" 20 "Engine oil life ratio with % unit" 21 "Engine oil life ratio with % unit" 22 "Engine oil life ratio with % unit" 23 "Engine oil life ratio with % unit" 24 "Engine oil life ratio with % unit" 25 "Engine oil life ratio with % unit" 26 "Engine oil life ratio with % unit" 27 "Engine oil life ratio with % unit" 28 "Engine oil life ratio with % unit" 29 "Engine oil life ratio with % unit" 30 "Engine oil life ratio with % unit" 31 "Engine oil life ratio with % unit" 32 "Engine oil life ratio with % unit" 33 "Engine oil life ratio with % unit" 34 "Engine oil life ratio with % unit" 35 "Engine oil life ratio with % unit" 36 "Engine oil life ratio with % unit" 37 "Engine oil life ratio with % unit" 38 "Engine oil life ratio with % unit" 39 "Engine oil life ratio with % unit" 40 "Engine oil life ratio with % unit" 41 "Engine oil life ratio with % unit" 42 "Engine oil life ratio with % unit" 43 "Engine oil life ratio with % unit" 44 "Engine oil life ratio with % unit" 45 "Engine oil life ratio with % unit" 46 "Engine oil life ratio with % unit" 47 "Engine oil life ratio with % unit" 48 "Engine oil life ratio with % unit" 49 "Engine oil life ratio with % unit" 50 "Engine oil life ratio with % unit" 51 "Engine oil life ratio with % unit" 52 "Engine oil life ratio with % unit" 53 "Engine oil life ratio with % unit" 54 "Engine oil life ratio with % unit" 55 "Engine oil life ratio with % unit" 56 "Engine oil life ratio with % unit" 57 "Engine oil life ratio with % unit" 58 "Engine oil life ratio with % unit" 59 "Engine oil life ratio with % unit" 60 "Engine oil life ratio with % unit" 61 "Engine oil life ratio with % unit" 62 "Engine oil life ratio with % unit" 63 "Engine oil life ratio with % unit" 64 "Engine oil life ratio with % unit" 65 "Engine oil life ratio with % unit" 66 "Engine oil life ratio with % unit" 67 "Engine oil life ratio with % unit" 68 "Engine oil life ratio with % unit" 69 "Engine oil life ratio with % unit" 70 "Engine oil life ratio with % unit" 71 "Engine oil life ratio with % unit" 72 "Engine oil life ratio with % unit" 73 "Engine oil life ratio with % unit" 74 "Engine oil life ratio with % unit" 75 "Engine oil life ratio with % unit" 76 "Engine oil life ratio with % unit" 77 "Engine oil life ratio with % unit" 78 "Engine oil life ratio with % unit" 79 "Engine oil life ratio with % unit" 80 "Engine oil life ratio with % unit" 81 "Engine oil life ratio with % unit" 82 "Engine oil life ratio with % unit" 83 "Engine oil life ratio with % unit" 84 "Engine oil life ratio with % unit" 85 "Engine oil life ratio with % unit" 86 "Engine oil life ratio with % unit" 87 "Engine oil life ratio with % unit" 88 "Engine oil life ratio with % unit" 89 "Engine oil life ratio with % unit" 90 "Engine oil life ratio with % unit" 91 "Engine oil life ratio with % unit" 92 "Engine oil life ratio with % unit" 93 "Engine oil life ratio with % unit" 94 "Engine oil life ratio with % unit" 95 "Engine oil life ratio with % unit" 96 "Engine oil life ratio with % unit" 97 "Engine oil life ratio with % unit" 98 "Engine oil life ratio with % unit" 99 "Engine oil life ratio with % unit" 100 "Engine oil life ratio with % unit" 101 "Not used" 102 "Not used" 103 "Not used" 104 "Not used" 105 "Not used" 106 "Not used" 107 "Not used" 108 "Not used" 109 "Not used" 110 "Not used" 111 "Not used" 112 "Not used" 113 "Not used" 114 "Not used" 115 "Not used" 116 "Not used" 117 "Not used" 118 "Not used" 119 "Not used" 120 "Not used" 121 "Not used" 122 "Not used" 123 "Not used" 124 "Not used" 125 "Not used" 126 "Not used" 127 "Error" ;
VAL_ 2307024132 HEV_OilLifeEna 0 "Oil life monitoring Not applied" 1 "Oil life monitoring Applied" 2 "Reserved" 3 "Error" ;
VAL_ 2307024132 HEV_OilLifeWarn 0 "No display" 1 "'Change engine oil' warning, 1st step (Low urgency)" 2 "'Change engine oil' warning, 2nd step (High urgency)" 3 "Oil change question based on oil temperature" 4 "Oil change confirm based on oil temperature" 5 "Reserved" 6 "Reserved" 7 "Error" ;
VAL_ 2307024132 HEV_RECTrigSta 0 "No detected" 1 "REC detected" ;
VAL_ 2307024132 HEV_PendingTrigSta 0 "No detected" 1 "Pending detected" ;
VAL_ 2277634049 EPB_Crc1Val 0 "0x0x0~0xFFFF:CRCValue" 65535 "0x0x0~0xFFFF:CRCValue" ;
VAL_ 2277634049 EPB_AlvCnt1Val 0 "0x0x0~0xFF:AlvCntValue" 255 "0x0x0~0xFF:AlvCntValue" ;
VAL_ 2277634049 EPB_LmpStaDis 0 "Release State (EPB AVH)" 1 "Apply State (EPB)" 2 "Dynamic Braking (EPB) or Driver Action Requested" ;
VAL_ 2277634049 EPB_FlrLmpStaDis 0 "No failure" 1 "Failure detected or in diagnosis mode" 2 "EOL configuration not done or Emergency released" 3 "Reserved" 4 "Reserved" 5 "Reserved" 6 "Reserved" 7 "Reserved" 8 "Reserved" 9 "Reserved" 10 "Reserved" 11 "Reserved" 12 "Reserved" 13 "Reserved" 14 "Not used" 15 "Error Indicator" ;
VAL_ 2277634049 EPB_OutDataDis 0 "Off" 1 "EPB is in maintenance mode" 2 "Driver tries to DAR but safety condition is not satisfied" 3 "EPB applies by ESC request" 4 "Driver tries to DAR but safety condition is not satisfied for China" 5 "Driver tries to release EPB by operating the switch without pressing the brake pedal" 6 "Driver tries to park in the N(Neutral) position" 7 "Driver tries to release EPB by operating the switch  in P gear" ;
VAL_ 2277634049 EPB_AlrmReq 0 "Off" 1 "Comfortable tone (Sound once)" 2 "Uncomfortable tone" 3 "Error Indicator" ;
VAL_ 2277634049 EPB_SwPosSta 0 "Neutral position" 1 "Apply position (pull)" 2 "Release position (push)" 3 "Switch failure" ;
VAL_ 2277634049 EPB_RrBrkLtActvReq 0 "No request" 1 "Request to turn on rear brake lights" 2 "Not used" 3 "Error Indicator" ;
VAL_ 2277634049 EPB_FrcErrSta 0 "No failure" 1 "Clamp position not reached" 2 "Emergency release" 3 "Force not measurable (e.g. sensor failure)" ;
VAL_ 2277634049 EPB_DynmBrkFrcReqSigSta 0 "EPB_DynmBrkFrcReqSigSta signal is invalid" 1 "EPB_DynmBrkFrcReqSigSta signal is valid" 2 "Not used" 3 "Error Indicator" ;
VAL_ 2277634049 EPB_FrcSta 0 "See details in EPB_FRC_ERR" 1 "Released" 2 "Clamped" 3 "Clamping in progress" 4 "Releasing in progress" 5 "Dynamic braking via EPB" 6 "Releasing in progress by switch" 7 "Clamping in progress by switch" ;
VAL_ 2277634049 EPB_FlSta 0 "Not valid" 1 "EPB No failure" 2 "EPB Initialization State" 3 "EPB Diagnostic" 4 "EPB Temporarily Not Available" 5 "EPB Permanently Not Available" ;
VAL_ 2277634049 EPB_EscReqAckSta 0 "Idle / No acknowledge" 1 "Acknowledge for external ESC request" 2 "Not used" 3 "Error Indicator" ;
VAL_ 2277634049 EPB_DynmBrkFrcReq 0 "No Request" 1 "Dynamic braking request" 2 "Not used" 3 "Error Indicator" ;
VAL_ 2277634049 EPB_EmerModReq 0 "EPB Initialization in Progress" 1 "Emergency EPB Mode Request" 2 "Normal EPB Mode Request" 3 "RESERVED" ;
VAL_ 2277634050 EPB_ActlFrcVal 0 "EPB Fully released" ;
VAL_ 2277634050 EPB_EpbSta4VcuReq 0 "Undefined (Initialization or Unknown State)" 1 "Clamped by VCU Parking Command" 2 "Moving for EPB applying or releasing" 3 "Release State by VCU Not Parking Command" 4 "Clamped with Single Actuator" 5 "RESERVED" 6 "RESERVED" 7 "RESERVED" ;
VAL_ 2277634050 eEPB_EpbSta4VcuReq 0 "Undefined (Initialization or Unknown State)" 1 "Clamped by VCU Parking Command" 2 "Moving for EPB applying or releasing" 3 "Release State by VCU Not Parking Command" ;
VAL_ 2277634050 eEPB_EPBSta 0 "eEPB Available" 1 "eEPB Not Available" 2 "eEPB Actuator Not Available" 3 "Reserved" ;
VAL_ 2277634050 EPB_EpbHWCtrlNeedReq 0 "None" 1 "EPB Initial Check Needed" 2 "EPB Operating Needed" 3 "RESERVED" ;
VAL_ 2277634050 EPB_EpbHwCtrState 0 "In-active (Mode Switch Off)" 1 "Active (Mode Switch On)" ;
VAL_ 2277634050 EPB_EpbActivated 0 "Not Activated" 1 "Activated" ;
VAL_ 2210462212 HCU_11sMaxSpdLimOperSta 0 "Max Speed Limit Inactive" 1 "Max Speed Limit Active" 2 "RESERVED" 3 "RESERVED" ;
VAL_ 883 HU_GNSS_TimeSource 0 "none" 1 "RTC" 2 "GPS(<10ms)" 3 "GPS(<1ms)" ;
VAL_ 883 HU_GNSS_search 0 "none" 1 "blind" 2 "anywhere" ;
VAL_ 883 HU_GNSS_DST 0 "DST OFF" 1 "DST ON" 2 "RESERVED" 3 "Invalid" ;
VAL_ 883 HU_GNSS_Fix_status 0 "Doing position fixes" 2 "need time" 3 "PDOP too high" 5 "No usable SVs" 6 "one usable SV" 7 "two usable SVs" 8 "three usable SVs" ;
VAL_ 721 HU_DR_Position_Status 1 "Valid" ;
VAL_ 721 HU_DR_Altitude_Status 1 "valid" ;
VAL_ 721 HU_DR_Heading_Status 1 "Valid" ;
VAL_ 721 HU_DR_Speed_Status 1 "Valid" ;
VAL_ 721 HU_DR_DirectionSwitch_Sta 1 "Valid" ;
VAL_ 721 HU_DR_Direction 1 "Backward" ;
VAL_ 721 HU_DR_GyroCalib_Sta 1 "Calibrated" ;
VAL_ 721 HU_DR_TachoCalib_Sta 1 "Calibrated" ;
VAL_ 721 HU_DR_Solution_Sta 0 "invalid" 1 "DR valid" ;
VAL_ 721 HU_DR_GNSS_Fix_Age 1 "0x0x1~0xFE:time since last GNSS fix" 254 "0x0x1~0xFE:time since last GNSS fix" 255 "No GNSS fix yet" ;
VAL_ 787 DPSU_DrvSlidePosition 0 "0x0x00~0xFE:POSITION" 254 "0x0x00~0xFE:POSITION" 255 "invalid" ;
VAL_ 787 DPSU_DrvHeightPosition 0 "0x0x00~0xFE:POSITION" 254 "0x0x00~0xFE:POSITION" 255 "invalid" ;
VAL_ 787 DPSU_DrvReclinePosition 0 "0x0x00~0xFE:POSITION" 254 "0x0x00~0xFE:POSITION" 255 "invalid" ;
VAL_ 787 DPSU_DrvRelaxTiltPosition 0 "0x0x00~0xFE:POSITION" 254 "0x0x00~0xFE:POSITION" 255 "invalid" ;
VAL_ 791 RCM_Crc4Val 0 "0x0x0~0xFF:CRCValue" 255 "0x0x0~0xFF:CRCValue" ;
VAL_ 791 RCM_AlvCnt4Val 0 "AlvCntValue" 1 "AlvCntValue" 2 "AlvCntValue" 3 "AlvCntValue" 4 "AlvCntValue" 5 "AlvCntValue" 6 "AlvCntValue" 7 "AlvCntValue" 8 "AlvCntValue" 9 "AlvCntValue" 10 "AlvCntValue" 11 "AlvCntValue" 12 "AlvCntValue" 13 "AlvCntValue" 14 "AlvCntValue" 15 "AlvCntValue" ;
VAL_ 791 RCM_RR_SunroofOpnSta 0 "Close" 1 "Open" 2 "Not Used" 3 "Error Indicator" ;
VAL_ 791 RCM_RR_GlsOpSta 0 "No Action" 1 "Opening" 2 "Closing" 3 "Error Indicator" ;
VAL_ 791 RCM_RR_GlsPosSta 0 "Full Close" 1 "BCT" 2 "TiltUp" 3 "BTO" 4 "BTO1(OPT)" 5 "BTO2(OPT)" 6 "Full Open" 7 "Undefined" 8 "Comfort Open" 9 "RESERVED" 10 "RESERVED" 11 "RESERVED" 12 "RESERVED" 13 "RESERVED" 14 "RESERVED" 15 "Invalid" ;
VAL_ 791 RCM_RR_GlsFltSta 0 "Normal (Initialized)" 1 "Fault" 2 "Not Initialized" 3 "Error Indicator" ;
VAL_ 792 RCM_Crc5Val 0 "0x0x0~0xFF:CRCValue" 255 "0x0x0~0xFF:CRCValue" ;
VAL_ 792 RCM_AlvCnt5Val 0 "AlvCntValue" 1 "AlvCntValue" 2 "AlvCntValue" 3 "AlvCntValue" 4 "AlvCntValue" 5 "AlvCntValue" 6 "AlvCntValue" 7 "AlvCntValue" 8 "AlvCntValue" 9 "AlvCntValue" 10 "AlvCntValue" 11 "AlvCntValue" 12 "AlvCntValue" 13 "AlvCntValue" 14 "AlvCntValue" 15 "AlvCntValue" ;
VAL_ 792 RCM_RR_BldPosSta 0 "Full Close" 1 "BCH" 2 "Half Open" 3 "BHO" 4 "Full Open" 5 "Undefined" 6 "Reserved" 7 "Invalid" ;
VAL_ 792 RCM_RR_BldFltSta 0 "Normal (Initialized)" 1 "Fault" 2 "Not Initialized" 3 "Error Indicator" ;
VAL_ 799 SBCM_DRV_Crc1Val 0 "0x0x0~0xFF:CRCValue" 255 "0x0x0~0xFF:CRCValue" ;
VAL_ 799 DRV_CrashUnlockCmd 0 "Off" 1 "Unlock(Crash)" ;
VAL_ 799 C_ApprOpenStatus 0 "Approach Open Off" 1 "Approach Open On" ;
VAL_ 799 SBCM_DRV_AlvCnt1Val 0 "AlvCntValue" 1 "AlvCntValue" 2 "AlvCntValue" 3 "AlvCntValue" 4 "AlvCntValue" 5 "AlvCntValue" 6 "AlvCntValue" 7 "AlvCntValue" 8 "AlvCntValue" 9 "AlvCntValue" 10 "AlvCntValue" 11 "AlvCntValue" 12 "AlvCntValue" 13 "AlvCntValue" 14 "AlvCntValue" 15 "AlvCntValue" ;
VAL_ 799 DoorLock_DrvKeyLkSwSta_SBCM 0 "Off" 1 "Lock" 2 "RESERVED" 3 "Error Indicator" ;
VAL_ 799 DoorLock_DrvKeyUnLkSwSta_SBCM 0 "Off" 1 "Unlock" 2 "RESERVED" 3 "Error Indicator" ;
VAL_ 799 Warn_DrvDrSwSta_SBCM 0 "Close" 1 "Open" 2 "RESERVED" 3 "Error Indicator" ;
VAL_ 799 DoorLock_DrvDrUnLkSta_SBCM 0 "Lock" 1 "Unlock" 2 "RESERVED" 3 "Error Indicator" ;
VAL_ 799 DRV_SEAWarn_LH 0 "SEA Left Warning OFF" 1 "SEA Left Warning ON" 2 "RESERVED" 3 "RESERVED" ;
VAL_ 799 DRV_SEAWarn_RH 0 "SEA Right Warning OFF" 1 "SEA Right  Warning ON" 2 "RESERVED" 3 "RESERVED" ;
VAL_ 799 DRV_SEWWarn_LH 0 "SEW Left Warning OFF" 1 "SEW Left Warning ON" 2 "RESERVED" 3 "RESERVED" ;
VAL_ 799 DRV_SEWWarn_RH 0 "SEW Right Warning OFF" 1 "SEW Right Warning ON" 2 "RESERVED" 3 "RESERVED" ;
VAL_ 799 DRV_MRActivationAlarm 0 "Off" 1 "On" 2 "RESERVED" 3 "Error Indicator" ;
VAL_ 799 DRV_ReleaseWarn 0 "Release Warning OFF" 1 "Release Warning ON" 2 "RESERVED" 3 "RESERVED" ;
VAL_ 799 Latch_TypeOption_DRV 0 "Off" 1 "On" 2 "RESERVED" 3 "Error Indicator" ;
VAL_ 799 DRV_SWFailAlarm 0 "Off" 1 "On" 2 "RESERVED" 3 "Error Indicator" ;
VAL_ 799 USM_PwrDRApprOpnSetSta 0 "Default" 1 "Off" 2 "On" 3 "RESERVED" ;
VAL_ 799 USM_PwrDRApprOpnSetOpt 0 "Default" 1 "Off" 2 "On" 3 "RESERVED" ;
VAL_ 799 USM_PwrDRCloseByRKELockSta 0 "Default" 1 "Off" 2 "On" 3 "RESERVED" ;
VAL_ 799 USM_PwrDRCloseByRKELockOpt 0 "Default" 1 "Off" 2 "On" 3 "RESERVED" ;
VAL_ 799 USM_PwrDRCloseByBrakeSta 0 "Default" 1 "Off" 2 "On" 3 "RESERVED" ;
VAL_ 799 USM_PwrDRCloseByBrakeOpt 0 "Default" 1 "Off" 2 "On" 3 "RESERVED" ;
VAL_ 799 USM_PwrDRBuzzerSta 0 "Default" 1 "Off" 2 "On" 3 "RESERVED" ;
VAL_ 799 USM_PwrDRBuzzerOpt 0 "Default" 1 "Off" 2 "On" 3 "RESERVED" ;
VAL_ 799 PDS_TypeOption_DRV 0 "Off" 1 "All Door" 2 "Front Only" 3 "Rear Only" ;
VAL_ 799 C_DrvDoorApproachOpen 0 "Default" 1 "Approach Open Request" 2 "Approach Open Stop" 3 "RESERVED" ;
VAL_ 799 C_DrvDoorApproachClose 0 "Default" 1 "Approach Close Request" 2 "Approach Close Stop" 3 "RESERVED" ;
VAL_ 799 DoorLock_PDSLkSwSta_DRV 0 "Default" 1 "Lock" 2 "RESERVED" 3 "Error Indicator" ;
VAL_ 799 DRVDoorPushAlarm 0 "Off" 1 "On" 2 "RESERVED" 3 "Error Indicator" ;
VAL_ 830 USM_CmdWPC2Sta 0 "Default" 1 "Off(Disable)" 2 "On(Enable)" 3 "Invalid" ;
VAL_ 830 WPC2_OptSta 0 "Default" 1 "Apply" 2 "RESERVED" 3 "Invalid" ;
VAL_ 830 WPC2_SWVerMajor1 0 "0x0x0~0x7F:ASCII Code Value (HEX)" 127 "0x0x0~0x7F:ASCII Code Value (HEX)" ;
VAL_ 830 WPC2_PhnLftWrngSta 0 "Off" 1 "Cellphone on the pad" 2 "Charging" 3 "Charging complete" 4 "Cellphone reminder" 5 "Error" 6 "NFC Card detected" 7 "Invalid" ;
VAL_ 830 WPC2_SWVerMinor1 0 "0x0x0~0x7F:ASCII Code Value (HEX)" 127 "0x0x0~0x7F:ASCII Code Value (HEX)" ;
VAL_ 830 WPC2_SWVerMinor2 0 "0x0x0~0x7F:ASCII Code Value (HEX)" 127 "0x0x0~0x7F:ASCII Code Value (HEX)" ;
VAL_ 830 WPC2_IndSyncVal 0 "default" 1 "off" 2 "1st sync" 3 "2nd sync" 4 "3rd sync" 5 "error off" 6 "error on" 7 "reserved" ;
